VERSION "dbc-export 1 2026.26.6.5"

NS_ :

BS_:

BU_: ADSP APB APP APS APSB BB BMS CC CMP CMPD CP DAS DI DIF DIR DPB EPAS3P EPAS3S EPASTP EPASTS EPBL EPBR ESP EVSE FC GTW HCML HCMR HVP IBST ICR IDB LS OCS1P PARK PCS PCS2 PM PMF PMR PNCD PTC RADC RCM RCM2 RCM3 RCU SCCM SCM SCS SDCR TAS TCU TCU2 TPMS TRCM UI UIS UMC USM V2G VC VCBATT VCBATT0 VCBATT1 VCBATT2 VCCC VCFRONT VCFRONT1 VCFRONT2 VCLEFT VCRIGHT VCSEAT2L VCSEAT2R VCSEC VEH

BO_ 738 VCLEFT_seatStatus2: 8 VCLEFT
 SG_ VCLEFT_seatStatus2Index M : 0|4@1+ (1,0) [0|15] "" Vector__XXX
 SG_ VCLEFT_frontSeatHeatCurrent m0 : 4|12@1+ (0.01,0) [0|40.95] "A" Vector__XXX
 SG_ VCLEFT_frontSeatHeatDuty m0 : 16|8@1+ (1,0) [0|255] "%" Vector__XXX
 SG_ VCLEFT_frontSeatHeatTmp m0 : 24|12@1- (0.05,0) [-40|80] "degC" Vector__XXX
 SG_ VCLEFT_frontSeatHeatTmpTarget m0 : 36|8@1- (0.5,0) [0|60] "degC" Vector__XXX
 SG_ VCLEFT_frontSeatHeatInhibited m0 : 44|1@1+ (1,0) [0|1] "" Vector__XXX
 SG_ VCLEFT_frontSeatHeatPowered m0 : 45|1@1+ (1,0) [0|1] "" Vector__XXX
 SG_ VCLEFT_2RowSeatFoldLeftSwitch m0 : 46|2@1+ (1,0) [0|3] "" Vector__XXX
 SG_ VCLEFT_2RowSeatUnfoldLeftSwitch m0 : 48|2@1+ (1,0) [0|3] "" Vector__XXX
 SG_ VCLEFT_2RowSeatFoldRightSwitch m0 : 50|2@1+ (1,0) [0|3] "" Vector__XXX
 SG_ VCLEFT_2RowSeatUnfoldRightSwitch m0 : 52|2@1+ (1,0) [0|3] "" Vector__XXX
 SG_ VCLEFT_3RowSeatFoldLeftSwitch m0 : 54|2@1+ (1,0) [0|3] "" Vector__XXX
 SG_ VCLEFT_3RowSeatUnfoldLeftSwitch m0 : 56|2@1+ (1,0) [0|3] "" Vector__XXX
 SG_ VCLEFT_3RowSeatFoldRightSwitch m0 : 58|2@1+ (1,0) [0|3] "" Vector__XXX
 SG_ VCLEFT_3RowSeatUnfoldRightSwitch m0 : 60|2@1+ (1,0) [0|3] "" Vector__XXX
 SG_ VC_AH_1RowLeftSeatHeatVentHealth m0 : 62|2@1+ (1,0) [0|3] "" Vector__XXX
 SG_ VCLEFT_2RowSeatReclineState m11 : 4|4@1+ (1,0) [0|15] "" Vector__XXX
 SG_ VCLEFT_2RowSeatReclineDuty m11 : 8|8@1- (1,0) [-100|100] "%" Vector__XXX
 SG_ VCLEFT_2RowSeatReclineCurrent m11 : 16|12@1- (0.05,0) [-100|100] "A" Vector__XXX
 SG_ VCLEFT_2RowSeatReclineCalibrated m11 : 28|1@1+ (1,0) [0|1] "" Vector__XXX
 SG_ VCLEFT_2RowSeatReclinePositionRa m11 : 29|12@1- (1,0) [-2048|2047] "" Vector__XXX
 SG_ VCLEFT_2RowSeatReclineAngle m11 : 41|12@1- (0.1,0) [-204.8|204.7] "deg" Vector__XXX
 SG_ VCLEFT_2RowSeatReclineAbsPosSwit m11 : 53|2@1+ (1,0) [0|3] "" Vector__XXX
 SG_ VCLEFT_2RowSeatReclinePositionSt m12 : 4|3@1+ (1,0) [0|7] "" Vector__XXX
 SG_ VCLEFT_2RowSeatReclineAdjustment m12 : 7|1@1+ (1,0) [0|1] "" Vector__XXX
 SG_ VCLEFT_2RowSeatReclineFoldAllowe m12 : 8|1@1+ (1,0) [0|1] "" Vector__XXX
 SG_ VCLEFT_2RowSeatReclineUnfoldAllo m12 : 9|1@1+ (1,0) [0|1] "" Vector__XXX
 SG_ VCLEFT_2RowSeatReclineNextToggle m12 : 10|2@1+ (1,0) [0|3] "" Vector__XXX
 SG_ VCLEFT_2RowSeatReclineChoreoBloc m12 : 12|1@1+ (1,0) [0|1] "" Vector__XXX
 SG_ VCLEFT_2RowSeat1RClashAvoidanceB m12 : 13|3@1+ (1,0) [0|7] "" Vector__XXX
 SG_ VCLEFT_2RowSeat1RClashAvoidanceS m12 : 16|2@1+ (1,0) [0|3] "" Vector__XXX
 SG_ VCLEFT_2RowSeatReclineAbsPo_0001 m12 : 18|12@1- (0.1,0) [-204.8|204.7] "deg" Vector__XXX
 SG_ VC_AH_2RowLeftSeatMovementHealth m12 : 61|3@1+ (1,0) [0|7] "" Vector__XXX
 SG_ VCLEFT_3RowSeatReclineState m14 : 4|4@1+ (1,0) [0|15] "" Vector__XXX
 SG_ VCLEFT_3RowSeatReclineDuty m14 : 8|8@1- (1,0) [-100|100] "%" Vector__XXX
 SG_ VCLEFT_3RowSeatReclineCurrent m14 : 16|12@1- (0.05,0) [-100|100] "A" Vector__XXX
 SG_ VCLEFT_3RowSeatReclineCalibrated m14 : 28|1@1+ (1,0) [0|1] "" Vector__XXX
 SG_ VCLEFT_3RowSeatReclinePositionRa m14 : 29|12@1- (1,0) [-2048|2047] "" Vector__XXX
 SG_ VCLEFT_3RowSeatReclineAngle m14 : 41|12@1- (0.1,0) [-204.8|204.7] "deg" Vector__XXX
 SG_ VCLEFT_3RowSeatReclineNextToggle m14 : 53|2@1+ (1,0) [0|3] "" Vector__XXX
 SG_ VCLEFT_3RRightCushionHeatCurrent m15 : 4|12@1+ (0.01,0) [0|40.95] "A" Vector__XXX
 SG_ VCLEFT_3RRightCushionHeatDuty m15 : 16|8@1- (1,0) [-100|100] "%" Vector__XXX
 SG_ VCLEFT_3RRightCushionHeatTmp m15 : 24|12@1- (0.05,0) [-40|80] "degC" Vector__XXX
 SG_ VCLEFT_3RRightCushionHeatTmpTarg m15 : 36|8@1- (0.5,0) [0|60] "degC" Vector__XXX
 SG_ VCLEFT_3RRightCushionHeatInhibit m15 : 44|1@1+ (1,0) [0|1] "" Vector__XXX
 SG_ VCLEFT_3RowSeatReclinePositionSt m15 : 46|3@1+ (1,0) [0|7] "" Vector__XXX
 SG_ VCLEFT_3RowSeatReclineAdjustment m15 : 49|1@1+ (1,0) [0|1] "" Vector__XXX
 SG_ VCLEFT_3RowSeatReclineFoldAllowe m15 : 50|1@1+ (1,0) [0|1] "" Vector__XXX
 SG_ VCLEFT_3RowSeatReclineUnfoldAllo m15 : 51|1@1+ (1,0) [0|1] "" Vector__XXX
 SG_ VCLEFT_3RowSeatReclineChoreoBloc m15 : 52|1@1+ (1,0) [0|1] "" Vector__XXX
 SG_ VCLEFT_3RowSeatReclineAbsPosSwit m15 : 53|2@1+ (1,0) [0|3] "" Vector__XXX

BO_ 930 VCLEFT_status: 8 VCLEFT
 SG_ VCLEFT_statusIndex M : 0|2@1+ (1,0) [0|3] "" Vector__XXX
 SG_ VCLEFT_securityControllerEnable m0 : 5|1@1+ (1,0) [0|1] "" Vector__XXX
 SG_ VCLEFT_securityControllerVoltage m0 : 6|5@1+ (0.625,0) [0|19.375] "V" Vector__XXX
 SG_ VCLEFT_consoleDoorAssist m0 : 11|1@1+ (1,0) [0|1] "" Vector__XXX
 SG_ VCLEFT_OTAState m0 : 12|1@1+ (1,0) [0|1] "" Vector__XXX
 SG_ VCLEFT_5AVoltage m0 : 13|10@1+ (0.005443676,0) [0|5.568880548] "V" Vector__XXX
 SG_ VCLEFT_vbatProt m0 : 23|12@1+ (0.005443676,0) [0|22.29185322] "V" Vector__XXX
 SG_ VCLEFT_footwellLightCurrent m0 : 35|12@1- (0.1,0) [-204.8|204.7] "mA" Vector__XXX
 SG_ VCLEFT_swcInputVoltage m0 : 47|8@1+ (0.1,0) [0|25.4] "V" Vector__XXX
 SG_ VCLEFT_swcPCBATemperature m0 : 55|8@1- (1,68) [-59|195] "degC" Vector__XXX
 SG_ VCLEFT_obdEthernetActive m0 : 63|1@1+ (1,0) [0|1] "" Vector__XXX
 SG_ VCLEFT_rationalityAggregateCurre m1 : 12|8@1+ (0.5,0) [0|127.5] "A" Vector__XXX
 SG_ VCLEFT_LVBatteryTypeDBG m1 : 20|3@1+ (1,0) [0|7] "" Vector__XXX
 SG_ VCLEFT_DIeFuseFault m1 : 24|1@1+ (1,0) [0|1] "" Vector__XXX
 SG_ VCLEFT_eFuseMgmtVoltageMonitor m1 : 25|7@1+ (0.125,0) [0|15.875] "V" Vector__XXX
 SG_ VCLEFT_trailerAuxCurrent m1 : 32|12@1+ (0.025,0) [0|102.35] "A" Vector__XXX
 SG_ VCLEFT_swcHeatTmp m1 : 44|10@1+ (0.1,-35) [-35|65] "degC" Vector__XXX
 SG_ VCLEFT_swcHeatStatus m1 : 54|3@1+ (1,0) [0|7] "" Vector__XXX
 SG_ VCLEFT_swcHeatInhibited m1 : 57|1@1+ (1,0) [0|1] "" Vector__XXX
 SG_ VCLEFT_obdDeviceDetected m1 : 58|1@1+ (1,0) [0|1] "" Vector__XXX
 SG_ VCLEFT_pcbaTemperature m2 : 4|11@1+ (0.125,-40) [-40|150] "degC" Vector__XXX
 SG_ VCLEFT_swcHeatPwr m2 : 15|9@1+ (0.5,0) [0|254] "W" Vector__XXX
 SG_ VCLEFT_swcHeatDutyCycle m2 : 24|7@1+ (1,0) [0|100] "%" Vector__XXX
 SG_ VCLEFT_DIeFuseCurrent m2 : 31|6@1+ (0.1,0) [0|6.3] "A" Vector__XXX
 SG_ VCLEFT_SWCpresent m2 : 37|1@1+ (1,0) [0|1] "" Vector__XXX
 SG_ VCLEFT_trailerBrakeControllerCur m2 : 38|8@1+ (0.1,0) [0|25.5] "A" Vector__XXX
 SG_ VCLEFT_autonomyBehaviorStatus m2 : 46|2@1+ (1,0) [0|3] "" Vector__XXX
 SG_ VCLEFT_thirdRowLeftMapLightStatu m2 : 48|2@1+ (1,0) [0|3] "" Vector__XXX
 SG_ VCLEFT_thirdRowRightMapLightStat m2 : 50|2@1+ (1,0) [0|3] "" Vector__XXX

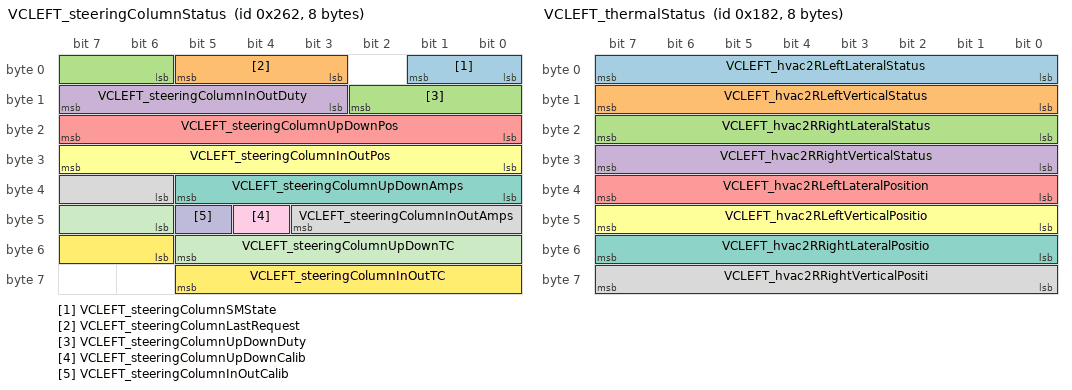
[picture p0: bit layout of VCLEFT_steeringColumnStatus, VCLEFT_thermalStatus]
BO_ 610 VCLEFT_steeringColumnStatus: 8 VCLEFT
 SG_ VCLEFT_steeringColumnSMState : 0|2@1+ (1,0) [0|3] "" Vector__XXX
 SG_ VCLEFT_steeringColumnLastRequest : 3|3@1+ (1,0) [0|7] "" Vector__XXX
 SG_ VCLEFT_steeringColumnUpDownDuty : 6|5@1- (7,0) [-100|100] "%" Vector__XXX
 SG_ VCLEFT_steeringColumnInOutDuty : 11|5@1- (7,0) [-100|100] "%" Vector__XXX
 SG_ VCLEFT_steeringColumnUpDownPos : 16|8@1- (1,103) [-25|230] "mm" Vector__XXX
 SG_ VCLEFT_steeringColumnInOutPos : 24|8@1- (1,103) [-25|230] "mm" Vector__XXX
 SG_ VCLEFT_steeringColumnUpDownAmps : 32|6@1- (0.63,0) [-20|19.53] "A" Vector__XXX
 SG_ VCLEFT_steeringColumnInOutAmps : 38|6@1- (0.63,0) [-20|19.53] "A" Vector__XXX
 SG_ VCLEFT_steeringColumnUpDownCalib : 44|1@1+ (1,0) [0|1] "" Vector__XXX
 SG_ VCLEFT_steeringColumnInOutCalib : 45|1@1+ (1,0) [0|1] "" Vector__XXX
 SG_ VCLEFT_steeringColumnUpDownTC : 46|8@1+ (0.5,-10) [-10|117.5] "s" Vector__XXX
 SG_ VCLEFT_steeringColumnInOutTC : 54|8@1+ (0.5,-10) [-10|117.5] "s" Vector__XXX

BO_ 962 VCLEFT_switchStatus: 8 VCLEFT
 SG_ VCLEFT_switchStatusIndex M : 0|1@1+ (1,0) [0|1] "" Vector__XXX
 SG_ VCLEFT_hornSwitchPressed m0 : 2|1@1+ (1,0) [0|1] "" Vector__XXX
 SG_ VCLEFT_hazardButtonPressed m0 : 3|1@1+ (1,0) [0|1] "" Vector__XXX
 SG_ VCLEFT_brakeSwitchPressed m0 : 4|1@1+ (1,0) [0|1] "" Vector__XXX
 SG_ VCLEFT_rightMirrorTilt m0 : 5|3@1+ (1,0) [0|7] "" Vector__XXX
 SG_ VCLEFT_frontSeatTrackBack m0 : 8|2@1+ (1,0) [0|3] "" Vector__XXX
 SG_ VCLEFT_frontSeatTrackForward m0 : 10|2@1+ (1,0) [0|3] "" Vector__XXX
 SG_ VCLEFT_frontSeatTiltDown m0 : 12|2@1+ (1,0) [0|3] "" Vector__XXX
 SG_ VCLEFT_frontSeatTiltUp m0 : 14|2@1+ (1,0) [0|3] "" Vector__XXX
 SG_ VCLEFT_frontSeatLiftDown m0 : 16|2@1+ (1,0) [0|3] "" Vector__XXX
 SG_ VCLEFT_frontSeatLiftUp m0 : 18|2@1+ (1,0) [0|3] "" Vector__XXX
 SG_ VCLEFT_frontSeatBackrestBack m0 : 20|2@1+ (1,0) [0|3] "" Vector__XXX
 SG_ VCLEFT_frontSeatBackrestForward m0 : 22|2@1+ (1,0) [0|3] "" Vector__XXX
 SG_ VCLEFT_frontSeatLumbarDown m0 : 24|2@1+ (1,0) [0|3] "" Vector__XXX
 SG_ VCLEFT_frontSeatLumbarUp m0 : 26|2@1+ (1,0) [0|3] "" Vector__XXX
 SG_ VCLEFT_frontSeatLumbarIn m0 : 28|2@1+ (1,0) [0|3] "" Vector__XXX
 SG_ VCLEFT_frontSeatLumbarOut m0 : 30|2@1+ (1,0) [0|3] "" Vector__XXX
 SG_ VCLEFT_btnWindowSwPackUpLF m0 : 32|1@1+ (1,0) [0|1] "" Vector__XXX
 SG_ VCLEFT_btnWindowSwPackAutoUpLF m0 : 33|1@1+ (1,0) [0|1] "" Vector__XXX
 SG_ VCLEFT_btnWindowSwPackDownLF m0 : 34|1@1+ (1,0) [0|1] "" Vector__XXX
 SG_ VCLEFT_btnWindowSwPackAutoDownLF m0 : 35|1@1+ (1,0) [0|1] "" Vector__XXX
 SG_ VCLEFT_btnWindowSwPackUpLR m0 : 36|1@1+ (1,0) [0|1] "" Vector__XXX
 SG_ VCLEFT_btnWindowSwPackAutoUpLR m0 : 37|1@1+ (1,0) [0|1] "" Vector__XXX
 SG_ VCLEFT_btnWindowSwPackDownLR m0 : 38|1@1+ (1,0) [0|1] "" Vector__XXX
 SG_ VCLEFT_btnWindowSwPackAutoDownLR m0 : 39|1@1+ (1,0) [0|1] "" Vector__XXX
 SG_ VCLEFT_btnWindowSwPackUpRF m0 : 40|1@1+ (1,0) [0|1] "" Vector__XXX
 SG_ VCLEFT_btnWindowSwPackAutoUpRF m0 : 41|1@1+ (1,0) [0|1] "" Vector__XXX
 SG_ VCLEFT_btnWindowSwPackDownRF m0 : 42|1@1+ (1,0) [0|1] "" Vector__XXX
 SG_ VCLEFT_btnWindowSwPackAutoDownRF m0 : 43|1@1+ (1,0) [0|1] "" Vector__XXX
 SG_ VCLEFT_btnWindowSwPackUpRR m0 : 44|1@1+ (1,0) [0|1] "" Vector__XXX
 SG_ VCLEFT_btnWindowSwPackAutoUpRR m0 : 45|1@1+ (1,0) [0|1] "" Vector__XXX
 SG_ VCLEFT_btnWindowSwPackDownRR m0 : 46|1@1+ (1,0) [0|1] "" Vector__XXX
 SG_ VCLEFT_btnWindowSwPackAutoDownRR m0 : 47|1@1+ (1,0) [0|1] "" Vector__XXX
 SG_ VCLEFT_frontBuckleSwitch m0 : 48|2@1+ (1,0) [0|3] "" Vector__XXX
 SG_ VCLEFT_frontOccupancySwitch m0 : 50|2@1+ (1,0) [0|3] "" Vector__XXX
 SG_ VCLEFT_rearLeftBuckleSwitch m0 : 52|2@1+ (1,0) [0|3] "" Vector__XXX
 SG_ VCLEFT_rearCenterOccupancySwitch m0 : 54|2@1+ (1,0) [0|3] "" Vector__XXX
 SG_ VCLEFT_rearLeftOccupancySwitch m0 : 56|2@1+ (1,0) [0|3] "" Vector__XXX
 SG_ VCLEFT_rearRightOccupancySwitch m0 : 58|2@1+ (1,0) [0|3] "" Vector__XXX
 SG_ VCLEFT_brakePressed m0 : 60|1@1+ (1,0) [0|1] "" Vector__XXX
 SG_ VCLEFT_rearHVACButtonPressed m0 : 61|1@1+ (1,0) [0|1] "" Vector__XXX
 SG_ VCLEFT_rearCenterBuckleSwitch m0 : 62|2@1+ (1,0) [0|3] "" Vector__XXX
 SG_ VCLEFT_isAlcoholInterlockSet m1 : 2|1@1+ (1,0) [0|1] "" Vector__XXX
 SG_ VCLEFT_swcLeftTiltRight m1 : 3|2@1+ (1,0) [0|3] "" Vector__XXX
 SG_ VCLEFT_swcLeftPressed m1 : 5|2@1+ (1,0) [0|3] "" Vector__XXX
 SG_ VCLEFT_swcRightTiltLeft m1 : 8|2@1+ (1,0) [0|3] "" Vector__XXX
 SG_ VCLEFT_swcRightTiltRight m1 : 10|2@1+ (1,0) [0|3] "" Vector__XXX
 SG_ VCLEFT_swcRightPressed m1 : 12|2@1+ (1,0) [0|3] "" Vector__XXX
 SG_ VCLEFT_swcLeftTiltLeft m1 : 14|2@1+ (1,0) [0|3] "" Vector__XXX
 SG_ VCLEFT_swcLeftScrollTicks m1 : 16|6@1- (1,0) [-32|31] "" Vector__XXX
 SG_ VCLEFT_swcWiperButtonState m1 : 22|2@1+ (1,0) [0|3] "" Vector__XXX
 SG_ VCLEFT_swcRightScrollTicks m1 : 24|6@1- (1,0) [-32|31] "" Vector__XXX
 SG_ VCLEFT_swcTurnSignalLeftButtonSt m1 : 30|2@1+ (1,0) [0|3] "" Vector__XXX
 SG_ VCLEFT_btnWindowUpLR m1 : 32|1@1+ (1,0) [0|1] "" Vector__XXX
 SG_ VCLEFT_btnWindowAutoUpLR m1 : 33|1@1+ (1,0) [0|1] "" Vector__XXX
 SG_ VCLEFT_btnWindowDownLR m1 : 34|1@1+ (1,0) [0|1] "" Vector__XXX
 SG_ VCLEFT_btnWindowAutoDownLR m1 : 35|1@1+ (1,0) [0|1] "" Vector__XXX
 SG_ VCLEFT_2RowSeatReclineSwitch m1 : 36|1@1+ (1,0) [0|1] "" Vector__XXX
 SG_ VCLEFT_2RowSeatCenterSwitch m1 : 37|1@1+ (1,0) [0|1] "" Vector__XXX
 SG_ VCLEFT_2RowSeatLeftFoldFlatSwitc m1 : 38|1@1+ (1,0) [0|1] "" Vector__XXX
 SG_ VCLEFT_2RowSeatRightFoldFlatSwit m1 : 39|1@1+ (1,0) [0|1] "" Vector__XXX
 SG_ VCLEFT_2RowSeatBothFoldFlatSwitc m1 : 40|1@1+ (1,0) [0|1] "" Vector__XXX
 SG_ VCLEFT_swcLeftDoublePress m1 : 41|1@1+ (1,0) [0|1] "" Vector__XXX
 SG_ VCLEFT_swcRightDoublePress m1 : 42|1@1+ (1,0) [0|1] "" Vector__XXX
 SG_ VCLEFT_2RowSeatBackrestFoldSwitc m1 : 43|1@1+ (1,0) [0|1] "" Vector__XXX
 SG_ VCLEFT_swcTurnSignalRightButtonS m1 : 44|2@1+ (1,0) [0|3] "" Vector__XXX
 SG_ VCLEFT_swcHighBeamButtonState m1 : 46|2@1+ (1,0) [0|3] "" Vector__XXX
 SG_ VCLEFT_swcVoiceControlPress m1 : 48|2@1+ (1,0) [0|3] "" Vector__XXX
 SG_ VCLEFT_swcCameraButtonState m1 : 50|2@1+ (1,0) [0|3] "" Vector__XXX
 SG_ VCLEFT_swcRightPressedQF m1 : 52|1@1+ (1,0) [0|1] "" Vector__XXX
 SG_ VCLEFT_2RowSeatReclineSwitchpack m1 : 53|3@1+ (1,0) [0|7] "" Vector__XXX
 SG_ VCLEFT_3RowLeftBuckleSwitch m1 : 56|2@1+ (1,0) [0|3] "" Vector__XXX
 SG_ VCLEFT_frontSeatThighSupportExte m1 : 58|2@1+ (1,0) [0|3] "" Vector__XXX
 SG_ VCLEFT_frontSeatThighSupportRetr m1 : 60|2@1+ (1,0) [0|3] "" Vector__XXX
 SG_ VCLEFT_frontSeatResistiveOccupan m1 : 62|2@1+ (1,0) [0|3] "" Vector__XXX

BO_ 656 VCLEFT_thermalLogging10Hz: 8 VCLEFT
 SG_ VCLEFT_thermalLogging10HzIndex M : 0|3@1+ (1,0) [0|7] "" Vector__XXX
 SG_ VCLEFT_hvac2RLeftLateralVoltage m2 : 8|8@1+ (0.02,0) [0|5] "V" Vector__XXX
 SG_ VCLEFT_hvac2RLeftVerticalVoltage m2 : 16|8@1+ (0.02,0) [0|5] "V" Vector__XXX
 SG_ VCLEFT_hvac2RRightLateralVoltage m2 : 24|8@1+ (0.02,0) [0|5] "V" Vector__XXX
 SG_ VCLEFT_hvac2RRightVerticalVoltag m2 : 32|8@1+ (0.02,0) [0|5] "V" Vector__XXX
 SG_ VCLEFT_hvac2RLeftLateralCalibrat m2 : 40|1@1+ (1,0) [0|1] "" Vector__XXX
 SG_ VCLEFT_hvac2RLeftVerticalCalibra m2 : 41|1@1+ (1,0) [0|1] "" Vector__XXX
 SG_ VCLEFT_hvac2RRightLateralCalibra m2 : 42|1@1+ (1,0) [0|1] "" Vector__XXX
 SG_ VCLEFT_hvac2RRightVerticalCalibr m2 : 43|1@1+ (1,0) [0|1] "" Vector__XXX
 SG_ VCLEFT_hvac2RLeftLateralState m2 : 44|4@1+ (1,0) [0|15] "" Vector__XXX
 SG_ VCLEFT_hvac2RLeftVerticalState m2 : 48|4@1+ (1,0) [0|15] "" Vector__XXX
 SG_ VCLEFT_hvac2RRightLateralState m2 : 52|4@1+ (1,0) [0|15] "" Vector__XXX
 SG_ VCLEFT_hvac2RRightVerticalState m2 : 56|4@1+ (1,0) [0|15] "" Vector__XXX
 SG_ VCLEFT_hvacBlowerWindmillElecRpm m3 : 3|14@1+ (1,0) [0|16383] "RPM" Vector__XXX
 SG_ VCLEFT_hvac2RRightVerticalVeloci m3 : 17|8@1- (1,0) [-100|100] "deg/s" Vector__XXX
 SG_ VCLEFT_hvacBlowerWindmillBemf m3 : 25|14@1+ (4,0) [0|65532] "mV" Vector__XXX
 SG_ VCLEFT_hvac2RLeftVerticalVelocit m3 : 39|8@1- (1,0) [-100|100] "deg/s" Vector__XXX
 SG_ VCLEFT_hvac2RLeftLateralVelocity m3 : 47|8@1- (1,0) [-100|100] "deg/s" Vector__XXX
 SG_ VCLEFT_vcusbLinSchedule m3 : 55|2@1+ (1,0) [0|3] "" Vector__XXX
 SG_ VCLEFT_hvacBlowerArbState m3 : 57|3@1+ (1,0) [0|7] "" Vector__XXX
 SG_ VCLEFT_hvacBlowerArbResult m3 : 60|2@1+ (1,0) [0|3] "" Vector__XXX
 SG_ VCLEFT_hvac2RLeftLateralDuty m4 : 3|8@1- (1,0) [-100|100] "%" Vector__XXX
 SG_ VCLEFT_hvac2RLeftVerticalDuty m4 : 11|8@1- (1,0) [-100|100] "%" Vector__XXX
 SG_ VCLEFT_hvac2RRightLateralDuty m4 : 19|8@1- (1,0) [-100|100] "%" Vector__XXX
 SG_ VCLEFT_hvac2RRightVerticalDuty m4 : 27|8@1- (1,0) [-100|100] "%" Vector__XXX
 SG_ VCLEFT_hvacBlowerWindmilling m4 : 35|1@1+ (1,0) [0|1] "" Vector__XXX
 SG_ VCLEFT_hvac2RRightLateralVelocit m4 : 36|8@1- (1,0) [-100|100] "deg/s" Vector__XXX
 SG_ VCLEFT_hvacBlower1msOverrunFrequ m4 : 44|10@1+ (1,0) [0|1023] "" Vector__XXX
 SG_ VCLEFT_hvacBlower10msOverrunFreq m4 : 54|7@1+ (1,0) [0|127] "" Vector__XXX

BO_ 657 VCLEFT_thermalLogging1Hz: 8 VCLEFT
 SG_ VCLEFT_thermalLogging1HzIndex M : 0|4@1+ (1,0) [0|15] "" Vector__XXX
 SG_ VCLEFT_hvac2RLeftLateralZeroStop m0 : 8|8@1+ (0.02,0) [0|5] "V" Vector__XXX
 SG_ VCLEFT_hvac2RLeftVerticalZeroSto m0 : 16|8@1+ (0.02,0) [0|5] "V" Vector__XXX
 SG_ VCLEFT_hvac2RRightLateralZeroSto m0 : 24|8@1+ (0.02,0) [0|5] "V" Vector__XXX
 SG_ VCLEFT_hvac2RRightVerticalZeroSt m0 : 32|8@1+ (0.02,0) [0|5] "V" Vector__XXX
 SG_ VCLEFT_hvac2RLeftLateralEndStopV m1 : 8|8@1+ (0.02,0) [0|5] "V" Vector__XXX
 SG_ VCLEFT_hvac2RLeftVerticalEndStop m1 : 16|8@1+ (0.02,0) [0|5] "V" Vector__XXX
 SG_ VCLEFT_hvac2RRightLateralEndStop m1 : 24|8@1+ (0.02,0) [0|5] "V" Vector__XXX
 SG_ VCLEFT_hvac2RRightVerticalEndSto m1 : 32|8@1+ (0.02,0) [0|5] "V" Vector__XXX
 SG_ VCLEFT_hvacBlowerArbCurrent m1 : 40|8@1+ (0.1,0) [0|25.5] "A" Vector__XXX
 SG_ VCLEFT_hvacBlowerTorqueIndexFilt m1 : 48|7@1+ (1,0) [0|127] "%" Vector__XXX

BO_ 386 VCLEFT_thermalStatus: 8 VCLEFT
 SG_ VCLEFT_hvac2RLeftLateralStatus : 0|8@1+ (1,0) [0|255] "" Vector__XXX
 SG_ VCLEFT_hvac2RLeftVerticalStatus : 8|8@1+ (1,0) [0|255] "" Vector__XXX
 SG_ VCLEFT_hvac2RRightLateralStatus : 16|8@1+ (1,0) [0|255] "" Vector__XXX
 SG_ VCLEFT_hvac2RRightVerticalStatus : 24|8@1+ (1,0) [0|255] "" Vector__XXX
 SG_ VCLEFT_hvac2RLeftLateralPosition : 32|8@1+ (0.4,0) [0|100] "%" Vector__XXX
 SG_ VCLEFT_hvac2RLeftVerticalPositio : 40|8@1+ (0.4,0) [0|100] "%" Vector__XXX
 SG_ VCLEFT_hvac2RRightLateralPositio : 48|8@1+ (0.4,0) [0|100] "%" Vector__XXX
 SG_ VCLEFT_hvac2RRightVerticalPositi : 56|8@1+ (0.4,0) [0|100] "%" Vector__XXX

BO_ 706 VCLEFT_windowStatus: 8 VCLEFT
 SG_ VCLEFT_windowStatusIndex M : 0|1@1+ (1,0) [0|1] "" Vector__XXX
 SG_ VCLEFT_windowStateLF m0 : 1|4@1+ (1,0) [0|15] "" Vector__XXX
 SG_ VCLEFT_windowTrimClearMoveReques m0 : 5|2@1+ (1,0) [0|3] "" Vector__XXX
 SG_ VCLEFT_windowDutyLF m0 : 8|6@1- (5,0) [-100|100] "%" Vector__XXX
 SG_ VCLEFT_windowTrimClearActiveRequ m0 : 14|2@1+ (1,0) [0|3] "" Vector__XXX
 SG_ VCLEFT_windowCurrentLF m0 : 16|6@1- (0.5,0) [-15|15] "A" Vector__XXX
 SG_ VCLEFT_windowPositionLF m0 : 22|9@1- (1.25,265) [-50|580] "mm" Vector__XXX
 SG_ VCLEFT_windowCalibratedLF m0 : 32|1@1+ (1,0) [0|1] "" Vector__XXX
 SG_ VCLEFT_windowStateLR m0 : 33|4@1+ (1,0) [0|15] "" Vector__XXX
 SG_ VCLEFT_windowDutyLR m0 : 40|6@1- (5,0) [-100|100] "%" Vector__XXX
 SG_ VCLEFT_windowCurrentLR m0 : 48|6@1- (0.5,0) [-15|15] "A" Vector__XXX
 SG_ VCLEFT_windowPositionLR m0 : 54|9@1- (1.25,265) [-50|580] "mm" Vector__XXX
 SG_ VCLEFT_windowCalibratedLR m0 : 63|1@1+ (1,0) [0|1] "" Vector__XXX
 SG_ VCLEFT_windowThermalTCLF m1 : 1|8@1+ (1,0) [0|255] "s" Vector__XXX
 SG_ VCLEFT_windowThermalModeLF m1 : 9|2@1+ (1,0) [0|3] "" Vector__XXX
 SG_ VCLEFT_windowStopReasonLF m1 : 11|3@1+ (1,0) [0|7] "" Vector__XXX
 SG_ VCLEFT_windowStopReqReasonLF m1 : 14|4@1+ (1,0) [0|15] "" Vector__XXX
 SG_ VCLEFT_windowThermalTCLR m1 : 18|8@1+ (1,0) [0|255] "s" Vector__XXX
 SG_ VCLEFT_windowThermalModeLR m1 : 26|2@1+ (1,0) [0|3] "" Vector__XXX
 SG_ VCLEFT_windowStopReasonLR m1 : 28|3@1+ (1,0) [0|7] "" Vector__XXX
 SG_ VCLEFT_windowStopReqReasonLR m1 : 31|4@1+ (1,0) [0|15] "" Vector__XXX
 SG_ VCLEFT_windowControlStateLF m1 : 35|2@1+ (1,0) [0|3] "" Vector__XXX
 SG_ VCLEFT_windowCtrlUnavailableLF m1 : 38|3@1+ (1,0) [0|7] "" Vector__XXX
 SG_ VCLEFT_windowControlStateLR m1 : 42|2@1+ (1,0) [0|3] "" Vector__XXX
 SG_ VCLEFT_windowCtrlUnavailableLR m1 : 45|3@1+ (1,0) [0|7] "" Vector__XXX
 SG_ VCLEFT_windowPositionStateLF m1 : 49|3@1+ (1,0) [0|7] "" Vector__XXX
 SG_ VCLEFT_windowPositionStateLR m1 : 52|3@1+ (1,0) [0|7] "" Vector__XXX
 SG_ VCLEFT_windowVehGearStateLF m1 : 56|2@1+ (1,0) [0|3] "" Vector__XXX
 SG_ VCLEFT_windowVehGearStateLR m1 : 58|2@1+ (1,0) [0|3] "" Vector__XXX
 SG_ VCLEFT_windowSpeedTableStatusLF m1 : 60|2@1+ (1,0) [0|3] "" Vector__XXX
 SG_ VCLEFT_windowSpeedTableStatusLR m1 : 62|2@1+ (1,0) [0|3] "" Vector__XXX

BO_ 1114 VCRIGHT_AP_hvacState10Hz: 8 VCRIGHT
 SG_ VCRIGHT_AP_hvacState10HzIndex M : 0|2@1+ (1,0) [0|3] "" Vector__XXX
 SG_ VCRIGHT_AP_autoDefogAvailable m0 : 2|1@1+ (1,0) [0|1] "" Vector__XXX
 SG_ VCRIGHT_AP_hvacFlashFoggingDetec m0 : 3|1@1+ (1,0) [0|1] "" Vector__XXX
 SG_ VCRIGHT_AP_hvacModelInitStatus m0 : 4|3@1+ (1,0) [0|7] "" Vector__XXX
 SG_ VCRIGHT_AP_cabinTempWindshield m0 : 7|8@1+ (0.5,-40) [-40|80] "degC" Vector__XXX
 SG_ VCRIGHT_AP_cabinTempSideGlassRig m0 : 15|8@1+ (0.5,-40) [-40|80] "degC" Vector__XXX
 SG_ VCRIGHT_AP_cabinTempSideGlassLef m0 : 23|8@1+ (0.5,-40) [-40|80] "degC" Vector__XXX
 SG_ VCRIGHT_AP_hvacRecircDoorPercent m0 : 31|6@1+ (1.6,0) [0|100] "%" Vector__XXX
 SG_ VCRIGHT_AP_hvacAirDistributionMo m0 : 37|3@1+ (1,0) [0|7] "" Vector__XXX
 SG_ VCRIGHT_AP_hvacEstimateWindshiel m0 : 40|8@1+ (1,0) [0|150] "%" Vector__XXX
 SG_ VCRIGHT_AP_hvacMassflowTarget m0 : 48|8@1+ (1,0) [0|200] "g/s" Vector__XXX
 SG_ VCRIGHT_AP_tempDuctDefrost m0 : 56|8@1+ (0.5,-22) [-22|105] "degC" Vector__XXX
 SG_ VCRIGHT_AP_cameraTurnOnTime m1 : 2|9@1+ (5,0) [0|2540] "min" Vector__XXX
 SG_ VCRIGHT_AP_cameraDefogType m1 : 11|3@1+ (1,0) [0|7] "" Vector__XXX
 SG_ VCRIGHT_ah_hvacFaultSurvivabilit m1 : 14|5@1+ (10,0) [0|300] "sec" Vector__XXX
 SG_ VCRIGHT_ah_defoggingTimeNeeded m1 : 19|5@1+ (1,0) [0|31] "min" Vector__XXX
 SG_ VCRIGHT_AP_cameraFanDutyRequest m1 : 24|7@1+ (1,0) [0|100] "%" Vector__XXX
 SG_ VCRIGHT_ah_defogSystemState m1 : 31|3@1+ (1,0) [0|7] "" Vector__XXX
 SG_ VCRIGHT_AP_turnForwardCameraHeat m1 : 34|4@1+ (1,0) [0|15] "" Vector__XXX
 SG_ VCRIGHT_AP_turnCameraFanOffReaso m1 : 38|3@1+ (1,0) [0|7] "" Vector__XXX
 SG_ VCRIGHT_AP_forwardCameraIntegrat m1 : 41|1@1+ (1,0) [0|1] "" Vector__XXX
 SG_ VCRIGHT_AP_solarFluxOnRightWindo m1 : 48|8@1+ (5,0) [0|1150] "W/m2" Vector__XXX
 SG_ VCRIGHT_AP_solarFluxOnLeftWindow m1 : 56|8@1+ (5,0) [0|1150] "W/m2" Vector__XXX

BO_ 1124 VCRIGHT_AP_hvacState1Hz: 8 VCRIGHT
 SG_ VCRIGHT_AP_hvacState1HzIndex M : 0|1@1+ (1,0) [0|1] "" Vector__XXX
 SG_ VCRIGHT_AP_tempCameraModele_0001 m0 : 2|8@1+ (0.5,-40) [-40|85] "degC" Vector__XXX
 SG_ VCRIGHT_AP_tempCameraModeledWind m0 : 10|8@1+ (0.5,-40) [-40|85] "degC" Vector__XXX
 SG_ VCRIGHT_AP_cameraModeledWin_0001 m0 : 18|7@1+ (1,0) [0|100] "%" Vector__XXX
 SG_ VCRIGHT_AP_cameraModeledWindshie m0 : 25|7@1+ (1,0) [0|100] "%" Vector__XXX
 SG_ VCRIGHT_AP_maxAchievableASideTem m0 : 32|7@1+ (1,-20) [-20|70] "degC" Vector__XXX
 SG_ VCRIGHT_AP_cameraModeledPocketWa m0 : 42|10@1+ (0.04,0) [0|40] "g/kg" Vector__XXX
 SG_ VCRIGHT_AP_humidityModelInitStat m0 : 52|5@1+ (1,0) [0|31] "" Vector__XXX
 SG_ VCRIGHT_AP_humidityModelStatus m0 : 57|5@1+ (1,0) [0|31] "" Vector__XXX

BO_ 549 VCRIGHT_LVPowerState: 8 VCRIGHT
 SG_ VCRIGHT_ptcLVState : 0|2@1+ (1,0) [0|3] "" Vector__XXX
 SG_ VCRIGHT_ocsLVState : 2|2@1+ (1,0) [0|3] "" Vector__XXX
 SG_ VCRIGHT_premAudioLVState : 4|2@1+ (1,0) [0|3] "" Vector__XXX
 SG_ VCRIGHT_rearOilPumpLVState : 6|2@1+ (1,0) [0|3] "" Vector__XXX
 SG_ VCRIGHT_tunerLVState : 8|2@1+ (1,0) [0|3] "" Vector__XXX
 SG_ VCRIGHT_hvcLVState : 10|2@1+ (1,0) [0|3] "" Vector__XXX
 SG_ VCRIGHT_rcmLVState : 12|2@1+ (1,0) [0|3] "" Vector__XXX
 SG_ VCRIGHT_lumbarLVState : 14|2@1+ (1,0) [0|3] "" Vector__XXX
 SG_ VCRIGHT_3RUSBPowered : 16|1@1+ (1,0) [0|1] "" Vector__XXX
 SG_ VCRIGHT_cntctrPwrState : 17|1@1+ (1,0) [0|1] "" Vector__XXX
 SG_ VCRIGHT_eFuseLockoutStatus : 18|2@1+ (1,0) [0|3] "" Vector__XXX
 SG_ VCRIGHT_swEnStatus : 20|1@1+ (1,0) [0|1] "" Vector__XXX
 SG_ VCRIGHT_vehiclePowerStateDBG : 21|2@1+ (1,0) [0|3] "" Vector__XXX
 SG_ VCRIGHT_parkLVState : 23|2@1+ (1,0) [0|3] "" Vector__XXX
 SG_ VCRIGHT_icrLVState : 25|2@1+ (1,0) [0|3] "" Vector__XXX
 SG_ VCRIGHT_interiorCameraLedLVState : 27|2@1+ (1,0) [0|3] "" Vector__XXX
 SG_ VCRIGHT_diLVState : 29|2@1+ (1,0) [0|3] "" Vector__XXX
 SG_ VCRIGHT_accDevicesDetected : 31|1@1+ (1,0) [0|1] "" Vector__XXX

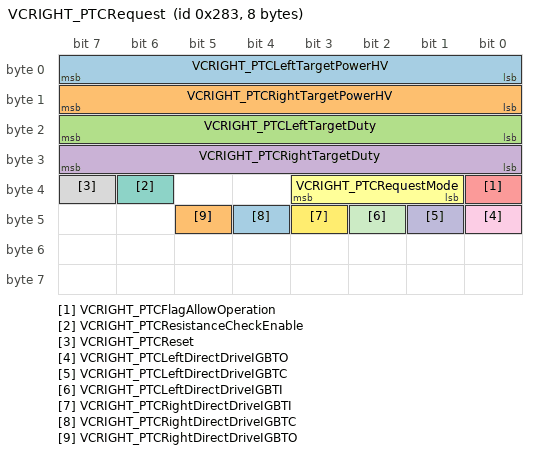
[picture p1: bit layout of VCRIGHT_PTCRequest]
BO_ 643 VCRIGHT_PTCRequest: 8 VCRIGHT
 SG_ VCRIGHT_PTCLeftTargetPowerHV : 0|8@1+ (30,0) [0|7650] "W" Vector__XXX
 SG_ VCRIGHT_PTCRightTargetPowerHV : 8|8@1+ (30,0) [0|7650] "W" Vector__XXX
 SG_ VCRIGHT_PTCLeftTargetDuty : 16|8@1+ (0.5,0) [0|100] "%" Vector__XXX
 SG_ VCRIGHT_PTCRightTargetDuty : 24|8@1+ (0.5,0) [0|100] "%" Vector__XXX
 SG_ VCRIGHT_PTCFlagAllowOperation : 32|1@1+ (1,0) [0|1] "" Vector__XXX
 SG_ VCRIGHT_PTCRequestMode : 33|3@1+ (1,0) [0|7] "" Vector__XXX
 SG_ VCRIGHT_PTCResistanceCheckEnable : 38|1@1+ (1,0) [0|1] "" Vector__XXX
 SG_ VCRIGHT_PTCReset : 39|1@1+ (1,0) [0|1] "" Vector__XXX
 SG_ VCRIGHT_PTCLeftDirectDriveIGBTO : 40|1@1+ (1,0) [0|1] "" Vector__XXX
 SG_ VCRIGHT_PTCLeftDirectDriveIGBTC : 41|1@1+ (1,0) [0|1] "" Vector__XXX
 SG_ VCRIGHT_PTCLeftDirectDriveIGBTI : 42|1@1+ (1,0) [0|1] "" Vector__XXX
 SG_ VCRIGHT_PTCRightDirectDriveIGBTI : 43|1@1+ (1,0) [0|1] "" Vector__XXX
 SG_ VCRIGHT_PTCRightDirectDriveIGBTC : 44|1@1+ (1,0) [0|1] "" Vector__XXX
 SG_ VCRIGHT_PTCRightDirectDriveIGBTO : 45|1@1+ (1,0) [0|1] "" Vector__XXX

BO_ 2011 VCRIGHT_alertLog: 8 VCRIGHT
 SG_ VCRIGHT_alertID M : 0|10@1+ (1,0) [0|1023] "" Vector__XXX
 SG_ VCRIGHT_alertState : 15|1@1+ (1,0) [0|1] "" Vector__XXX
 SG_ VCRIGHT_a001_InternalWatchdog m1 : 16|1@1+ (1,0) [0|1] "" Vector__XXX
 SG_ VCRIGHT_a010_UnderVoltageDetecte m10 : 16|1@1+ (1,0) [0|1] "" Vector__XXX
 SG_ VCRIGHT_a010_UnderVoltageTimeout m10 : 17|1@1+ (1,0) [0|1] "" Vector__XXX
 SG_ VCRIGHT_a015_NVMMMemOverflow m15 : 16|1@1+ (1,0) [0|1] "" Vector__XXX
 SG_ VCRIGHT_a015_NVMMFilesystemError m15 : 17|1@1+ (1,0) [0|1] "" Vector__XXX
 SG_ VCRIGHT_a015_NVMMRecordIDError m15 : 18|1@1+ (1,0) [0|1] "" Vector__XXX
 SG_ VCRIGHT_a057_VEH_cpControl m57 : 16|1@1+ (1,0) [0|1] "" Vector__XXX
 SG_ VCRIGHT_a059_voltageDrop m59 : 16|12@1+ (0.005443676,0) [0|22.29185322] "" Vector__XXX
 SG_ VCRIGHT_a059_resistanceEstimate m59 : 28|12@1+ (0.00244,0) [0|9.9918] "" Vector__XXX
 SG_ VCRIGHT_a059_current m59 : 40|12@1+ (0.05,0) [0|204.75] "" Vector__XXX
 SG_ VCRIGHT_a063_switchChannel m63 : 16|8@1+ (1,0) [0|255] "" Vector__XXX
 SG_ VCRIGHT_a063_switchType m63 : 24|8@1+ (1,0) [0|255] "" Vector__XXX
 SG_ VCRIGHT_a063_ADCVoltage m63 : 32|8@1+ (0.025,0) [0|6.375] "" Vector__XXX
 SG_ VCRIGHT_a063_disconnected m63 : 40|1@1+ (1,0) [0|1] "" Vector__XXX
 SG_ VCRIGHT_a063_indeterminate m63 : 41|1@1+ (1,0) [0|1] "" Vector__XXX
 SG_ VCRIGHT_a063_stuckActive m63 : 42|1@1+ (1,0) [0|1] "" Vector__XXX
 SG_ VCRIGHT_a063_faulted m63 : 43|1@1+ (1,0) [0|1] "" Vector__XXX
 SG_ VCRIGHT_a082_RIPC_epbPrivateStat m82 : 16|1@1+ (1,0) [0|1] "" Vector__XXX
 SG_ VCRIGHT_a082_RIPC_remoteHSD m82 : 17|1@1+ (1,0) [0|1] "" Vector__XXX
 SG_ VCRIGHT_a082_RIPC_railStatus m82 : 18|1@1+ (1,0) [0|1] "" Vector__XXX
 SG_ VCRIGHT_a082_RIPC_remoteMux m82 : 19|1@1+ (1,0) [0|1] "" Vector__XXX
 SG_ VCRIGHT_a083_LIPC_epbPrivateStat m83 : 16|1@1+ (1,0) [0|1] "" Vector__XXX
 SG_ VCRIGHT_a083_LIPC_remoteHSD m83 : 17|1@1+ (1,0) [0|1] "" Vector__XXX
 SG_ VCRIGHT_a083_LIPC_railStatus m83 : 18|1@1+ (1,0) [0|1] "" Vector__XXX
 SG_ VCRIGHT_a083_LIPC_HSDFaults m83 : 19|1@1+ (1,0) [0|1] "" Vector__XXX
 SG_ VCRIGHT_a084_CH_StatusC m84 : 16|1@1+ (1,0) [0|1] "" Vector__XXX
 SG_ VCRIGHT_a085_PARTY_buttonStatus m85 : 16|1@1+ (1,0) [0|1] "" Vector__XXX
 SG_ VCRIGHT_a086_VEH_LVBMS_statusHig m86 : 16|1@1+ (1,0) [0|1] "" Vector__XXX
 SG_ VCRIGHT_a086_VEH_LVBMS_statusLow m86 : 17|1@1+ (1,0) [0|1] "" Vector__XXX
 SG_ VCRIGHT_a086_VEH_status m86 : 18|1@1+ (1,0) [0|1] "" Vector__XXX
 SG_ VCRIGHT_a086_VEH_12VBatteryStatu m86 : 19|1@1+ (1,0) [0|1] "" Vector__XXX
 SG_ VCRIGHT_a086_VEH_LVPowerState m86 : 20|1@1+ (1,0) [0|1] "" Vector__XXX
 SG_ VCRIGHT_a086_VEH_lightStatus m86 : 21|1@1+ (1,0) [0|1] "" Vector__XXX
 SG_ VCRIGHT_a086_VEH_systemStatus m86 : 22|1@1+ (1,0) [0|1] "" Vector__XXX
 SG_ VCRIGHT_a086_VEH_thermalStatus m86 : 23|1@1+ (1,0) [0|1] "" Vector__XXX
 SG_ VCRIGHT_a086_VEH_vehNm m86 : 24|1@1+ (1,0) [0|1] "" Vector__XXX
 SG_ VCRIGHT_a086_BDY_LVSelfTests m86 : 60|1@1+ (1,0) [0|1] "" Vector__XXX
 SG_ VCRIGHT_a086_VEH_LVSelfTests m86 : 61|1@1+ (1,0) [0|1] "" Vector__XXX
 SG_ VCRIGHT_a086_VEH_LVHealth m86 : 62|1@1+ (1,0) [0|1] "" Vector__XXX
 SG_ VCRIGHT_a086_BDY_12VBatteryStatu m86 : 63|1@1+ (1,0) [0|1] "" Vector__XXX
 SG_ VCRIGHT_a087_VEH_temperature m87 : 16|1@1+ (1,0) [0|1] "" Vector__XXX
 SG_ VCRIGHT_a087_VEH_thermalControl m87 : 17|1@1+ (1,0) [0|1] "" Vector__XXX
 SG_ VCRIGHT_a087_VEH_torque m87 : 18|1@1+ (1,0) [0|1] "" Vector__XXX
 SG_ VCRIGHT_a087_VEH_status m87 : 19|1@1+ (1,0) [0|1] "" Vector__XXX
 SG_ VCRIGHT_a087_PARTY_torque m87 : 20|1@1+ (1,0) [0|1] "" Vector__XXX
 SG_ VCRIGHT_a087_PARTY_status m87 : 21|1@1+ (1,0) [0|1] "" Vector__XXX
 SG_ VCRIGHT_a087_PARTY_temperature m87 : 22|1@1+ (1,0) [0|1] "" Vector__XXX
 SG_ VCRIGHT_a087_PARTY_thermalContro m87 : 23|1@1+ (1,0) [0|1] "" Vector__XXX
 SG_ VCRIGHT_a087_VEH_motorStatus m87 : 24|1@1+ (1,0) [0|1] "" Vector__XXX
 SG_ VCRIGHT_a088_VEH_temperature m88 : 16|1@1+ (1,0) [0|1] "" Vector__XXX
 SG_ VCRIGHT_a088_VEH_thermalControl m88 : 17|1@1+ (1,0) [0|1] "" Vector__XXX
 SG_ VCRIGHT_a088_VEH_torque m88 : 18|1@1+ (1,0) [0|1] "" Vector__XXX
 SG_ VCRIGHT_a088_VEH_status m88 : 19|1@1+ (1,0) [0|1] "" Vector__XXX
 SG_ VCRIGHT_a088_PARTY_torque m88 : 20|1@1+ (1,0) [0|1] "" Vector__XXX
 SG_ VCRIGHT_a088_PARTY_status m88 : 21|1@1+ (1,0) [0|1] "" Vector__XXX
 SG_ VCRIGHT_a088_PARTY_temperature m88 : 22|1@1+ (1,0) [0|1] "" Vector__XXX
 SG_ VCRIGHT_a088_PARTY_thermalContro m88 : 23|1@1+ (1,0) [0|1] "" Vector__XXX
 SG_ VCRIGHT_a088_VEH_motorStatus m88 : 24|1@1+ (1,0) [0|1] "" Vector__XXX
 SG_ VCRIGHT_a089_PARTY_party1 m89 : 16|1@1+ (1,0) [0|1] "" Vector__XXX
 SG_ VCRIGHT_a089_PARTY_status m89 : 17|1@1+ (1,0) [0|1] "" Vector__XXX
 SG_ VCRIGHT_a089_VEH_status m89 : 18|1@1+ (1,0) [0|1] "" Vector__XXX
 SG_ VCRIGHT_a089_BDY_party1 m89 : 19|1@1+ (1,0) [0|1] "" Vector__XXX
 SG_ VCRIGHT_a089_BDY_status m89 : 20|1@1+ (1,0) [0|1] "" Vector__XXX
 SG_ VCRIGHT_a089_CH_status m89 : 21|1@1+ (1,0) [0|1] "" Vector__XXX
 SG_ VCRIGHT_a089_CH_party1 m89 : 22|1@1+ (1,0) [0|1] "" Vector__XXX
 SG_ VCRIGHT_a089_CH_party3 m89 : 23|1@1+ (1,0) [0|1] "" Vector__XXX
 SG_ VCRIGHT_a089_VEH_party1 m89 : 24|1@1+ (1,0) [0|1] "" Vector__XXX
 SG_ VCRIGHT_a089_VEH_party3 m89 : 25|1@1+ (1,0) [0|1] "" Vector__XXX
 SG_ VCRIGHT_a091_VEH_faultsAndExtras m91 : 16|1@1+ (1,0) [0|1] "" Vector__XXX
 SG_ VCRIGHT_a091_VEH_info m91 : 17|1@1+ (1,0) [0|1] "" Vector__XXX
 SG_ VCRIGHT_a091_VEH_state m91 : 18|1@1+ (1,0) [0|1] "" Vector__XXX
 SG_ VCRIGHT_a092_VEH_restraintStatus m92 : 16|1@1+ (1,0) [0|1] "" Vector__XXX
 SG_ VCRIGHT_a092_VEH_switchStatus m92 : 17|1@1+ (1,0) [0|1] "" Vector__XXX
 SG_ VCRIGHT_a092_VEH_seatStatus2 m92 : 18|1@1+ (1,0) [0|1] "" Vector__XXX
 SG_ VCRIGHT_a092_VEH_vehNm m92 : 19|1@1+ (1,0) [0|1] "" Vector__XXX
 SG_ VCRIGHT_a093_VEH_restraintStatus m93 : 16|1@1+ (1,0) [0|1] "" Vector__XXX
 SG_ VCRIGHT_a093_VEH_switchStatus m93 : 17|1@1+ (1,0) [0|1] "" Vector__XXX
 SG_ VCRIGHT_a093_VEH_seatStatus2 m93 : 18|1@1+ (1,0) [0|1] "" Vector__XXX
 SG_ VCRIGHT_a093_VEH_vehNm m93 : 19|1@1+ (1,0) [0|1] "" Vector__XXX
 SG_ VCRIGHT_a094_VEH_sysStatus m94 : 16|1@1+ (1,0) [0|1] "" Vector__XXX
 SG_ VCRIGHT_a094_PARTY_sysStatus m94 : 17|1@1+ (1,0) [0|1] "" Vector__XXX
 SG_ VCRIGHT_a094_CH_sysStatus m94 : 18|1@1+ (1,0) [0|1] "" Vector__XXX
 SG_ VCRIGHT_a095_PT_ptNm m95 : 16|1@1+ (1,0) [0|1] "" Vector__XXX
 SG_ VCRIGHT_a095_PT_status m95 : 17|1@1+ (1,0) [0|1] "" Vector__XXX
 SG_ VCRIGHT_a096_VEH_status m96 : 16|1@1+ (1,0) [0|1] "" Vector__XXX
 SG_ VCRIGHT_a096_CH_status m96 : 17|1@1+ (1,0) [0|1] "" Vector__XXX
 SG_ VCRIGHT_a097_VEH_HVStatus m97 : 16|1@1+ (1,0) [0|1] "" Vector__XXX
 SG_ VCRIGHT_a097_VEH_state m97 : 17|1@1+ (1,0) [0|1] "" Vector__XXX
 SG_ VCRIGHT_a098_CH_torque m98 : 16|1@1+ (1,0) [0|1] "" Vector__XXX
 SG_ VCRIGHT_a098_VEH_hvStatus m98 : 17|1@1+ (1,0) [0|1] "" Vector__XXX
 SG_ VCRIGHT_a098_VEH_status m98 : 18|1@1+ (1,0) [0|1] "" Vector__XXX
 SG_ VCRIGHT_a098_VEH_thermalControl m98 : 19|1@1+ (1,0) [0|1] "" Vector__XXX
 SG_ VCRIGHT_a098_VEH_temperature m98 : 20|1@1+ (1,0) [0|1] "" Vector__XXX
 SG_ VCRIGHT_a098_VEH_torque m98 : 21|1@1+ (1,0) [0|1] "" Vector__XXX
 SG_ VCRIGHT_a098_PARTY_status m98 : 22|1@1+ (1,0) [0|1] "" Vector__XXX
 SG_ VCRIGHT_a098_PARTY_temperature m98 : 23|1@1+ (1,0) [0|1] "" Vector__XXX
 SG_ VCRIGHT_a098_PARTY_thermalContro m98 : 24|1@1+ (1,0) [0|1] "" Vector__XXX
 SG_ VCRIGHT_a098_PARTY_torque m98 : 25|1@1+ (1,0) [0|1] "" Vector__XXX
 SG_ VCRIGHT_a098_PT_thermalControl m98 : 26|1@1+ (1,0) [0|1] "" Vector__XXX
 SG_ VCRIGHT_a098_PT_temperature m98 : 27|1@1+ (1,0) [0|1] "" Vector__XXX
 SG_ VCRIGHT_a098_PARTY_motorStatus m98 : 28|1@1+ (1,0) [0|1] "" Vector__XXX
 SG_ VCRIGHT_a098_VEH_motorStatus m98 : 29|1@1+ (1,0) [0|1] "" Vector__XXX
 SG_ VCRIGHT_a099_VEH_oocStatus m99 : 16|1@1+ (1,0) [0|1] "" Vector__XXX
 SG_ VCRIGHT_a100_VEH m100 : 16|1@1+ (1,0) [0|1] "" Vector__XXX
 SG_ VCRIGHT_a100_PARTY m100 : 17|1@1+ (1,0) [0|1] "" Vector__XXX
 SG_ VCRIGHT_a100_PT m100 : 18|1@1+ (1,0) [0|1] "" Vector__XXX
 SG_ VCRIGHT_a100_CH m100 : 19|1@1+ (1,0) [0|1] "" Vector__XXX
 SG_ VCRIGHT_a100_OBD m100 : 20|1@1+ (1,0) [0|1] "" Vector__XXX
 SG_ VCRIGHT_a101_VEH_state m101 : 16|1@1+ (1,0) [0|1] "" Vector__XXX
 SG_ VCRIGHT_a101_PARTY_locState m101 : 17|1@1+ (1,0) [0|1] "" Vector__XXX
 SG_ VCRIGHT_a101_LIPC_externalWatchd m101 : 18|1@1+ (1,0) [0|1] "" Vector__XXX
 SG_ VCRIGHT_a101_VEH_locState m101 : 19|1@1+ (1,0) [0|1] "" Vector__XXX
 SG_ VCRIGHT_a101_BDY_locState m101 : 20|1@1+ (1,0) [0|1] "" Vector__XXX
 SG_ VCRIGHT_a102_VEH_faultsAndExtras m102 : 16|1@1+ (1,0) [0|1] "" Vector__XXX
 SG_ VCRIGHT_a102_VEH_feedbackStatus m102 : 17|1@1+ (1,0) [0|1] "" Vector__XXX
 SG_ VCRIGHT_a102_VEH_sensorStatus m102 : 18|1@1+ (1,0) [0|1] "" Vector__XXX
 SG_ VCRIGHT_a102_VEH_rods m102 : 19|1@1+ (1,0) [0|1] "" Vector__XXX
 SG_ VCRIGHT_a103_VEH_hvsNm m103 : 16|1@1+ (1,0) [0|1] "" Vector__XXX
 SG_ VCRIGHT_a103_VEH_vehNm m103 : 17|1@1+ (1,0) [0|1] "" Vector__XXX
 SG_ VCRIGHT_a103_VEH_status m103 : 18|1@1+ (1,0) [0|1] "" Vector__XXX
 SG_ VCRIGHT_a103_PT_ptNm m103 : 19|1@1+ (1,0) [0|1] "" Vector__XXX
 SG_ VCRIGHT_a103_PT_status m103 : 20|1@1+ (1,0) [0|1] "" Vector__XXX
 SG_ VCRIGHT_a103_VEH_evseStatus m103 : 21|1@1+ (1,0) [0|1] "" Vector__XXX
 SG_ VCRIGHT_a105_VEH_states m105 : 16|1@1+ (1,0) [0|1] "" Vector__XXX
 SG_ VCRIGHT_a105_VEH_chNm m105 : 17|1@1+ (1,0) [0|1] "" Vector__XXX
 SG_ VCRIGHT_a105_VEH_dampingStates m105 : 18|1@1+ (1,0) [0|1] "" Vector__XXX
 SG_ VCRIGHT_a106_VEH_dcdcStatus m106 : 16|1@1+ (1,0) [0|1] "" Vector__XXX
 SG_ VCRIGHT_a106_VEH_thermalControl m106 : 17|1@1+ (1,0) [0|1] "" Vector__XXX
 SG_ VCRIGHT_a106_VEH_dcdcRailStatus m106 : 18|1@1+ (1,0) [0|1] "" Vector__XXX
 SG_ VCRIGHT_a106_CH_dcdcRailStatus m106 : 19|1@1+ (1,0) [0|1] "" Vector__XXX
 SG_ VCRIGHT_a106_CH_alertMatrix m106 : 20|1@1+ (1,0) [0|1] "" Vector__XXX
 SG_ VCRIGHT_a107_VEH_hvsNm m107 : 16|1@1+ (1,0) [0|1] "" Vector__XXX
 SG_ VCRIGHT_a107_VEH_vehNm m107 : 17|1@1+ (1,0) [0|1] "" Vector__XXX
 SG_ VCRIGHT_a107_VEH_status m107 : 18|1@1+ (1,0) [0|1] "" Vector__XXX
 SG_ VCRIGHT_a107_VEH_thermalStatus m107 : 19|1@1+ (1,0) [0|1] "" Vector__XXX
 SG_ VCRIGHT_a107_VEH_bmbMinMax m107 : 20|1@1+ (1,0) [0|1] "" Vector__XXX
 SG_ VCRIGHT_a107_VEH_powerAvailable m107 : 21|1@1+ (1,0) [0|1] "" Vector__XXX
 SG_ VCRIGHT_a107_PT_ptNm m107 : 22|1@1+ (1,0) [0|1] "" Vector__XXX
 SG_ VCRIGHT_a107_PT_status m107 : 23|1@1+ (1,0) [0|1] "" Vector__XXX
 SG_ VCRIGHT_a107_PT_thermalStatus m107 : 24|1@1+ (1,0) [0|1] "" Vector__XXX
 SG_ VCRIGHT_a107_PT_socStatus m107 : 25|1@1+ (1,0) [0|1] "" Vector__XXX
 SG_ VCRIGHT_a107_VEH_socStatus m107 : 26|1@1+ (1,0) [0|1] "" Vector__XXX
 SG_ VCRIGHT_a107_VEH_packConfig m107 : 27|1@1+ (1,0) [0|1] "" Vector__XXX
 SG_ VCRIGHT_a107_VEH_energyStatus m107 : 28|1@1+ (1,0) [0|1] "" Vector__XXX
 SG_ VCRIGHT_a107_VEH_chargeInfo m107 : 29|1@1+ (1,0) [0|1] "" Vector__XXX
 SG_ VCRIGHT_a108_VEH_hvStatus m108 : 16|1@1+ (1,0) [0|1] "" Vector__XXX
 SG_ VCRIGHT_a108_VEH_temperature m108 : 17|1@1+ (1,0) [0|1] "" Vector__XXX
 SG_ VCRIGHT_a108_VEH_thermalControl m108 : 18|1@1+ (1,0) [0|1] "" Vector__XXX
 SG_ VCRIGHT_a108_VEH_torque m108 : 19|1@1+ (1,0) [0|1] "" Vector__XXX
 SG_ VCRIGHT_a108_VEH_status m108 : 20|1@1+ (1,0) [0|1] "" Vector__XXX
 SG_ VCRIGHT_a108_PARTY_torque m108 : 21|1@1+ (1,0) [0|1] "" Vector__XXX
 SG_ VCRIGHT_a108_PARTY_status m108 : 22|1@1+ (1,0) [0|1] "" Vector__XXX
 SG_ VCRIGHT_a108_PARTY_temperature m108 : 23|1@1+ (1,0) [0|1] "" Vector__XXX
 SG_ VCRIGHT_a108_PARTY_thermalContro m108 : 24|1@1+ (1,0) [0|1] "" Vector__XXX
 SG_ VCRIGHT_a108_PT_temperature m108 : 25|1@1+ (1,0) [0|1] "" Vector__XXX
 SG_ VCRIGHT_a108_PT_thermalControl m108 : 26|1@1+ (1,0) [0|1] "" Vector__XXX
 SG_ VCRIGHT_a108_PARTY_motorStatus m108 : 27|1@1+ (1,0) [0|1] "" Vector__XXX
 SG_ VCRIGHT_a108_VEH_motorStatus m108 : 28|1@1+ (1,0) [0|1] "" Vector__XXX
 SG_ VCRIGHT_a108_CH_torque m108 : 29|1@1+ (1,0) [0|1] "" Vector__XXX
 SG_ VCRIGHT_a110_VEH_carState m110 : 16|1@1+ (1,0) [0|1] "" Vector__XXX
 SG_ VCRIGHT_a110_VEH_carConfig m110 : 17|1@1+ (1,0) [0|1] "" Vector__XXX
 SG_ VCRIGHT_a110_VEH_time m110 : 18|1@1+ (1,0) [0|1] "" Vector__XXX
 SG_ VCRIGHT_a110_VEH_updateStatus m110 : 19|1@1+ (1,0) [0|1] "" Vector__XXX
 SG_ VCRIGHT_a110_VEH_vehNm m110 : 20|1@1+ (1,0) [0|1] "" Vector__XXX
 SG_ VCRIGHT_a110_VEH_mismatchFault m110 : 21|1@1+ (1,0) [0|1] "" Vector__XXX
 SG_ VCRIGHT_a110_VEH_vin m110 : 22|1@1+ (1,0) [0|1] "" Vector__XXX
 SG_ VCRIGHT_a110_VEH_bmpDebug m110 : 23|1@1+ (1,0) [0|1] "" Vector__XXX
 SG_ VCRIGHT_a110_VEH_gearControl m110 : 24|1@1+ (1,0) [0|1] "" Vector__XXX
 SG_ VCRIGHT_a110_VEH_canLogAvailabil m110 : 25|1@1+ (1,0) [0|1] "" Vector__XXX
 SG_ VCRIGHT_a110_CH_airbagCutoffStat m110 : 26|1@1+ (1,0) [0|1] "" Vector__XXX
 SG_ VCRIGHT_a110_CH_carConfig m110 : 27|1@1+ (1,0) [0|1] "" Vector__XXX
 SG_ VCRIGHT_a110_CH_carState m110 : 28|1@1+ (1,0) [0|1] "" Vector__XXX
 SG_ VCRIGHT_a110_CH_vin m110 : 29|1@1+ (1,0) [0|1] "" Vector__XXX
 SG_ VCRIGHT_a110_CH_chNm m110 : 30|1@1+ (1,0) [0|1] "" Vector__XXX
 SG_ VCRIGHT_a110_CH_epochTimeGtw m110 : 31|1@1+ (1,0) [0|1] "" Vector__XXX
 SG_ VCRIGHT_a110_PARTY_carConfig m110 : 32|1@1+ (1,0) [0|1] "" Vector__XXX
 SG_ VCRIGHT_a111_VEH_internalStatus m111 : 16|1@1+ (1,0) [0|1] "" Vector__XXX
 SG_ VCRIGHT_a111_VEH_status m111 : 17|1@1+ (1,0) [0|1] "" Vector__XXX
 SG_ VCRIGHT_a111_VEH_vehNm m111 : 18|1@1+ (1,0) [0|1] "" Vector__XXX
 SG_ VCRIGHT_a111_RIPC_LVPowerState m111 : 19|1@1+ (1,0) [0|1] "" Vector__XXX
 SG_ VCRIGHT_a111_RIPC_epbPrivateStat m111 : 20|1@1+ (1,0) [0|1] "" Vector__XXX
 SG_ VCRIGHT_a111_RIPC_railStatus m111 : 21|1@1+ (1,0) [0|1] "" Vector__XXX
 SG_ VCRIGHT_a111_RIPC_remoteADC m111 : 22|1@1+ (1,0) [0|1] "" Vector__XXX
 SG_ VCRIGHT_a111_RIPC_switchStatus m111 : 23|1@1+ (1,0) [0|1] "" Vector__XXX
 SG_ VCRIGHT_a111_VEH_LVPowerState m111 : 24|1@1+ (1,0) [0|1] "" Vector__XXX
 SG_ VCRIGHT_a111_VEH_seatStatus m111 : 25|1@1+ (1,0) [0|1] "" Vector__XXX
 SG_ VCRIGHT_a111_PARTY_status m111 : 26|1@1+ (1,0) [0|1] "" Vector__XXX
 SG_ VCRIGHT_a111_CH_status m111 : 27|1@1+ (1,0) [0|1] "" Vector__XXX
 SG_ VCRIGHT_a112_VEH_internalStatus m112 : 16|1@1+ (1,0) [0|1] "" Vector__XXX
 SG_ VCRIGHT_a112_VEH_status m112 : 17|1@1+ (1,0) [0|1] "" Vector__XXX
 SG_ VCRIGHT_a112_VEH_vehNm m112 : 18|1@1+ (1,0) [0|1] "" Vector__XXX
 SG_ VCRIGHT_a112_LIPC_LVPowerState m112 : 19|1@1+ (1,0) [0|1] "" Vector__XXX
 SG_ VCRIGHT_a112_LIPC_epbPrivateStat m112 : 20|1@1+ (1,0) [0|1] "" Vector__XXX
 SG_ VCRIGHT_a112_LIPC_railStatus m112 : 21|1@1+ (1,0) [0|1] "" Vector__XXX
 SG_ VCRIGHT_a112_LIPC_remoteADC m112 : 22|1@1+ (1,0) [0|1] "" Vector__XXX
 SG_ VCRIGHT_a112_LIPC_switchStatus m112 : 23|1@1+ (1,0) [0|1] "" Vector__XXX
 SG_ VCRIGHT_a112_VEH_LVPowerState m112 : 24|1@1+ (1,0) [0|1] "" Vector__XXX
 SG_ VCRIGHT_a112_PARTY_status m112 : 25|1@1+ (1,0) [0|1] "" Vector__XXX
 SG_ VCRIGHT_a112_CH_status m112 : 26|1@1+ (1,0) [0|1] "" Vector__XXX
 SG_ VCRIGHT_a114_PARTY_status m114 : 16|1@1+ (1,0) [0|1] "" Vector__XXX
 SG_ VCRIGHT_a114_PARTY_wheelSpeeds m114 : 17|1@1+ (1,0) [0|1] "" Vector__XXX
 SG_ VCRIGHT_a114_VEH_wheelSpeeds m114 : 18|1@1+ (1,0) [0|1] "" Vector__XXX
 SG_ VCRIGHT_a114_CH_wheelSpeeds m114 : 19|1@1+ (1,0) [0|1] "" Vector__XXX
 SG_ VCRIGHT_a114_PARTY_party3 m114 : 20|1@1+ (1,0) [0|1] "" Vector__XXX
 SG_ VCRIGHT_a114_VEH_party3 m114 : 21|1@1+ (1,0) [0|1] "" Vector__XXX
 SG_ VCRIGHT_a114_VEH_status m114 : 22|1@1+ (1,0) [0|1] "" Vector__XXX
 SG_ VCRIGHT_a114_PARTY_wheelRotation m114 : 23|1@1+ (1,0) [0|1] "" Vector__XXX
 SG_ VCRIGHT_a114_CH_wheelRotation m114 : 24|1@1+ (1,0) [0|1] "" Vector__XXX
 SG_ VCRIGHT_a114_VEH_wheelRotation m114 : 25|1@1+ (1,0) [0|1] "" Vector__XXX
 SG_ VCRIGHT_a114_PARTY_brakeTorque m114 : 26|1@1+ (1,0) [0|1] "" Vector__XXX
 SG_ VCRIGHT_a114_PARTY_offsets m114 : 27|1@1+ (1,0) [0|1] "" Vector__XXX
 SG_ VCRIGHT_a114_BDY_offsets m114 : 28|1@1+ (1,0) [0|1] "" Vector__XXX
 SG_ VCRIGHT_a114_BDY_party3 m114 : 29|1@1+ (1,0) [0|1] "" Vector__XXX
 SG_ VCRIGHT_a114_BDY_status m114 : 30|1@1+ (1,0) [0|1] "" Vector__XXX
 SG_ VCRIGHT_a114_BDY_wheelRotation m114 : 31|1@1+ (1,0) [0|1] "" Vector__XXX
 SG_ VCRIGHT_a114_BDY_wheelSpeeds m114 : 32|1@1+ (1,0) [0|1] "" Vector__XXX
 SG_ VCRIGHT_a114_CH_party1 m114 : 33|1@1+ (1,0) [0|1] "" Vector__XXX
 SG_ VCRIGHT_a114_CH_party3 m114 : 34|1@1+ (1,0) [0|1] "" Vector__XXX
 SG_ VCRIGHT_a114_CH_status m114 : 35|1@1+ (1,0) [0|1] "" Vector__XXX
 SG_ VCRIGHT_a115_VEH_vehNm m115 : 16|1@1+ (1,0) [0|1] "" Vector__XXX
 SG_ VCRIGHT_a115_VEH_authentication m115 : 17|1@1+ (1,0) [0|1] "" Vector__XXX
 SG_ VCRIGHT_a115_VEH_BLEResetRequest m115 : 18|1@1+ (1,0) [0|1] "" Vector__XXX
 SG_ VCRIGHT_a115_VEH_requests m115 : 19|1@1+ (1,0) [0|1] "" Vector__XXX
 SG_ VCRIGHT_a115_VEH_requests2 m115 : 20|1@1+ (1,0) [0|1] "" Vector__XXX
 SG_ VCRIGHT_a115_REM_authentication m115 : 21|1@1+ (1,0) [0|1] "" Vector__XXX
 SG_ VCRIGHT_a115_UI_corianderVehicle m115 : 22|1@1+ (1,0) [0|1] "" Vector__XXX
 SG_ VCRIGHT_a115_CH_TPMSDisplay m115 : 23|1@1+ (1,0) [0|1] "" Vector__XXX
 SG_ VCRIGHT_a115_VEH_RSSI m115 : 24|1@1+ (1,0) [0|1] "" Vector__XXX
 SG_ VCRIGHT_a115_VEH_authenticationW m115 : 25|1@1+ (1,0) [0|1] "" Vector__XXX
 SG_ VCRIGHT_a115_VEH_endpointTemp m115 : 26|1@1+ (1,0) [0|1] "" Vector__XXX
 SG_ VCRIGHT_a115_VEH_ChildSeatStatus m115 : 27|1@1+ (1,0) [0|1] "" Vector__XXX
 SG_ VCRIGHT_a115_BDY_ChildSeatStatus m115 : 28|1@1+ (1,0) [0|1] "" Vector__XXX
 SG_ VCRIGHT_a115_BDY_endpointTemp m115 : 42|1@1+ (1,0) [0|1] "" Vector__XXX
 SG_ VCRIGHT_a115_BDY_BLEResetRequest m115 : 48|1@1+ (1,0) [0|1] "" Vector__XXX
 SG_ VCRIGHT_a115_BDY_RSSI m115 : 49|1@1+ (1,0) [0|1] "" Vector__XXX
 SG_ VCRIGHT_a115_BDY_authentication m115 : 50|1@1+ (1,0) [0|1] "" Vector__XXX
 SG_ VCRIGHT_a115_BDY_requests m115 : 51|1@1+ (1,0) [0|1] "" Vector__XXX
 SG_ VCRIGHT_a115_BDY_requests2 m115 : 52|1@1+ (1,0) [0|1] "" Vector__XXX
 SG_ VCRIGHT_a115_BDY_vehNm m115 : 53|1@1+ (1,0) [0|1] "" Vector__XXX
 SG_ VCRIGHT_a115_BDY_authenticationW m115 : 54|1@1+ (1,0) [0|1] "" Vector__XXX
 SG_ VCRIGHT_a116_PARTY_epbmStatus m116 : 16|1@1+ (1,0) [0|1] "" Vector__XXX
 SG_ VCRIGHT_a116_VEH_vehNm m116 : 17|1@1+ (1,0) [0|1] "" Vector__XXX
 SG_ VCRIGHT_a116_VEH_hvacRequest m116 : 18|1@1+ (1,0) [0|1] "" Vector__XXX
 SG_ VCRIGHT_a116_VEH_hvacStatus m116 : 19|1@1+ (1,0) [0|1] "" Vector__XXX
 SG_ VCRIGHT_a116_VEH_LVPowerState m116 : 20|1@1+ (1,0) [0|1] "" Vector__XXX
 SG_ VCRIGHT_a116_VEH_lightStatus m116 : 21|1@1+ (1,0) [0|1] "" Vector__XXX
 SG_ VCRIGHT_a116_VEH_seatStatus m116 : 22|1@1+ (1,0) [0|1] "" Vector__XXX
 SG_ VCRIGHT_a116_VEH_thsStatus m116 : 23|1@1+ (1,0) [0|1] "" Vector__XXX
 SG_ VCRIGHT_a116_VEH_doorStatus m116 : 24|1@1+ (1,0) [0|1] "" Vector__XXX
 SG_ VCRIGHT_a116_VEH_seatHeatStatus m116 : 25|1@1+ (1,0) [0|1] "" Vector__XXX
 SG_ VCRIGHT_a116_VEH_restraintStatus m116 : 26|1@1+ (1,0) [0|1] "" Vector__XXX
 SG_ VCRIGHT_a116_VEH_switchStatus m116 : 27|1@1+ (1,0) [0|1] "" Vector__XXX
 SG_ VCRIGHT_a116_VEH_logging1Hz m116 : 28|1@1+ (1,0) [0|1] "" Vector__XXX
 SG_ VCRIGHT_a116_VEH_seatStatus2 m116 : 29|1@1+ (1,0) [0|1] "" Vector__XXX
 SG_ VCRIGHT_a116_VEH_status m116 : 30|1@1+ (1,0) [0|1] "" Vector__XXX
 SG_ VCRIGHT_a116_VEH_thermalCommand m116 : 31|1@1+ (1,0) [0|1] "" Vector__XXX
 SG_ VCRIGHT_a116_VEH_windowStatus m116 : 32|1@1+ (1,0) [0|1] "" Vector__XXX
 SG_ VCRIGHT_a116_PARTY_restraintStat m116 : 33|1@1+ (1,0) [0|1] "" Vector__XXX
 SG_ VCRIGHT_a116_PARTY_doorStatus m116 : 34|1@1+ (1,0) [0|1] "" Vector__XXX
 SG_ VCRIGHT_a116_BDY_epbmStatus m116 : 35|1@1+ (1,0) [0|1] "" Vector__XXX
 SG_ VCRIGHT_a116_BDY_restraintStatus m116 : 36|1@1+ (1,0) [0|1] "" Vector__XXX
 SG_ VCRIGHT_a116_BDY_switchStatus m116 : 37|1@1+ (1,0) [0|1] "" Vector__XXX
 SG_ VCRIGHT_a117_BDY_epbmStatus m117 : 16|1@1+ (1,0) [0|1] "" Vector__XXX
 SG_ VCRIGHT_a117_BDY_restraintStatus m117 : 17|1@1+ (1,0) [0|1] "" Vector__XXX
 SG_ VCRIGHT_a117_VEH_prndStatus m117 : 18|1@1+ (1,0) [0|1] "" Vector__XXX
 SG_ VCRIGHT_a117_PARTY_epbmStatus m117 : 19|1@1+ (1,0) [0|1] "" Vector__XXX
 SG_ VCRIGHT_a117_VEH_vehNm m117 : 20|1@1+ (1,0) [0|1] "" Vector__XXX
 SG_ VCRIGHT_a117_VEH_hvacBlowerFdb m117 : 21|1@1+ (1,0) [0|1] "" Vector__XXX
 SG_ VCRIGHT_a117_VEH_LVPowerState m117 : 22|1@1+ (1,0) [0|1] "" Vector__XXX
 SG_ VCRIGHT_a117_VEH_restraintStatus m117 : 23|1@1+ (1,0) [0|1] "" Vector__XXX
 SG_ VCRIGHT_a117_VEH_lightStatus m117 : 24|1@1+ (1,0) [0|1] "" Vector__XXX
 SG_ VCRIGHT_a117_VEH_seatStatus m117 : 25|1@1+ (1,0) [0|1] "" Vector__XXX
 SG_ VCRIGHT_a117_BDY_falconSwitchSta m117 : 26|1@1+ (1,0) [0|1] "" Vector__XXX
 SG_ VCRIGHT_a117_VEH_doorStatus m117 : 27|1@1+ (1,0) [0|1] "" Vector__XXX
 SG_ VCRIGHT_a117_VEH_doorStatus2 m117 : 28|1@1+ (1,0) [0|1] "" Vector__XXX
 SG_ VCRIGHT_a117_VEH_windowStatus m117 : 29|1@1+ (1,0) [0|1] "" Vector__XXX
 SG_ VCRIGHT_a117_VEH_switchStatus m117 : 30|1@1+ (1,0) [0|1] "" Vector__XXX
 SG_ VCRIGHT_a117_VEH_intrusionSensor m117 : 31|1@1+ (1,0) [0|1] "" Vector__XXX
 SG_ VCRIGHT_a117_VEH_liftgateStatus m117 : 32|1@1+ (1,0) [0|1] "" Vector__XXX
 SG_ VCRIGHT_a117_VEH_seatStatus2 m117 : 33|1@1+ (1,0) [0|1] "" Vector__XXX
 SG_ VCRIGHT_a117_PARTY_restraintStat m117 : 34|1@1+ (1,0) [0|1] "" Vector__XXX
 SG_ VCRIGHT_a117_VEH_thermalStatus m117 : 35|1@1+ (1,0) [0|1] "" Vector__XXX
 SG_ VCRIGHT_a117_PARTY_doorStatus m117 : 36|1@1+ (1,0) [0|1] "" Vector__XXX
 SG_ VCRIGHT_a117_VEH_status m117 : 37|1@1+ (1,0) [0|1] "" Vector__XXX
 SG_ VCRIGHT_a117_PARTY_prndStatus m117 : 38|1@1+ (1,0) [0|1] "" Vector__XXX
 SG_ VCRIGHT_a117_PARTY_lightingSecon m117 : 39|1@1+ (1,0) [0|1] "" Vector__XXX
 SG_ VCRIGHT_a117_BDY_lightingSeconda m117 : 59|1@1+ (1,0) [0|1] "" Vector__XXX
 SG_ VCRIGHT_a117_BDY_hvacBlowerFdb m117 : 60|1@1+ (1,0) [0|1] "" Vector__XXX
 SG_ VCRIGHT_a117_BDY_thermalStatus m117 : 61|1@1+ (1,0) [0|1] "" Vector__XXX
 SG_ VCRIGHT_a117_BDY_status m117 : 62|1@1+ (1,0) [0|1] "" Vector__XXX
 SG_ VCRIGHT_a117_VEH_liftgateLeaderR m117 : 63|1@1+ (1,0) [0|1] "" Vector__XXX
 SG_ VCRIGHT_a118_VEH_vehNm m118 : 16|1@1+ (1,0) [0|1] "" Vector__XXX
 SG_ VCRIGHT_a118_VEH_lighting m118 : 17|1@1+ (1,0) [0|1] "" Vector__XXX
 SG_ VCRIGHT_a118_VEH_sensors m118 : 18|1@1+ (1,0) [0|1] "" Vector__XXX
 SG_ VCRIGHT_a118_VEH_status m118 : 19|1@1+ (1,0) [0|1] "" Vector__XXX
 SG_ VCRIGHT_a118_VEH_okToUseHighPwr m118 : 20|1@1+ (1,0) [0|1] "" Vector__XXX
 SG_ VCRIGHT_a118_VEH_LVPowerState m118 : 21|1@1+ (1,0) [0|1] "" Vector__XXX
 SG_ VCRIGHT_a118_VEH_coolant m118 : 22|1@1+ (1,0) [0|1] "" Vector__XXX
 SG_ VCRIGHT_a118_VEH_vehicleStatus m118 : 23|1@1+ (1,0) [0|1] "" Vector__XXX
 SG_ VCRIGHT_a118_VEH_12VBatteryStatu m118 : 24|1@1+ (1,0) [0|1] "" Vector__XXX
 SG_ VCRIGHT_a118_VEH_systemStatus m118 : 25|1@1+ (1,0) [0|1] "" Vector__XXX
 SG_ VCRIGHT_a118_PARTY_LVPowerState m118 : 26|1@1+ (1,0) [0|1] "" Vector__XXX
 SG_ VCRIGHT_a118_PARTY_outputPowerSt m118 : 27|1@1+ (1,0) [0|1] "" Vector__XXX
 SG_ VCRIGHT_a118_PARTY_vehicleTime m118 : 28|1@1+ (1,0) [0|1] "" Vector__XXX
 SG_ VCRIGHT_a118_VEH_thermalCommand m118 : 29|1@1+ (1,0) [0|1] "" Vector__XXX
 SG_ VCRIGHT_a118_CH_LVPowerState m118 : 30|1@1+ (1,0) [0|1] "" Vector__XXX
 SG_ VCRIGHT_a118_PARTY_sensors m118 : 31|1@1+ (1,0) [0|1] "" Vector__XXX
 SG_ VCRIGHT_a118_CH_sensors m118 : 32|1@1+ (1,0) [0|1] "" Vector__XXX
 SG_ VCRIGHT_a118_VEH_interNodeResist m118 : 33|1@1+ (1,0) [0|1] "" Vector__XXX
 SG_ VCRIGHT_a118_CH_lighting m118 : 34|1@1+ (1,0) [0|1] "" Vector__XXX
 SG_ VCRIGHT_a118_VEH_lightStatus m118 : 35|1@1+ (1,0) [0|1] "" Vector__XXX
 SG_ VCRIGHT_a118_PARTY_vehNm m118 : 36|1@1+ (1,0) [0|1] "" Vector__XXX
 SG_ VCRIGHT_a118_CH_12VBatteryStatus m118 : 37|1@1+ (1,0) [0|1] "" Vector__XXX
 SG_ VCRIGHT_a118_CH_LVBMS_statusHigh m118 : 38|1@1+ (1,0) [0|1] "" Vector__XXX
 SG_ VCRIGHT_a118_CH_alertMatrix m118 : 39|1@1+ (1,0) [0|1] "" Vector__XXX
 SG_ VCRIGHT_a118_BDY_outputPowerStat m118 : 40|1@1+ (1,0) [0|1] "" Vector__XXX
 SG_ VCRIGHT_a118_BDY_vehicleTime m118 : 41|1@1+ (1,0) [0|1] "" Vector__XXX
 SG_ VCRIGHT_a118_PARTY_AP_vehicleSta m118 : 42|1@1+ (1,0) [0|1] "" Vector__XXX
 SG_ VCRIGHT_a118_BDY_AP_vehicleState m118 : 43|1@1+ (1,0) [0|1] "" Vector__XXX
 SG_ VCRIGHT_a118_PARTY_VCFRONT_camer m118 : 44|1@1+ (1,0) [0|1] "" Vector__XXX
 SG_ VCRIGHT_a118_VEH_LVHealth m118 : 62|1@1+ (1,0) [0|1] "" Vector__XXX
 SG_ VCRIGHT_a118_BDY_LVHealth m118 : 63|1@1+ (1,0) [0|1] "" Vector__XXX
 SG_ VCRIGHT_a119_VEH_steerAngle m119 : 16|1@1+ (1,0) [0|1] "" Vector__XXX
 SG_ VCRIGHT_a119_VEH_leftStalk m119 : 17|1@1+ (1,0) [0|1] "" Vector__XXX
 SG_ VCRIGHT_a119_VEH_rightStalk m119 : 18|1@1+ (1,0) [0|1] "" Vector__XXX
 SG_ VCRIGHT_a119_PARTY_rightStalk m119 : 19|1@1+ (1,0) [0|1] "" Vector__XXX
 SG_ VCRIGHT_a119_CH_steerAngle m119 : 20|1@1+ (1,0) [0|1] "" Vector__XXX
 SG_ VCRIGHT_a119_PARTY_steerAngle m119 : 21|1@1+ (1,0) [0|1] "" Vector__XXX
 SG_ VCRIGHT_a120_PARTY_chassisCntl m120 : 16|1@1+ (1,0) [0|1] "" Vector__XXX
 SG_ VCRIGHT_a120_VEH_systemStatus m120 : 17|1@1+ (1,0) [0|1] "" Vector__XXX
 SG_ VCRIGHT_a120_CH_chassisCntl m120 : 18|1@1+ (1,0) [0|1] "" Vector__XXX
 SG_ VCRIGHT_a120_PARTY_systemStatus m120 : 19|1@1+ (1,0) [0|1] "" Vector__XXX
 SG_ VCRIGHT_a120_PARTY_torque m120 : 20|1@1+ (1,0) [0|1] "" Vector__XXX
 SG_ VCRIGHT_a120_VEH_torque m120 : 21|1@1+ (1,0) [0|1] "" Vector__XXX
 SG_ VCRIGHT_a120_PARTY_locStatus m120 : 22|1@1+ (1,0) [0|1] "" Vector__XXX
 SG_ VCRIGHT_a120_PARTY_speed m120 : 23|1@1+ (1,0) [0|1] "" Vector__XXX
 SG_ VCRIGHT_a120_VEH_speed m120 : 24|1@1+ (1,0) [0|1] "" Vector__XXX
 SG_ VCRIGHT_a120_PARTY_status m120 : 25|1@1+ (1,0) [0|1] "" Vector__XXX
 SG_ VCRIGHT_a120_PT_speed m120 : 26|1@1+ (1,0) [0|1] "" Vector__XXX
 SG_ VCRIGHT_a120_PT_systemStatus m120 : 27|1@1+ (1,0) [0|1] "" Vector__XXX
 SG_ VCRIGHT_a120_PARTY_vehicleEstima m120 : 28|1@1+ (1,0) [0|1] "" Vector__XXX
 SG_ VCRIGHT_a120_VEH_aggregatedAxleS m120 : 29|1@1+ (1,0) [0|1] "" Vector__XXX
 SG_ VCRIGHT_a120_PARTY_aggregatedAxl m120 : 30|1@1+ (1,0) [0|1] "" Vector__XXX
 SG_ VCRIGHT_a120_VEH_systemPower m120 : 31|1@1+ (1,0) [0|1] "" Vector__XXX
 SG_ VCRIGHT_a120_PARTY_autonomyHealt m120 : 32|1@1+ (1,0) [0|1] "" Vector__XXX
 SG_ VCRIGHT_a120_VEH_autonomyHealth m120 : 33|1@1+ (1,0) [0|1] "" Vector__XXX
 SG_ VCRIGHT_a120_PT_systemPower m120 : 34|1@1+ (1,0) [0|1] "" Vector__XXX
 SG_ VCRIGHT_a120_PARTY_stalklessInte m120 : 35|1@1+ (1,0) [0|1] "" Vector__XXX
 SG_ VCRIGHT_a120_CH_speed m120 : 36|1@1+ (1,0) [0|1] "" Vector__XXX
 SG_ VCRIGHT_a120_VEH_estimatedBrakeT m120 : 37|1@1+ (1,0) [0|1] "" Vector__XXX
 SG_ VCRIGHT_a120_PARTY_prndControl m120 : 38|1@1+ (1,0) [0|1] "" Vector__XXX
 SG_ VCRIGHT_a120_PARTY_locStatus2 m120 : 39|1@1+ (1,0) [0|1] "" Vector__XXX
 SG_ VCRIGHT_a120_VEH_chassisCntl m120 : 40|1@1+ (1,0) [0|1] "" Vector__XXX
 SG_ VCRIGHT_a120_CH_locStatus2 m120 : 41|1@1+ (1,0) [0|1] "" Vector__XXX
 SG_ VCRIGHT_a120_VEH_locStatus m120 : 42|1@1+ (1,0) [0|1] "" Vector__XXX
 SG_ VCRIGHT_a120_VEH_locStatus2 m120 : 43|1@1+ (1,0) [0|1] "" Vector__XXX
 SG_ VCRIGHT_a120_VEH_prndControl m120 : 44|1@1+ (1,0) [0|1] "" Vector__XXX
 SG_ VCRIGHT_a120_VEH_vehicleEstimate m120 : 45|1@1+ (1,0) [0|1] "" Vector__XXX
 SG_ VCRIGHT_a120_PARTY_motorStatus m120 : 46|1@1+ (1,0) [0|1] "" Vector__XXX
 SG_ VCRIGHT_a120_VEH_motorStatus m120 : 47|1@1+ (1,0) [0|1] "" Vector__XXX
 SG_ VCRIGHT_a120_BDY_speed m120 : 48|1@1+ (1,0) [0|1] "" Vector__XXX
 SG_ VCRIGHT_a121_OBD_status m121 : 16|1@1+ (1,0) [0|1] "" Vector__XXX
 SG_ VCRIGHT_a124_PARTY_status m124 : 16|1@1+ (1,0) [0|1] "" Vector__XXX
 SG_ VCRIGHT_a124_BDY_status m124 : 17|1@1+ (1,0) [0|1] "" Vector__XXX
 SG_ VCRIGHT_a124_VEH_status m124 : 18|1@1+ (1,0) [0|1] "" Vector__XXX
 SG_ VCRIGHT_a125_PARTY_actuation m125 : 16|1@1+ (1,0) [0|1] "" Vector__XXX
 SG_ VCRIGHT_a125_BDY_actuation m125 : 17|1@1+ (1,0) [0|1] "" Vector__XXX
 SG_ VCRIGHT_a125_PARTY_status m125 : 18|1@1+ (1,0) [0|1] "" Vector__XXX
 SG_ VCRIGHT_a125_BDY_status m125 : 19|1@1+ (1,0) [0|1] "" Vector__XXX
 SG_ VCRIGHT_a136_hvacIntakeStall m136 : 16|1@1+ (1,0) [0|1] "" Vector__XXX
 SG_ VCRIGHT_a137_hvacLHBleedStall m137 : 16|1@1+ (1,0) [0|1] "" Vector__XXX
 SG_ VCRIGHT_a138_hvacRHBleedStall m138 : 16|1@1+ (1,0) [0|1] "" Vector__XXX
 SG_ VCRIGHT_a139_hvacLHVaneStall m139 : 16|1@1+ (1,0) [0|1] "" Vector__XXX
 SG_ VCRIGHT_a140_hvacRHVaneStall m140 : 16|1@1+ (1,0) [0|1] "" Vector__XXX
 SG_ VCRIGHT_a141_hvacUpperModeStall m141 : 16|1@1+ (1,0) [0|1] "" Vector__XXX
 SG_ VCRIGHT_a142_hvacLowerModeStall m142 : 16|1@1+ (1,0) [0|1] "" Vector__XXX
 SG_ VCRIGHT_a144_snsShortCircuit m144 : 16|1@1+ (1,0) [0|1] "" Vector__XXX
 SG_ VCRIGHT_a144_snsDisconnect m144 : 17|1@1+ (1,0) [0|1] "" Vector__XXX
 SG_ VCRIGHT_a144_snsRateChangeUp m144 : 18|1@1+ (1,0) [0|1] "" Vector__XXX
 SG_ VCRIGHT_a144_snsRateChangeDown m144 : 19|1@1+ (1,0) [0|1] "" Vector__XXX
 SG_ VCRIGHT_a145_snsShortCircuit m145 : 16|1@1+ (1,0) [0|1] "" Vector__XXX
 SG_ VCRIGHT_a145_snsDisconnect m145 : 17|1@1+ (1,0) [0|1] "" Vector__XXX
 SG_ VCRIGHT_a145_snsRateChangeUp m145 : 18|1@1+ (1,0) [0|1] "" Vector__XXX
 SG_ VCRIGHT_a145_snsRateChangeDown m145 : 19|1@1+ (1,0) [0|1] "" Vector__XXX
 SG_ VCRIGHT_a146_snsShortCircuit m146 : 16|1@1+ (1,0) [0|1] "" Vector__XXX
 SG_ VCRIGHT_a146_snsDisconnect m146 : 17|1@1+ (1,0) [0|1] "" Vector__XXX
 SG_ VCRIGHT_a146_snsRateChangeUp m146 : 18|1@1+ (1,0) [0|1] "" Vector__XXX
 SG_ VCRIGHT_a146_snsRateChangeDown m146 : 19|1@1+ (1,0) [0|1] "" Vector__XXX
 SG_ VCRIGHT_a147_snsShortCircuit m147 : 16|1@1+ (1,0) [0|1] "" Vector__XXX
 SG_ VCRIGHT_a147_snsDisconnect m147 : 17|1@1+ (1,0) [0|1] "" Vector__XXX
 SG_ VCRIGHT_a147_snsRateChangeUp m147 : 18|1@1+ (1,0) [0|1] "" Vector__XXX
 SG_ VCRIGHT_a147_snsRateChangeDown m147 : 19|1@1+ (1,0) [0|1] "" Vector__XXX
 SG_ VCRIGHT_a148_snsShortCircuit m148 : 16|1@1+ (1,0) [0|1] "" Vector__XXX
 SG_ VCRIGHT_a148_snsDisconnect m148 : 17|1@1+ (1,0) [0|1] "" Vector__XXX
 SG_ VCRIGHT_a148_snsRateChangeUp m148 : 18|1@1+ (1,0) [0|1] "" Vector__XXX
 SG_ VCRIGHT_a148_snsRateChangeDown m148 : 19|1@1+ (1,0) [0|1] "" Vector__XXX
 SG_ VCRIGHT_a149_snsShortCircuit m149 : 16|1@1+ (1,0) [0|1] "" Vector__XXX
 SG_ VCRIGHT_a149_snsDisconnect m149 : 17|1@1+ (1,0) [0|1] "" Vector__XXX
 SG_ VCRIGHT_a149_snsRateChangeUp m149 : 18|1@1+ (1,0) [0|1] "" Vector__XXX
 SG_ VCRIGHT_a149_snsRateChangeDown m149 : 19|1@1+ (1,0) [0|1] "" Vector__XXX
 SG_ VCRIGHT_a150_windowPosition m150 : 16|9@1- (1.43137252331,197.529418945) [-168.901947022|562.529412389] "" Vector__XXX
 SG_ VCRIGHT_a150_movementTimeMs m150 : 25|7@1+ (50,0) [0|6350] "" Vector__XXX
 SG_ VCRIGHT_a150_windowPinchReason m150 : 32|3@1+ (1,0) [0|7] "" Vector__XXX
 SG_ VCRIGHT_a150_lookbackIndex m150 : 35|6@1+ (1,0) [0|63] "" Vector__XXX
 SG_ VCRIGHT_a150_absAccelExceedance m150 : 41|8@1+ (0.09803922,0) [0|25.0000011] "" Vector__XXX
 SG_ VCRIGHT_a150_relAccelExceedance m150 : 49|8@1+ (0.09803922,0) [0|25.0000011] "" Vector__XXX
 SG_ VCRIGHT_a150_speedExpScore m150 : 57|6@1- (0.0006451613,-0.009677419) [-0.0303225806|0.0103225813] "" Vector__XXX
 SG_ VCRIGHT_a150_treatedInGear m150 : 63|1@1+ (1,0) [0|1] "" Vector__XXX
 SG_ VCRIGHT_a151_windowPosition m151 : 16|9@1- (1.43137252331,197.529418945) [-168.901947022|562.529412389] "" Vector__XXX
 SG_ VCRIGHT_a151_movementTimeMs m151 : 25|7@1+ (50,0) [0|6350] "" Vector__XXX
 SG_ VCRIGHT_a151_windowPinchReason m151 : 32|3@1+ (1,0) [0|7] "" Vector__XXX
 SG_ VCRIGHT_a151_lookbackIndex m151 : 35|6@1+ (1,0) [0|63] "" Vector__XXX
 SG_ VCRIGHT_a151_absAccelExceedance m151 : 41|8@1+ (0.09803922,0) [0|25.0000011] "" Vector__XXX
 SG_ VCRIGHT_a151_relAccelExceedance m151 : 49|8@1+ (0.09803922,0) [0|25.0000011] "" Vector__XXX
 SG_ VCRIGHT_a151_speedExpScore m151 : 57|6@1- (0.0006451613,-0.009677419) [-0.0303225806|0.0103225813] "" Vector__XXX
 SG_ VCRIGHT_a151_treatedInGear m151 : 63|1@1+ (1,0) [0|1] "" Vector__XXX
 SG_ VCRIGHT_a152_zeroed m152 : 16|1@1+ (1,0) [0|1] "" Vector__XXX
 SG_ VCRIGHT_a152_endStopTrusted m152 : 17|1@1+ (1,0) [0|1] "" Vector__XXX
 SG_ VCRIGHT_a152_speedTableStatus m152 : 18|2@1+ (1,0) [0|3] "" Vector__XXX
 SG_ VCRIGHT_a152_causedByBackoffs m152 : 20|1@1+ (1,0) [0|1] "" Vector__XXX
 SG_ VCRIGHT_a153_zeroed m153 : 16|1@1+ (1,0) [0|1] "" Vector__XXX
 SG_ VCRIGHT_a153_endStopTrusted m153 : 17|1@1+ (1,0) [0|1] "" Vector__XXX
 SG_ VCRIGHT_a153_speedTableStatus m153 : 18|2@1+ (1,0) [0|3] "" Vector__XXX
 SG_ VCRIGHT_a153_causedByBackoffs m153 : 20|1@1+ (1,0) [0|1] "" Vector__XXX
 SG_ VCRIGHT_a154_windowThermalMode m154 : 16|2@1+ (1,0) [0|3] "" Vector__XXX
 SG_ VCRIGHT_a154_lightShowActive m154 : 18|1@1+ (1,0) [0|1] "" Vector__XXX
 SG_ VCRIGHT_a155_windowThermalMode m155 : 16|2@1+ (1,0) [0|3] "" Vector__XXX
 SG_ VCRIGHT_a155_lightShowActive m155 : 18|1@1+ (1,0) [0|1] "" Vector__XXX
 SG_ VCRIGHT_a177_hvacRearStall m177 : 16|1@1+ (1,0) [0|1] "" Vector__XXX
 SG_ VCRIGHT_a180_intButtonPressed m180 : 16|1@1+ (1,0) [0|1] "" Vector__XXX
 SG_ VCRIGHT_a180_extHandlePWM m180 : 24|8@1+ (1,0) [0|255] "" Vector__XXX
 SG_ VCRIGHT_a180_extHandlePulled m180 : 32|1@1+ (1,0) [0|1] "" Vector__XXX
 SG_ VCRIGHT_a180_releasePWM m180 : 40|8@1+ (1,0) [0|255] "" Vector__XXX
 SG_ VCRIGHT_a180_latchStatus m180 : 48|4@1+ (1,0) [0|15] "" Vector__XXX
 SG_ VCRIGHT_a180_latchClawStatus m180 : 52|1@1+ (1,0) [0|1] "" Vector__XXX
 SG_ VCRIGHT_a181_intButtonPressed m181 : 16|1@1+ (1,0) [0|1] "" Vector__XXX
 SG_ VCRIGHT_a181_extHandlePWM m181 : 24|8@1+ (1,0) [0|255] "" Vector__XXX
 SG_ VCRIGHT_a181_extHandlePulled m181 : 32|1@1+ (1,0) [0|1] "" Vector__XXX
 SG_ VCRIGHT_a181_releasePWM m181 : 40|8@1+ (1,0) [0|255] "" Vector__XXX
 SG_ VCRIGHT_a181_latchStatus m181 : 48|4@1+ (1,0) [0|15] "" Vector__XXX
 SG_ VCRIGHT_a181_latchClawStatus m181 : 52|1@1+ (1,0) [0|1] "" Vector__XXX
 SG_ VCRIGHT_a184_voltage m184 : 16|7@1+ (0.15,0) [0|19.05] "" Vector__XXX
 SG_ VCRIGHT_a184_temperature m184 : 24|8@1+ (0.5,-40) [-40|87.5] "" Vector__XXX
 SG_ VCRIGHT_a184_trunkCurrent m184 : 32|8@1+ (0.05,0) [0|12.75] "" Vector__XXX
 SG_ VCRIGHT_a186_voltage m186 : 16|7@1+ (0.15,0) [0|19.05] "" Vector__XXX
 SG_ VCRIGHT_a186_temperature m186 : 24|8@1+ (0.5,-40) [-40|87.5] "" Vector__XXX
 SG_ VCRIGHT_a187_voltage m187 : 16|7@1+ (0.15,0) [0|19.05] "" Vector__XXX
 SG_ VCRIGHT_a187_temperature m187 : 24|8@1+ (0.5,-40) [-40|87.5] "" Vector__XXX
 SG_ VCRIGHT_a188_voltage m188 : 16|7@1+ (0.15,0) [0|19.05] "" Vector__XXX
 SG_ VCRIGHT_a188_temperature m188 : 24|8@1+ (0.5,-40) [-40|87.5] "" Vector__XXX
 SG_ VCRIGHT_a189_voltage m189 : 16|7@1+ (0.15,0) [0|19.05] "" Vector__XXX
 SG_ VCRIGHT_a189_temperature m189 : 24|8@1+ (0.5,-40) [-40|87.5] "" Vector__XXX
 SG_ VCRIGHT_a190_eFuseTripCount m190 : 16|8@1+ (1,0) [0|255] "" Vector__XXX
 SG_ VCRIGHT_a193_amplifierCurrent m193 : 16|10@1+ (0.1,0) [0|102.3] "" Vector__XXX
 SG_ VCRIGHT_a194_cntctrPwrCurrent m194 : 16|10@1+ (0.1,0) [0|102.3] "" Vector__XXX
 SG_ VCRIGHT_a195_hvcCurrent m195 : 16|10@1+ (0.1,0) [0|102.3] "" Vector__XXX
 SG_ VCRIGHT_a196_outputState m196 : 16|1@1+ (1,0) [0|1] "" Vector__XXX
 SG_ VCRIGHT_a196_NVRAMState m196 : 17|1@1+ (1,0) [0|1] "" Vector__XXX
 SG_ VCRIGHT_a196_lockoutState m196 : 18|1@1+ (1,0) [0|1] "" Vector__XXX
 SG_ VCRIGHT_a197_outputState m197 : 16|1@1+ (1,0) [0|1] "" Vector__XXX
 SG_ VCRIGHT_a197_NVRAMState m197 : 17|1@1+ (1,0) [0|1] "" Vector__XXX
 SG_ VCRIGHT_a197_lockoutState m197 : 18|1@1+ (1,0) [0|1] "" Vector__XXX
 SG_ VCRIGHT_a198_outputState m198 : 16|1@1+ (1,0) [0|1] "" Vector__XXX
 SG_ VCRIGHT_a198_NVRAMState m198 : 17|1@1+ (1,0) [0|1] "" Vector__XXX
 SG_ VCRIGHT_a198_lockoutState m198 : 18|1@1+ (1,0) [0|1] "" Vector__XXX
 SG_ VCRIGHT_a199_outputState m199 : 16|1@1+ (1,0) [0|1] "" Vector__XXX
 SG_ VCRIGHT_a199_NVRAMState m199 : 17|1@1+ (1,0) [0|1] "" Vector__XXX
 SG_ VCRIGHT_a199_lockoutState m199 : 18|1@1+ (1,0) [0|1] "" Vector__XXX
 SG_ VCRIGHT_a202_unknownAllowed m202 : 16|1@1+ (1,0) [0|1] "" Vector__XXX
 SG_ VCRIGHT_a202_openAllowed m202 : 17|1@1+ (1,0) [0|1] "" Vector__XXX
 SG_ VCRIGHT_a202_dynamicAllowed m202 : 18|1@1+ (1,0) [0|1] "" Vector__XXX
 SG_ VCRIGHT_a202_parkAllowed m202 : 19|1@1+ (1,0) [0|1] "" Vector__XXX
 SG_ VCRIGHT_a202_startAllowed m202 : 20|1@1+ (1,0) [0|1] "" Vector__XXX
 SG_ VCRIGHT_a202_serviceAllowed m202 : 21|1@1+ (1,0) [0|1] "" Vector__XXX
 SG_ VCRIGHT_a202_winchAllowed m202 : 22|1@1+ (1,0) [0|1] "" Vector__XXX
 SG_ VCRIGHT_a202_winchReleaseAllowed m202 : 23|1@1+ (1,0) [0|1] "" Vector__XXX
 SG_ VCRIGHT_a202_parkingAllowed m202 : 24|1@1+ (1,0) [0|1] "" Vector__XXX
 SG_ VCRIGHT_a202_dynApplyAllowed m202 : 25|1@1+ (1,0) [0|1] "" Vector__XXX
 SG_ VCRIGHT_a202_releaseAllowed m202 : 26|1@1+ (1,0) [0|1] "" Vector__XXX
 SG_ VCRIGHT_a202_parkPendingAllowed m202 : 27|1@1+ (1,0) [0|1] "" Vector__XXX
 SG_ VCRIGHT_a202_wenchPendingAllowed m202 : 28|1@1+ (1,0) [0|1] "" Vector__XXX
 SG_ VCRIGHT_a202_desyncCount m202 : 32|6@1+ (1,0) [0|63] "" Vector__XXX
 SG_ VCRIGHT_a202_current m202 : 38|10@1+ (0.05,0) [0|51.15] "" Vector__XXX
 SG_ VCRIGHT_a202_epbConfig m202 : 48|4@1+ (1,0) [0|15] "" Vector__XXX
 SG_ VCRIGHT_a203_unknownAllowed m203 : 16|1@1+ (1,0) [0|1] "" Vector__XXX
 SG_ VCRIGHT_a203_openAllowed m203 : 17|1@1+ (1,0) [0|1] "" Vector__XXX
 SG_ VCRIGHT_a203_dynamicAllowed m203 : 18|1@1+ (1,0) [0|1] "" Vector__XXX
 SG_ VCRIGHT_a203_parkAllowed m203 : 19|1@1+ (1,0) [0|1] "" Vector__XXX
 SG_ VCRIGHT_a203_startAllowed m203 : 20|1@1+ (1,0) [0|1] "" Vector__XXX
 SG_ VCRIGHT_a203_serviceAllowed m203 : 21|1@1+ (1,0) [0|1] "" Vector__XXX
 SG_ VCRIGHT_a203_winchAllowed m203 : 22|1@1+ (1,0) [0|1] "" Vector__XXX
 SG_ VCRIGHT_a203_winchReleaseAllowed m203 : 23|1@1+ (1,0) [0|1] "" Vector__XXX
 SG_ VCRIGHT_a203_parkingAllowed m203 : 24|1@1+ (1,0) [0|1] "" Vector__XXX
 SG_ VCRIGHT_a203_dynApplyAllowed m203 : 25|1@1+ (1,0) [0|1] "" Vector__XXX
 SG_ VCRIGHT_a203_releaseAllowed m203 : 26|1@1+ (1,0) [0|1] "" Vector__XXX
 SG_ VCRIGHT_a203_parkPendingAllowed m203 : 27|1@1+ (1,0) [0|1] "" Vector__XXX
 SG_ VCRIGHT_a203_wenchPendingAllowed m203 : 28|1@1+ (1,0) [0|1] "" Vector__XXX
 SG_ VCRIGHT_a203_desyncCount m203 : 32|6@1+ (1,0) [0|63] "" Vector__XXX
 SG_ VCRIGHT_a203_current m203 : 38|10@1+ (0.05,0) [0|51.15] "" Vector__XXX
 SG_ VCRIGHT_a203_epbConfig m203 : 48|4@1+ (1,0) [0|15] "" Vector__XXX
 SG_ VCRIGHT_a204_unknownAllowed m204 : 16|1@1+ (1,0) [0|1] "" Vector__XXX
 SG_ VCRIGHT_a204_openAllowed m204 : 17|1@1+ (1,0) [0|1] "" Vector__XXX
 SG_ VCRIGHT_a204_dynamicAllowed m204 : 18|1@1+ (1,0) [0|1] "" Vector__XXX
 SG_ VCRIGHT_a204_parkAllowed m204 : 19|1@1+ (1,0) [0|1] "" Vector__XXX
 SG_ VCRIGHT_a204_startAllowed m204 : 20|1@1+ (1,0) [0|1] "" Vector__XXX
 SG_ VCRIGHT_a204_serviceAllowed m204 : 21|1@1+ (1,0) [0|1] "" Vector__XXX
 SG_ VCRIGHT_a204_winchAllowed m204 : 22|1@1+ (1,0) [0|1] "" Vector__XXX
 SG_ VCRIGHT_a204_winchReleaseAllowed m204 : 23|1@1+ (1,0) [0|1] "" Vector__XXX
 SG_ VCRIGHT_a204_parkingAllowed m204 : 24|1@1+ (1,0) [0|1] "" Vector__XXX
 SG_ VCRIGHT_a204_dynApplyAllowed m204 : 25|1@1+ (1,0) [0|1] "" Vector__XXX
 SG_ VCRIGHT_a204_releaseAllowed m204 : 26|1@1+ (1,0) [0|1] "" Vector__XXX
 SG_ VCRIGHT_a204_parkPendingAllowed m204 : 27|1@1+ (1,0) [0|1] "" Vector__XXX
 SG_ VCRIGHT_a204_wenchPendingAllowed m204 : 28|1@1+ (1,0) [0|1] "" Vector__XXX
 SG_ VCRIGHT_a204_desyncCount m204 : 32|6@1+ (1,0) [0|63] "" Vector__XXX
 SG_ VCRIGHT_a204_current m204 : 38|10@1+ (0.05,0) [0|51.15] "" Vector__XXX
 SG_ VCRIGHT_a204_epbConfig m204 : 48|4@1+ (1,0) [0|15] "" Vector__XXX
 SG_ VCRIGHT_a205_unknownAllowed m205 : 16|1@1+ (1,0) [0|1] "" Vector__XXX
 SG_ VCRIGHT_a205_openAllowed m205 : 17|1@1+ (1,0) [0|1] "" Vector__XXX
 SG_ VCRIGHT_a205_dynamicAllowed m205 : 18|1@1+ (1,0) [0|1] "" Vector__XXX
 SG_ VCRIGHT_a205_parkAllowed m205 : 19|1@1+ (1,0) [0|1] "" Vector__XXX
 SG_ VCRIGHT_a205_startAllowed m205 : 20|1@1+ (1,0) [0|1] "" Vector__XXX
 SG_ VCRIGHT_a205_serviceAllowed m205 : 21|1@1+ (1,0) [0|1] "" Vector__XXX
 SG_ VCRIGHT_a205_winchAllowed m205 : 22|1@1+ (1,0) [0|1] "" Vector__XXX
 SG_ VCRIGHT_a205_winchReleaseAllowed m205 : 23|1@1+ (1,0) [0|1] "" Vector__XXX
 SG_ VCRIGHT_a205_parkingAllowed m205 : 24|1@1+ (1,0) [0|1] "" Vector__XXX
 SG_ VCRIGHT_a205_dynApplyAllowed m205 : 25|1@1+ (1,0) [0|1] "" Vector__XXX
 SG_ VCRIGHT_a205_releaseAllowed m205 : 26|1@1+ (1,0) [0|1] "" Vector__XXX
 SG_ VCRIGHT_a205_parkPendingAllowed m205 : 27|1@1+ (1,0) [0|1] "" Vector__XXX
 SG_ VCRIGHT_a205_wenchPendingAllowed m205 : 28|1@1+ (1,0) [0|1] "" Vector__XXX
 SG_ VCRIGHT_a205_desyncCount m205 : 32|6@1+ (1,0) [0|63] "" Vector__XXX
 SG_ VCRIGHT_a205_current m205 : 38|10@1+ (0.05,0) [0|51.15] "" Vector__XXX
 SG_ VCRIGHT_a205_epbConfig m205 : 48|4@1+ (1,0) [0|15] "" Vector__XXX
 SG_ VCRIGHT_a206_unknownAllowed m206 : 16|1@1+ (1,0) [0|1] "" Vector__XXX
 SG_ VCRIGHT_a206_openAllowed m206 : 17|1@1+ (1,0) [0|1] "" Vector__XXX
 SG_ VCRIGHT_a206_dynamicAllowed m206 : 18|1@1+ (1,0) [0|1] "" Vector__XXX
 SG_ VCRIGHT_a206_parkAllowed m206 : 19|1@1+ (1,0) [0|1] "" Vector__XXX
 SG_ VCRIGHT_a206_startAllowed m206 : 20|1@1+ (1,0) [0|1] "" Vector__XXX
 SG_ VCRIGHT_a206_serviceAllowed m206 : 21|1@1+ (1,0) [0|1] "" Vector__XXX
 SG_ VCRIGHT_a206_winchAllowed m206 : 22|1@1+ (1,0) [0|1] "" Vector__XXX
 SG_ VCRIGHT_a206_winchReleaseAllowed m206 : 23|1@1+ (1,0) [0|1] "" Vector__XXX
 SG_ VCRIGHT_a206_parkingAllowed m206 : 24|1@1+ (1,0) [0|1] "" Vector__XXX
 SG_ VCRIGHT_a206_dynApplyAllowed m206 : 25|1@1+ (1,0) [0|1] "" Vector__XXX
 SG_ VCRIGHT_a206_releaseAllowed m206 : 26|1@1+ (1,0) [0|1] "" Vector__XXX
 SG_ VCRIGHT_a206_parkPendingAllowed m206 : 27|1@1+ (1,0) [0|1] "" Vector__XXX
 SG_ VCRIGHT_a206_wenchPendingAllowed m206 : 28|1@1+ (1,0) [0|1] "" Vector__XXX
 SG_ VCRIGHT_a206_unitStatusEPB m206 : 32|5@1+ (1,0) [0|31] "" Vector__XXX
 SG_ VCRIGHT_a206_unitStatusEPBM m206 : 40|5@1+ (1,0) [0|31] "" Vector__XXX
 SG_ VCRIGHT_a207_unknownAllowed m207 : 16|1@1+ (1,0) [0|1] "" Vector__XXX
 SG_ VCRIGHT_a207_openAllowed m207 : 17|1@1+ (1,0) [0|1] "" Vector__XXX
 SG_ VCRIGHT_a207_dynamicAllowed m207 : 18|1@1+ (1,0) [0|1] "" Vector__XXX
 SG_ VCRIGHT_a207_parkAllowed m207 : 19|1@1+ (1,0) [0|1] "" Vector__XXX
 SG_ VCRIGHT_a207_startAllowed m207 : 20|1@1+ (1,0) [0|1] "" Vector__XXX
 SG_ VCRIGHT_a207_serviceAllowed m207 : 21|1@1+ (1,0) [0|1] "" Vector__XXX
 SG_ VCRIGHT_a207_winchAllowed m207 : 22|1@1+ (1,0) [0|1] "" Vector__XXX
 SG_ VCRIGHT_a207_winchReleaseAllowed m207 : 23|1@1+ (1,0) [0|1] "" Vector__XXX
 SG_ VCRIGHT_a207_parkingAllowed m207 : 24|1@1+ (1,0) [0|1] "" Vector__XXX
 SG_ VCRIGHT_a207_dynApplyAllowed m207 : 25|1@1+ (1,0) [0|1] "" Vector__XXX
 SG_ VCRIGHT_a207_releaseAllowed m207 : 26|1@1+ (1,0) [0|1] "" Vector__XXX

CM_ BO_ 738 "Left body controller message: seat status2";
CM_ SG_ 738 VCLEFT_seatStatus2Index "Left body controller: seat status2 index";
CM_ SG_ 738 VCLEFT_frontSeatHeatCurrent "Left body controller: front seat heat current";
CM_ SG_ 738 VCLEFT_frontSeatHeatDuty "Left body controller: front seat heat duty";
CM_ SG_ 738 VCLEFT_frontSeatHeatTmp "Left body controller: front seat heat tmp";
CM_ SG_ 738 VCLEFT_frontSeatHeatTmpTarget "Left body controller: front seat heat tmp target";
CM_ SG_ 738 VCLEFT_frontSeatHeatInhibited "Left body controller: front seat heat inhibited";
CM_ SG_ 738 VCLEFT_frontSeatHeatPowered "Left body controller: front seat heat powered";
CM_ SG_ 738 VCLEFT_2RowSeatFoldLeftSwitch "Reports status of the left seat fold switch in the second row";
CM_ SG_ 738 VCLEFT_2RowSeatUnfoldLeftSwitch "Reports status of the left seat unfold switch in the second row";
CM_ SG_ 738 VCLEFT_2RowSeatFoldRightSwitch "Reports status of the right seat fold switch in the second row";
CM_ SG_ 738 VCLEFT_2RowSeatUnfoldRightSwitch "Reports status of the right seat unfold switch in the second row";
CM_ SG_ 738 VCLEFT_3RowSeatFoldLeftSwitch "Reports status of the left seat fold switch in the third row";
CM_ SG_ 738 VCLEFT_3RowSeatUnfoldLeftSwitch "Reports status of the left seat unfold switch in the third row";
CM_ SG_ 738 VCLEFT_3RowSeatFoldRightSwitch "Reports status of the right seat fold switch in the third row";
CM_ SG_ 738 VCLEFT_3RowSeatUnfoldRightSwitch "Reports status of the right seat unfold switch in the third row";
CM_ SG_ 738 VC_AH_1RowLeftSeatHeatVentHealth "Left body controller: AH 1 row left seat heat vent health";
CM_ SG_ 738 VCLEFT_2RowSeatReclineState "Reports the active state of the 2nd row seat recliner";
CM_ SG_ 738 VCLEFT_2RowSeatReclineDuty "Reports the 2nd row seat recliner motor duty cycle";
CM_ SG_ 738 VCLEFT_2RowSeatReclineCurrent "Reports the 2nd row seat recliner motor current";
CM_ SG_ 738 VCLEFT_2RowSeatReclineCalibrated "Reports calibration status of the 2nd row seat recliner";
CM_ SG_ 738 VCLEFT_2RowSeatReclinePositionRa "Reports the 2nd row seat recliner raw encoder count";
CM_ SG_ 738 VCLEFT_2RowSeatReclineAngle "Reports the position of the 2nd row seat recliner in degrees";
CM_ SG_ 738 VCLEFT_2RowSeatReclineAbsPosSwit "Reports the status of 2nd row seat recline absolute position (comfort zone) switch";
CM_ SG_ 738 VCLEFT_2RowSeatReclinePositionSt "Reports the active position state of the 2nd row seat recliner";
CM_ SG_ 738 VCLEFT_2RowSeatReclineAdjustment "Indicates whether adjustment requests are currently permitted for the rear seat recliner";
CM_ SG_ 738 VCLEFT_2RowSeatReclineFoldAllowe "Indicates whether auto-fold requests are currently permitted for the rear seat recliner";
CM_ SG_ 738 VCLEFT_2RowSeatReclineUnfoldAllo "Indicates whether auto-unfold requests are currently permitted for the rear seat recliner";
CM_ SG_ 738 VCLEFT_2RowSeatReclineNextToggle "Left body controller: 2 row seat recline next toggle direction";
CM_ SG_ 738 VCLEFT_2RowSeatReclineChoreoBloc "Left body controller: 2 row seat recline choreo blocked by occupancy";
CM_ SG_ 738 VCLEFT_2RowSeat1RClashAvoidanceB "Left body controller: 2 row seat1 r clash avoidance blocked reason";
CM_ SG_ 738 VCLEFT_2RowSeat1RClashAvoidanceS "Left body controller: 2 row seat1 r clash avoidance state";
CM_ SG_ 738 VCLEFT_2RowSeatReclineAbsPo_0001 "Left body controller: 2 row seat recline abs pos switch trans point";
CM_ SG_ 738 VC_AH_2RowLeftSeatMovementHealth "Left body controller: AH 2 row left seat movement health";
CM_ SG_ 738 VCLEFT_3RowSeatReclineState "Reports active state of the rear seat recliner";
CM_ SG_ 738 VCLEFT_3RowSeatReclineDuty "Reports the third row seat recliner motor duty cycle";
CM_ SG_ 738 VCLEFT_3RowSeatReclineCurrent "Reports the third row seat recliner motor current";
CM_ SG_ 738 VCLEFT_3RowSeatReclineCalibrated "Reports calibration status of the third row seat recliner";
CM_ SG_ 738 VCLEFT_3RowSeatReclinePositionRa "Reports the third row seat recliner raw encoder count";
CM_ SG_ 738 VCLEFT_3RowSeatReclineAngle "Reports position of the 3rd row seat recliner in degrees";
CM_ SG_ 738 VCLEFT_3RowSeatReclineNextToggle "Left body controller: 3 row seat recline next toggle direction";
CM_ SG_ 738 VCLEFT_3RRightCushionHeatCurrent "Current drawn by 3rd row right seat heater";
CM_ SG_ 738 VCLEFT_3RRightCushionHeatDuty "3rd row right seat heater duty cycle";
CM_ SG_ 738 VCLEFT_3RRightCushionHeatTmp "Left body controller: 3 r right cushion heat tmp";
CM_ SG_ 738 VCLEFT_3RRightCushionHeatTmpTarg "Target temperature for 3rd row right seat heater";
CM_ SG_ 738 VCLEFT_3RRightCushionHeatInhibit "Status describing whether 3rd row right seat heat is inhibited";
CM_ SG_ 738 VCLEFT_3RowSeatReclinePositionSt "Reports active position state of the rear seat recliner";
CM_ SG_ 738 VCLEFT_3RowSeatReclineAdjustment "Indicates whether adjustment requests are currently permitted for the rear seat recliner";
CM_ SG_ 738 VCLEFT_3RowSeatReclineFoldAllowe "Indicates whether auto-fold requests are currently permitted for the rear seat recliner";
CM_ SG_ 738 VCLEFT_3RowSeatReclineUnfoldAllo "Indicates whether auto-unfold requests are currently permitted for the rear seat recliner";
CM_ SG_ 738 VCLEFT_3RowSeatReclineChoreoBloc "Left body controller: 3 row seat recline choreo blocked by occupancy";
CM_ SG_ 738 VCLEFT_3RowSeatReclineAbsPosSwit "Reports status of 2R seat recline absolute position (comfort zone) switch";
CM_ BO_ 930 "Left body controller message: status";
CM_ SG_ 930 VCLEFT_statusIndex "Left body controller: status index";
CM_ SG_ 930 VCLEFT_securityControllerEnable "Left body controller: security controller enable";
CM_ SG_ 930 VCLEFT_securityControllerVoltage "Voltage of the VCSEC power feed";
CM_ SG_ 930 VCLEFT_consoleDoorAssist "Left body controller: console door assist";
CM_ SG_ 930 VCLEFT_OTAState "Left body controller: OTA state";
CM_ SG_ 930 VCLEFT_5AVoltage "Left body controller: 5 a voltage";
CM_ SG_ 930 VCLEFT_vbatProt "Left body controller: vbat prot";
CM_ SG_ 930 VCLEFT_footwellLightCurrent "Left body controller: footwell light current";
CM_ SG_ 930 VCLEFT_swcInputVoltage "Input voltage reported by steering wheel controller module";
CM_ SG_ 930 VCLEFT_swcPCBATemperature "Left body controller: swc PCBA temperature";
CM_ SG_ 930 VCLEFT_obdEthernetActive "Left body controller: obd ethernet active";
CM_ SG_ 930 VCLEFT_rationalityAggregateCurre "Left body controller: rationality aggregate current";
CM_ SG_ 930 VCLEFT_LVBatteryTypeDBG "Left body controller: LV battery type DBG";
CM_ SG_ 930 VCLEFT_DIeFuseFault "Left body controller: d ie fuse fault";
CM_ SG_ 930 VCLEFT_eFuseMgmtVoltageMonitor "Left body controller: e fuse mgmt voltage monitor";
CM_ SG_ 930 VCLEFT_trailerAuxCurrent "Current Draw of the trailer aux output";
CM_ SG_ 930 VCLEFT_swcHeatTmp "Temperature of steering wheel heater as reported by NTC";
CM_ SG_ 930 VCLEFT_swcHeatStatus "Status of steering wheel heater";
CM_ SG_ 930 VCLEFT_swcHeatInhibited "Status describing whether steering wheel heat is inhibited";
CM_ SG_ 930 VCLEFT_obdDeviceDetected "Reports whether the Left Vehicle Controller (VCLEFT) detects that an external device is connected to the OBD port.";
CM_ SG_ 930 VCLEFT_pcbaTemperature "Left body controller: pcba temperature";
CM_ SG_ 930 VCLEFT_swcHeatPwr "Power of steering wheel heater";
CM_ SG_ 930 VCLEFT_swcHeatDutyCycle "Steering wheel heater duty cycle";
CM_ SG_ 930 VCLEFT_DIeFuseCurrent "Left body controller: d ie fuse current";
CM_ SG_ 930 VCLEFT_SWCpresent "Left body controller: SW cpresent";
CM_ SG_ 930 VCLEFT_trailerBrakeControllerCur "Value of the trailer brake controller HSD (high side driver) current sense.";
CM_ SG_ 930 VCLEFT_autonomyBehaviorStatus "Left body controller: autonomy behavior status";
CM_ SG_ 930 VCLEFT_thirdRowLeftMapLightStatu "Reports the status of the third row left overhead map light.";
CM_ SG_ 930 VCLEFT_thirdRowRightMapLightStat "Reports the status of the third row right overhead map light";
CM_ BO_ 610 "Left body controller message: steering column status";
CM_ SG_ 610 VCLEFT_steeringColumnSMState "Status of steering column state machine";
CM_ SG_ 610 VCLEFT_steeringColumnLastRequest "Left body controller: steering column last request";
CM_ SG_ 610 VCLEFT_steeringColumnUpDownDuty "Steering column tilt motor duty cycle";
CM_ SG_ 610 VCLEFT_steeringColumnInOutDuty "Steering column telescope motor duty cycle";
CM_ SG_ 610 VCLEFT_steeringColumnUpDownPos "Motor encoder value representing steering column tilt position";
CM_ SG_ 610 VCLEFT_steeringColumnInOutPos "Motor encoder value representing steering column telescope position";
CM_ SG_ 610 VCLEFT_steeringColumnUpDownAmps "Measures current used by the steering column tilt motor.";
CM_ SG_ 610 VCLEFT_steeringColumnInOutAmps "Measures current used by the steering column telescope motor.";
CM_ SG_ 610 VCLEFT_steeringColumnUpDownCalib "Left body controller: steering column up down calib";
CM_ SG_ 610 VCLEFT_steeringColumnInOutCalib "Left body controller: steering column in out calib";
CM_ SG_ 610 VCLEFT_steeringColumnUpDownTC "Left body controller: steering column up down TC";
CM_ SG_ 610 VCLEFT_steeringColumnInOutTC "Left body controller: steering column in out TC";
CM_ BO_ 962 "Left body controller message: switch status";
CM_ SG_ 962 VCLEFT_switchStatusIndex "Left body controller: switch status index";
CM_ SG_ 962 VCLEFT_hornSwitchPressed "Left body controller: horn switch pressed";
CM_ SG_ 962 VCLEFT_hazardButtonPressed "Left body controller: hazard button pressed";
CM_ SG_ 962 VCLEFT_brakeSwitchPressed "Status of the brake pedal switch";
CM_ SG_ 962 VCLEFT_rightMirrorTilt "Left body controller: right mirror tilt";
CM_ SG_ 962 VCLEFT_frontSeatTrackBack "Left body controller: front seat track back";
CM_ SG_ 962 VCLEFT_frontSeatTrackForward "Left body controller: front seat track forward";
CM_ SG_ 962 VCLEFT_frontSeatTiltDown "Left body controller: front seat tilt down";
CM_ SG_ 962 VCLEFT_frontSeatTiltUp "Left body controller: front seat tilt up";
CM_ SG_ 962 VCLEFT_frontSeatLiftDown "Left body controller: front seat lift down";
CM_ SG_ 962 VCLEFT_frontSeatLiftUp "Left body controller: front seat lift up";
CM_ SG_ 962 VCLEFT_frontSeatBackrestBack "Left body controller: front seat backrest back";
CM_ SG_ 962 VCLEFT_frontSeatBackrestForward "Left body controller: front seat backrest forward";
CM_ SG_ 962 VCLEFT_frontSeatLumbarDown "Left body controller: front seat lumbar down";
CM_ SG_ 962 VCLEFT_frontSeatLumbarUp "Left body controller: front seat lumbar up";
CM_ SG_ 962 VCLEFT_frontSeatLumbarIn "Left body controller: front seat lumbar in";
CM_ SG_ 962 VCLEFT_frontSeatLumbarOut "Left body controller: front seat lumbar out";
CM_ SG_ 962 VCLEFT_btnWindowSwPackUpLF "Left body controller: btn window sw pack up LF";
CM_ SG_ 962 VCLEFT_btnWindowSwPackAutoUpLF "Left body controller: btn window sw pack auto up LF";
CM_ SG_ 962 VCLEFT_btnWindowSwPackDownLF "Left body controller: btn window sw pack down LF";
CM_ SG_ 962 VCLEFT_btnWindowSwPackAutoDownLF "Left body controller: btn window sw pack auto down LF";
CM_ SG_ 962 VCLEFT_btnWindowSwPackUpLR "Left body controller: btn window sw pack up LR";
CM_ SG_ 962 VCLEFT_btnWindowSwPackAutoUpLR "Left body controller: btn window sw pack auto up LR";
CM_ SG_ 962 VCLEFT_btnWindowSwPackDownLR "Left body controller: btn window sw pack down LR";
CM_ SG_ 962 VCLEFT_btnWindowSwPackAutoDownLR "Left body controller: btn window sw pack auto down LR";
CM_ SG_ 962 VCLEFT_btnWindowSwPackUpRF "Left body controller: btn window sw pack up RF";
CM_ SG_ 962 VCLEFT_btnWindowSwPackAutoUpRF "Left body controller: btn window sw pack auto up RF";
CM_ SG_ 962 VCLEFT_btnWindowSwPackDownRF "Left body controller: btn window sw pack down RF";
CM_ SG_ 962 VCLEFT_btnWindowSwPackAutoDownRF "Left body controller: btn window sw pack auto down RF";
CM_ SG_ 962 VCLEFT_btnWindowSwPackUpRR "Left body controller: btn window sw pack up RR";
CM_ SG_ 962 VCLEFT_btnWindowSwPackAutoUpRR "Left body controller: btn window sw pack auto up RR";
CM_ SG_ 962 VCLEFT_btnWindowSwPackDownRR "Left body controller: btn window sw pack down RR";
CM_ SG_ 962 VCLEFT_btnWindowSwPackAutoDownRR "Left body controller: btn window sw pack auto down RR";
CM_ SG_ 962 VCLEFT_frontBuckleSwitch "Left body controller: front buckle switch";
CM_ SG_ 962 VCLEFT_frontOccupancySwitch "Front left seat occupancy status";
CM_ SG_ 962 VCLEFT_rearLeftBuckleSwitch "Left body controller: rear left buckle switch";
CM_ SG_ 962 VCLEFT_rearCenterOccupancySwitch "Left body controller: rear center occupancy switch";
CM_ SG_ 962 VCLEFT_rearLeftOccupancySwitch "Left body controller: rear left occupancy switch";
CM_ SG_ 962 VCLEFT_rearRightOccupancySwitch "Left body controller: rear right occupancy switch";
CM_ SG_ 962 VCLEFT_brakePressed "Status of the brake pedal";
CM_ SG_ 962 VCLEFT_rearHVACButtonPressed "Left body controller: rear HVAC button pressed";
CM_ SG_ 962 VCLEFT_rearCenterBuckleSwitch "Left body controller: rear center buckle switch";
CM_ SG_ 962 VCLEFT_isAlcoholInterlockSet "Reports if the alcohol interlock is set.";
CM_ SG_ 962 VCLEFT_swcLeftTiltRight "Left body controller: swc left tilt right";
CM_ SG_ 962 VCLEFT_swcLeftPressed "Left body controller: swc left pressed";
CM_ SG_ 962 VCLEFT_swcRightTiltLeft "Left body controller: swc right tilt left";
CM_ SG_ 962 VCLEFT_swcRightTiltRight "Left body controller: swc right tilt right";
CM_ SG_ 962 VCLEFT_swcRightPressed "Left body controller: swc right pressed";
CM_ SG_ 962 VCLEFT_swcLeftTiltLeft "Left body controller: swc left tilt left";
CM_ SG_ 962 VCLEFT_swcLeftScrollTicks "Left body controller: swc left scroll ticks";
CM_ SG_ 962 VCLEFT_swcWiperButtonState "Left body controller: swc wiper button state";
CM_ SG_ 962 VCLEFT_swcRightScrollTicks "Encoder value for right steering wheel switch scroll";
CM_ SG_ 962 VCLEFT_swcTurnSignalLeftButtonSt "Left body controller: swc turn signal left button state";
CM_ SG_ 962 VCLEFT_btnWindowUpLR "Left body controller: btn window up LR";
CM_ SG_ 962 VCLEFT_btnWindowAutoUpLR "Left body controller: btn window auto up LR";
CM_ SG_ 962 VCLEFT_btnWindowDownLR "Left body controller: btn window down LR";
CM_ SG_ 962 VCLEFT_btnWindowAutoDownLR "Left body controller: btn window auto down LR";
CM_ SG_ 962 VCLEFT_2RowSeatReclineSwitch "Second row seat recline switch";
CM_ SG_ 962 VCLEFT_2RowSeatCenterSwitch "Second row seat center switch";
CM_ SG_ 962 VCLEFT_2RowSeatLeftFoldFlatSwitc "Second row seat left fold flat switch";
CM_ SG_ 962 VCLEFT_2RowSeatRightFoldFlatSwit "Second row seat right fold flat switch";
CM_ SG_ 962 VCLEFT_2RowSeatBothFoldFlatSwitc "Second row seat both fold flat switch";
CM_ SG_ 962 VCLEFT_swcLeftDoublePress "Left body controller: swc left double press";
CM_ SG_ 962 VCLEFT_swcRightDoublePress "Left body controller: swc right double press";
CM_ SG_ 962 VCLEFT_2RowSeatBackrestFoldSwitc "Second row seat backrest fold switch";
CM_ SG_ 962 VCLEFT_swcTurnSignalRightButtonS "Left body controller: swc turn signal right button state";
CM_ SG_ 962 VCLEFT_swcHighBeamButtonState "Left body controller: swc high beam button state";
CM_ SG_ 962 VCLEFT_swcVoiceControlPress "Left body controller: swc voice control press";
CM_ SG_ 962 VCLEFT_swcCameraButtonState "Left body controller: swc camera button state";
CM_ SG_ 962 VCLEFT_swcRightPressedQF "Quality of steering wheel right scroll wheel button signal";
CM_ SG_ 962 VCLEFT_2RowSeatReclineSwitchpack "State of the left second row powered recline adjustment switchpack";
CM_ SG_ 962 VCLEFT_3RowLeftBuckleSwitch "Report status of 3rd row left seatbelt buckle";
CM_ SG_ 962 VCLEFT_frontSeatThighSupportExte "Status of the switch used to extend front seat thigh support.";
CM_ SG_ 962 VCLEFT_frontSeatThighSupportRetr "Status of the switch used to retract front seat thigh support.";
CM_ SG_ 962 VCLEFT_frontSeatResistiveOccupan "Front left seat occupancy status";
CM_ BO_ 656 "Left body controller message: thermal logging10 hz";
CM_ SG_ 656 VCLEFT_thermalLogging10HzIndex "Left body controller: thermal logging10 hz index";
CM_ SG_ 656 VCLEFT_hvac2RLeftLateralVoltage "Left body controller: hvac2 r left lateral voltage";
CM_ SG_ 656 VCLEFT_hvac2RLeftVerticalVoltage "Left body controller: hvac2 r left vertical voltage";
CM_ SG_ 656 VCLEFT_hvac2RRightLateralVoltage "Left body controller: hvac2 r right lateral voltage";
CM_ SG_ 656 VCLEFT_hvac2RRightVerticalVoltag "Left body controller: hvac2 r right vertical voltage";
CM_ SG_ 656 VCLEFT_hvac2RLeftLateralCalibrat "Left body controller: hvac2 r left lateral calibrated";
CM_ SG_ 656 VCLEFT_hvac2RLeftVerticalCalibra "Left body controller: hvac2 r left vertical calibrated";
CM_ SG_ 656 VCLEFT_hvac2RRightLateralCalibra "Left body controller: hvac2 r right lateral calibrated";
CM_ SG_ 656 VCLEFT_hvac2RRightVerticalCalibr "Left body controller: hvac2 r right vertical calibrated";
CM_ SG_ 656 VCLEFT_hvac2RLeftLateralState "Left body controller: hvac2 r left lateral state";
CM_ SG_ 656 VCLEFT_hvac2RLeftVerticalState "Left body controller: hvac2 r left vertical state";
CM_ SG_ 656 VCLEFT_hvac2RRightLateralState "Left body controller: hvac2 r right lateral state";
CM_ SG_ 656 VCLEFT_hvac2RRightVerticalState "Left body controller: hvac2 r right vertical state";
CM_ SG_ 656 VCLEFT_hvacBlowerWindmillElecRpm "Left body controller: hvac blower windmill elec rpm";
CM_ SG_ 656 VCLEFT_hvac2RRightVerticalVeloci "Left body controller: hvac2 r right vertical velocity";
CM_ SG_ 656 VCLEFT_hvacBlowerWindmillBemf "Left body controller: hvac blower windmill bemf";
CM_ SG_ 656 VCLEFT_hvac2RLeftVerticalVelocit "Left body controller: hvac2 r left vertical velocity";
CM_ SG_ 656 VCLEFT_hvac2RLeftLateralVelocity "Left body controller: hvac2 r left lateral velocity";
CM_ SG_ 656 VCLEFT_vcusbLinSchedule "Left body controller: vcusb lin schedule";
CM_ SG_ 656 VCLEFT_hvacBlowerArbState "Left body controller: hvac blower arb state";
CM_ SG_ 656 VCLEFT_hvacBlowerArbResult "Left body controller: hvac blower arb result";
CM_ SG_ 656 VCLEFT_hvac2RLeftLateralDuty "Left body controller: hvac2 r left lateral duty";
CM_ SG_ 656 VCLEFT_hvac2RLeftVerticalDuty "Left body controller: hvac2 r left vertical duty";
CM_ SG_ 656 VCLEFT_hvac2RRightLateralDuty "Left body controller: hvac2 r right lateral duty";
CM_ SG_ 656 VCLEFT_hvac2RRightVerticalDuty "Left body controller: hvac2 r right vertical duty";
CM_ SG_ 656 VCLEFT_hvacBlowerWindmilling "Left body controller: hvac blower windmilling";
CM_ SG_ 656 VCLEFT_hvac2RRightLateralVelocit "Left body controller: hvac2 r right lateral velocity";
CM_ SG_ 656 VCLEFT_hvacBlower1msOverrunFrequ "Left body controller: hvac blower1ms overrun frequency";
CM_ SG_ 656 VCLEFT_hvacBlower10msOverrunFreq "Left body controller: hvac blower10ms overrun frequency";
CM_ BO_ 657 "Left body controller message: thermal logging1 hz";
CM_ SG_ 657 VCLEFT_thermalLogging1HzIndex "Left body controller: thermal logging1 hz index";
CM_ SG_ 657 VCLEFT_hvac2RLeftLateralZeroStop "Left body controller: hvac2 r left lateral zero stop voltage";
CM_ SG_ 657 VCLEFT_hvac2RLeftVerticalZeroSto "Left body controller: hvac2 r left vertical zero stop voltage";
CM_ SG_ 657 VCLEFT_hvac2RRightLateralZeroSto "Left body controller: hvac2 r right lateral zero stop voltage";
CM_ SG_ 657 VCLEFT_hvac2RRightVerticalZeroSt "Left body controller: hvac2 r right vertical zero stop voltage";
CM_ SG_ 657 VCLEFT_hvac2RLeftLateralEndStopV "Left body controller: hvac2 r left lateral end stop voltage";
CM_ SG_ 657 VCLEFT_hvac2RLeftVerticalEndStop "Left body controller: hvac2 r left vertical end stop voltage";
CM_ SG_ 657 VCLEFT_hvac2RRightLateralEndStop "Left body controller: hvac2 r right lateral end stop voltage";
CM_ SG_ 657 VCLEFT_hvac2RRightVerticalEndSto "Left body controller: hvac2 r right vertical end stop voltage";
CM_ SG_ 657 VCLEFT_hvacBlowerArbCurrent "Left body controller: hvac blower arb current";
CM_ SG_ 657 VCLEFT_hvacBlowerTorqueIndexFilt "Left body controller: hvac blower torque index filtered";
CM_ BO_ 386 "Left body controller message: thermal status";
CM_ SG_ 386 VCLEFT_hvac2RLeftLateralStatus "Left body controller: hvac2 r left lateral status";
CM_ SG_ 386 VCLEFT_hvac2RLeftVerticalStatus "Left body controller: hvac2 r left vertical status";
CM_ SG_ 386 VCLEFT_hvac2RRightLateralStatus "Left body controller: hvac2 r right lateral status";
CM_ SG_ 386 VCLEFT_hvac2RRightVerticalStatus "Left body controller: hvac2 r right vertical status";
CM_ SG_ 386 VCLEFT_hvac2RLeftLateralPosition "Left body controller: hvac2 r left lateral position";
CM_ SG_ 386 VCLEFT_hvac2RLeftVerticalPositio "Left body controller: hvac2 r left vertical position";
CM_ SG_ 386 VCLEFT_hvac2RRightLateralPositio "Left body controller: hvac2 r right lateral position";
CM_ SG_ 386 VCLEFT_hvac2RRightVerticalPositi "Left body controller: hvac2 r right vertical position";
CM_ BO_ 706 "Left body controller message: window status";
CM_ SG_ 706 VCLEFT_windowStatusIndex "Left body controller: window status index";
CM_ SG_ 706 VCLEFT_windowStateLF "Status of left front window motor";
CM_ SG_ 706 VCLEFT_windowTrimClearMoveReques "Requests whether windows should enter or exit trim clear. Signal only valid if Vehicle Controller Left (VCLEFT) is on driver side.";
CM_ SG_ 706 VCLEFT_windowDutyLF "Left body controller: window duty LF";
CM_ SG_ 706 VCLEFT_windowTrimClearActiveRequ "Reports whether window trim clear is active. Signal is only valid if Vehicle Controller Left (VCLEFT) is on driver side.";
CM_ SG_ 706 VCLEFT_windowCurrentLF "Current drawn by left front window regulator";
CM_ SG_ 706 VCLEFT_windowPositionLF "Left body controller: window position LF";
CM_ SG_ 706 VCLEFT_windowCalibratedLF "Calibration status of left front window motor";
CM_ SG_ 706 VCLEFT_windowStateLR "Status of left rear window motor";
CM_ SG_ 706 VCLEFT_windowDutyLR "Left body controller: window duty LR";
CM_ SG_ 706 VCLEFT_windowCurrentLR "Current drawn by left rear window regulator";
CM_ SG_ 706 VCLEFT_windowPositionLR "Left body controller: window position LR";
CM_ SG_ 706 VCLEFT_windowCalibratedLR "Calibraiton status of left rear window motor";
CM_ SG_ 706 VCLEFT_windowThermalTCLF "Left body controller: window thermal TCLF";
CM_ SG_ 706 VCLEFT_windowThermalModeLF "Left body controller: window thermal mode LF";
CM_ SG_ 706 VCLEFT_windowStopReasonLF "Reason for left front window stopping motion";
CM_ SG_ 706 VCLEFT_windowStopReqReasonLF "Reason for left front window stopping motion";
CM_ SG_ 706 VCLEFT_windowThermalTCLR "Left body controller: window thermal TCLR";
CM_ SG_ 706 VCLEFT_windowThermalModeLR "Left body controller: window thermal mode LR";
CM_ SG_ 706 VCLEFT_windowStopReasonLR "Reason for left rear window stopping motion";
CM_ SG_ 706 VCLEFT_windowStopReqReasonLR "Reason for left rear window stopping motion";
CM_ SG_ 706 VCLEFT_windowControlStateLF "Window control state";
CM_ SG_ 706 VCLEFT_windowCtrlUnavailableLF "Window control unavailable reason";
CM_ SG_ 706 VCLEFT_windowControlStateLR "Window control state";
CM_ SG_ 706 VCLEFT_windowCtrlUnavailableLR "Window control unavailable reason";
CM_ SG_ 706 VCLEFT_windowPositionStateLF "Window position state";
CM_ SG_ 706 VCLEFT_windowPositionStateLR "Window position state";
CM_ SG_ 706 VCLEFT_windowVehGearStateLF "Window's interpretation of vehicle gear state";
CM_ SG_ 706 VCLEFT_windowVehGearStateLR "Window's interpretation of vehicle gear state";
CM_ SG_ 706 VCLEFT_windowSpeedTableStatusLF "Speed table build status of left front window";
CM_ SG_ 706 VCLEFT_windowSpeedTableStatusLR "Speed table build status of left rear window";
CM_ BO_ 1114 "Right body controller message: AP hvac state10 hz";
CM_ SG_ 1114 VCRIGHT_AP_hvacState10HzIndex "Right body controller: AP hvac state10 hz index";
CM_ SG_ 1114 VCRIGHT_AP_autoDefogAvailable "Right body controller: AP auto defog available";
CM_ SG_ 1114 VCRIGHT_AP_hvacFlashFoggingDetec "Right body controller: AP hvac flash fogging detected";
CM_ SG_ 1114 VCRIGHT_AP_hvacModelInitStatus "Right body controller: AP hvac model init status";
CM_ SG_ 1114 VCRIGHT_AP_cabinTempWindshield "Right body controller: AP cabin temp windshield";
CM_ SG_ 1114 VCRIGHT_AP_cabinTempSideGlassRig "Right body controller: AP cabin temp side glass right";
CM_ SG_ 1114 VCRIGHT_AP_cabinTempSideGlassLef "Right body controller: AP cabin temp side glass left";
CM_ SG_ 1114 VCRIGHT_AP_hvacRecircDoorPercent "Right body controller: AP hvac recirc door percent";
CM_ SG_ 1114 VCRIGHT_AP_hvacAirDistributionMo "Right body controller: AP hvac air distribution mode";
CM_ SG_ 1114 VCRIGHT_AP_hvacEstimateWindshiel "Right body controller: AP hvac estimate windshield RH";
CM_ SG_ 1114 VCRIGHT_AP_hvacMassflowTarget "Right body controller: AP hvac massflow target";
CM_ SG_ 1114 VCRIGHT_AP_tempDuctDefrost "Right body controller: AP temp duct defrost";
CM_ SG_ 1114 VCRIGHT_AP_cameraTurnOnTime "Reports the time duration requested to run the Autopilot (AP) cameras for defogging purposes.";
CM_ SG_ 1114 VCRIGHT_AP_cameraDefogType "Right body controller: AP camera defog type";
CM_ SG_ 1114 VCRIGHT_ah_hvacFaultSurvivabilit "Right body controller: ah hvac fault survivability time";
CM_ SG_ 1114 VCRIGHT_ah_defoggingTimeNeeded "Right body controller: ah defogging time needed";
CM_ SG_ 1114 VCRIGHT_AP_cameraFanDutyRequest "Right body controller: AP camera fan duty request";
CM_ SG_ 1114 VCRIGHT_ah_defogSystemState "Right body controller: ah defog system state";
CM_ SG_ 1114 VCRIGHT_AP_turnForwardCameraHeat "Right body controller: AP turn forward camera heater on reason";
CM_ SG_ 1114 VCRIGHT_AP_turnCameraFanOffReaso "Reports the reason for requesting the triple camera fan to turn off.";
CM_ SG_ 1114 VCRIGHT_AP_forwardCameraIntegrat "Request to run forward camera heating.";
CM_ SG_ 1114 VCRIGHT_AP_solarFluxOnRightWindo "Right body controller: AP solar flux on right window";
CM_ SG_ 1114 VCRIGHT_AP_solarFluxOnLeftWindow "Right body controller: AP solar flux on left window";
CM_ BO_ 1124 "Right body controller message: AP hvac state1 hz";
CM_ SG_ 1124 VCRIGHT_AP_hvacState1HzIndex "Right body controller: AP hvac state1 hz index";
CM_ SG_ 1124 VCRIGHT_AP_tempCameraModele_0001 "Right body controller: AP temp camera modeled windshield out";
CM_ SG_ 1124 VCRIGHT_AP_tempCameraModeledWind "Right body controller: AP temp camera modeled windshield in";
CM_ SG_ 1124 VCRIGHT_AP_cameraModeledWin_0001 "Right body controller: AP camera modeled windshield out rh";
CM_ SG_ 1124 VCRIGHT_AP_cameraModeledWindshie "Right body controller: AP camera modeled windshield in rh";
CM_ SG_ 1124 VCRIGHT_AP_maxAchievableASideTem "Right body controller: AP max achievable a side temp camera pocket";
CM_ SG_ 1124 VCRIGHT_AP_cameraModeledPocketWa "Right body controller: AP camera modeled pocket water mass";
CM_ SG_ 1124 VCRIGHT_AP_humidityModelInitStat "Right body controller: AP humidity model init status";
CM_ SG_ 1124 VCRIGHT_AP_humidityModelStatus "Right body controller: AP humidity model status";
CM_ BO_ 549 "Right body controller message: LV power state";
CM_ SG_ 549 VCRIGHT_ptcLVState "Right body controller: ptc LV state";
CM_ SG_ 549 VCRIGHT_ocsLVState "Right body controller: ocs LV state";
CM_ SG_ 549 VCRIGHT_premAudioLVState "Right body controller: prem audio LV state";
CM_ SG_ 549 VCRIGHT_rearOilPumpLVState "Right body controller: rear oil pump LV state";
CM_ SG_ 549 VCRIGHT_tunerLVState "Right body controller: tuner LV state";
CM_ SG_ 549 VCRIGHT_hvcLVState "Right body controller: hvc LV state";
CM_ SG_ 549 VCRIGHT_rcmLVState "Right body controller: rcm LV state";
CM_ SG_ 549 VCRIGHT_lumbarLVState "Right body controller: lumbar LV state";
CM_ SG_ 549 VCRIGHT_3RUSBPowered "State of power to the 3R USB Ports";
CM_ SG_ 549 VCRIGHT_cntctrPwrState "Right body controller: cntctr pwr state";
CM_ SG_ 549 VCRIGHT_eFuseLockoutStatus "Right body controller: e fuse lockout status";
CM_ SG_ 549 VCRIGHT_swEnStatus "Status of the internal switched power rail on the board";
CM_ SG_ 549 VCRIGHT_vehiclePowerStateDBG "Right body controller: vehicle power state DBG";
CM_ SG_ 549 VCRIGHT_parkLVState "Right body controller: park LV state";
CM_ SG_ 549 VCRIGHT_icrLVState "Right body controller: icr LV state";
CM_ SG_ 549 VCRIGHT_interiorCameraLedLVState "Right body controller: interior camera led LV state";
CM_ SG_ 549 VCRIGHT_diLVState "Right body controller: di LV state";
CM_ SG_ 549 VCRIGHT_accDevicesDetected "At least one accessory device detected on accessory ports";
CM_ BO_ 643 "Right body controller message: PTC request";
CM_ SG_ 643 VCRIGHT_PTCLeftTargetPowerHV "Right body controller: PTC left target power HV";
CM_ SG_ 643 VCRIGHT_PTCRightTargetPowerHV "Right body controller: PTC right target power HV";
CM_ SG_ 643 VCRIGHT_PTCLeftTargetDuty "Right body controller: PTC left target duty";
CM_ SG_ 643 VCRIGHT_PTCRightTargetDuty "Right body controller: PTC right target duty";
CM_ SG_ 643 VCRIGHT_PTCFlagAllowOperation "Right body controller: PTC flag allow operation";
CM_ SG_ 643 VCRIGHT_PTCRequestMode "Right body controller: PTC request mode";
CM_ SG_ 643 VCRIGHT_PTCResistanceCheckEnable "Right body controller: PTC resistance check enable";
CM_ SG_ 643 VCRIGHT_PTCReset "Right body controller: PTC reset";
CM_ SG_ 643 VCRIGHT_PTCLeftDirectDriveIGBTO "Right body controller: PTC left direct drive IGBTO";
CM_ SG_ 643 VCRIGHT_PTCLeftDirectDriveIGBTC "Right body controller: PTC left direct drive IGBTC";
CM_ SG_ 643 VCRIGHT_PTCLeftDirectDriveIGBTI "Right body controller: PTC left direct drive IGBTI";
CM_ SG_ 643 VCRIGHT_PTCRightDirectDriveIGBTI "Right body controller: PTC right direct drive IGBTI";
CM_ SG_ 643 VCRIGHT_PTCRightDirectDriveIGBTC "Right body controller: PTC right direct drive IGBTC";
CM_ SG_ 643 VCRIGHT_PTCRightDirectDriveIGBTO "Right body controller: PTC right direct drive IGBTO";
CM_ BO_ 2011 "Right body controller message: alert log";
CM_ SG_ 2011 VCRIGHT_alertID "Right body controller: alert ID";
CM_ SG_ 2011 VCRIGHT_alertState "Right body controller: alert state";
CM_ SG_ 2011 VCRIGHT_a001_InternalWatchdog "Right body controller: a001 internal watchdog";
CM_ SG_ 2011 VCRIGHT_a010_UnderVoltageDetecte "Right body controller: a010 under voltage detected";
CM_ SG_ 2011 VCRIGHT_a010_UnderVoltageTimeout "Right body controller: a010 under voltage timeout";
CM_ SG_ 2011 VCRIGHT_a015_NVMMMemOverflow "Right body controller: a015 NVMM mem overflow";
CM_ SG_ 2011 VCRIGHT_a015_NVMMFilesystemError "Right body controller: a015 NVMM filesystem error";
CM_ SG_ 2011 VCRIGHT_a015_NVMMRecordIDError "Right body controller: a015 NVMM record ID error";
CM_ SG_ 2011 VCRIGHT_a057_VEH_cpControl "Right body controller: a057 VEH cp control";
CM_ SG_ 2011 VCRIGHT_a059_voltageDrop "Right body controller: a059 voltage drop";
CM_ SG_ 2011 VCRIGHT_a059_resistanceEstimate "Right body controller: a059 resistance estimate";
CM_ SG_ 2011 VCRIGHT_a059_current "Right body controller: a059 current";
CM_ SG_ 2011 VCRIGHT_a063_switchChannel "Right body controller: a063 switch channel";
CM_ SG_ 2011 VCRIGHT_a063_switchType "Right body controller: a063 switch type";
CM_ SG_ 2011 VCRIGHT_a063_ADCVoltage "Right body controller: a063 ADC voltage";
CM_ SG_ 2011 VCRIGHT_a063_disconnected "Right body controller: a063 disconnected";
CM_ SG_ 2011 VCRIGHT_a063_indeterminate "Right body controller: a063 indeterminate";
CM_ SG_ 2011 VCRIGHT_a063_stuckActive "Right body controller: a063 stuck active";
CM_ SG_ 2011 VCRIGHT_a063_faulted "Right body controller: a063 faulted";
CM_ SG_ 2011 VCRIGHT_a082_RIPC_epbPrivateStat "Right body controller: a082 RIPC epb private state";
CM_ SG_ 2011 VCRIGHT_a082_RIPC_remoteHSD "Right body controller: a082 RIPC remote HSD";
CM_ SG_ 2011 VCRIGHT_a082_RIPC_railStatus "Right body controller: a082 RIPC rail status";
CM_ SG_ 2011 VCRIGHT_a082_RIPC_remoteMux "Right body controller: a082 RIPC remote mux";
CM_ SG_ 2011 VCRIGHT_a083_LIPC_epbPrivateStat "Right body controller: a083 LIPC epb private state";
CM_ SG_ 2011 VCRIGHT_a083_LIPC_remoteHSD "Right body controller: a083 LIPC remote HSD";
CM_ SG_ 2011 VCRIGHT_a083_LIPC_railStatus "Right body controller: a083 LIPC rail status";
CM_ SG_ 2011 VCRIGHT_a083_LIPC_HSDFaults "Right body controller: a083 LIPC HSD faults";
CM_ SG_ 2011 VCRIGHT_a084_CH_StatusC "Right body controller: a084 CH status c";
CM_ SG_ 2011 VCRIGHT_a085_PARTY_buttonStatus "Right body controller: a085 PARTY button status";
CM_ SG_ 2011 VCRIGHT_a086_VEH_LVBMS_statusHig "Right body controller: a086 VEH LVBMS status high";
CM_ SG_ 2011 VCRIGHT_a086_VEH_LVBMS_statusLow "Right body controller: a086 VEH LVBMS status low";
CM_ SG_ 2011 VCRIGHT_a086_VEH_status "Right body controller: a086 VEH status";
CM_ SG_ 2011 VCRIGHT_a086_VEH_12VBatteryStatu "Right body controller: a086 VEH 12 v battery status";
CM_ SG_ 2011 VCRIGHT_a086_VEH_LVPowerState "Right body controller: a086 VEH LV power state";
CM_ SG_ 2011 VCRIGHT_a086_VEH_lightStatus "Right body controller: a086 VEH light status";
CM_ SG_ 2011 VCRIGHT_a086_VEH_systemStatus "Right body controller: a086 VEH system status";
CM_ SG_ 2011 VCRIGHT_a086_VEH_thermalStatus "Right body controller: a086 VEH thermal status";
CM_ SG_ 2011 VCRIGHT_a086_VEH_vehNm "Right body controller: a086 VEH veh nm";
CM_ SG_ 2011 VCRIGHT_a086_BDY_LVSelfTests "Right body controller: a086 BDY LV self tests";
CM_ SG_ 2011 VCRIGHT_a086_VEH_LVSelfTests "Right body controller: a086 VEH LV self tests";
CM_ SG_ 2011 VCRIGHT_a086_VEH_LVHealth "Right body controller: a086 VEH LV health";
CM_ SG_ 2011 VCRIGHT_a086_BDY_12VBatteryStatu "Right body controller: a086 BDY 12 v battery status";
CM_ SG_ 2011 VCRIGHT_a087_VEH_temperature "Right body controller: a087 VEH temperature";
CM_ SG_ 2011 VCRIGHT_a087_VEH_thermalControl "Right body controller: a087 VEH thermal control";
CM_ SG_ 2011 VCRIGHT_a087_VEH_torque "Right body controller: a087 VEH torque";
CM_ SG_ 2011 VCRIGHT_a087_VEH_status "Right body controller: a087 VEH status";
CM_ SG_ 2011 VCRIGHT_a087_PARTY_torque "Right body controller: a087 PARTY torque";
CM_ SG_ 2011 VCRIGHT_a087_PARTY_status "Right body controller: a087 PARTY status";
CM_ SG_ 2011 VCRIGHT_a087_PARTY_temperature "Right body controller: a087 PARTY temperature";
CM_ SG_ 2011 VCRIGHT_a087_PARTY_thermalContro "Right body controller: a087 PARTY thermal control";
CM_ SG_ 2011 VCRIGHT_a087_VEH_motorStatus "Right body controller: a087 VEH motor status";
CM_ SG_ 2011 VCRIGHT_a088_VEH_temperature "Right body controller: a088 VEH temperature";
CM_ SG_ 2011 VCRIGHT_a088_VEH_thermalControl "Right body controller: a088 VEH thermal control";
CM_ SG_ 2011 VCRIGHT_a088_VEH_torque "Right body controller: a088 VEH torque";
CM_ SG_ 2011 VCRIGHT_a088_VEH_status "Right body controller: a088 VEH status";
CM_ SG_ 2011 VCRIGHT_a088_PARTY_torque "Right body controller: a088 PARTY torque";
CM_ SG_ 2011 VCRIGHT_a088_PARTY_status "Right body controller: a088 PARTY status";
CM_ SG_ 2011 VCRIGHT_a088_PARTY_temperature "Right body controller: a088 PARTY temperature";
CM_ SG_ 2011 VCRIGHT_a088_PARTY_thermalContro "Right body controller: a088 PARTY thermal control";
CM_ SG_ 2011 VCRIGHT_a088_VEH_motorStatus "Right body controller: a088 VEH motor status";
CM_ SG_ 2011 VCRIGHT_a089_PARTY_party1 "Right body controller: a089 PARTY party1";
CM_ SG_ 2011 VCRIGHT_a089_PARTY_status "Right body controller: a089 PARTY status";
CM_ SG_ 2011 VCRIGHT_a089_VEH_status "Right body controller: a089 VEH status";
CM_ SG_ 2011 VCRIGHT_a089_BDY_party1 "Right body controller: a089 BDY party1";
CM_ SG_ 2011 VCRIGHT_a089_BDY_status "Right body controller: a089 BDY status";
CM_ SG_ 2011 VCRIGHT_a089_CH_status "Right body controller: a089 CH status";
CM_ SG_ 2011 VCRIGHT_a089_CH_party1 "Right body controller: a089 CH party1";
CM_ SG_ 2011 VCRIGHT_a089_CH_party3 "Right body controller: a089 CH party3";
CM_ SG_ 2011 VCRIGHT_a089_VEH_party1 "Right body controller: a089 VEH party1";
CM_ SG_ 2011 VCRIGHT_a089_VEH_party3 "Right body controller: a089 VEH party3";
CM_ SG_ 2011 VCRIGHT_a091_VEH_faultsAndExtras "Right body controller: a091 VEH faults and extras";
CM_ SG_ 2011 VCRIGHT_a091_VEH_info "Right body controller: a091 VEH info";
CM_ SG_ 2011 VCRIGHT_a091_VEH_state "Right body controller: a091 VEH state";
CM_ SG_ 2011 VCRIGHT_a092_VEH_restraintStatus "Right body controller: a092 VEH restraint status";
CM_ SG_ 2011 VCRIGHT_a092_VEH_switchStatus "Right body controller: a092 VEH switch status";
CM_ SG_ 2011 VCRIGHT_a092_VEH_seatStatus2 "Right body controller: a092 VEH seat status2";
CM_ SG_ 2011 VCRIGHT_a092_VEH_vehNm "Right body controller: a092 VEH veh nm";
CM_ SG_ 2011 VCRIGHT_a093_VEH_restraintStatus "Right body controller: a093 VEH restraint status";
CM_ SG_ 2011 VCRIGHT_a093_VEH_switchStatus "Right body controller: a093 VEH switch status";
CM_ SG_ 2011 VCRIGHT_a093_VEH_seatStatus2 "Right body controller: a093 VEH seat status2";
CM_ SG_ 2011 VCRIGHT_a093_VEH_vehNm "Right body controller: a093 VEH veh nm";
CM_ SG_ 2011 VCRIGHT_a094_VEH_sysStatus "Right body controller: a094 VEH sys status";
CM_ SG_ 2011 VCRIGHT_a094_PARTY_sysStatus "Right body controller: a094 PARTY sys status";
CM_ SG_ 2011 VCRIGHT_a094_CH_sysStatus "Right body controller: a094 CH sys status";
CM_ SG_ 2011 VCRIGHT_a095_PT_ptNm "Right body controller: a095 PT pt nm";
CM_ SG_ 2011 VCRIGHT_a095_PT_status "Right body controller: a095 PT status";
CM_ SG_ 2011 VCRIGHT_a096_VEH_status "Right body controller: a096 VEH status";
CM_ SG_ 2011 VCRIGHT_a096_CH_status "Right body controller: a096 CH status";
CM_ SG_ 2011 VCRIGHT_a097_VEH_HVStatus "Right body controller: a097 VEH HV status";
CM_ SG_ 2011 VCRIGHT_a097_VEH_state "Right body controller: a097 VEH state";
CM_ SG_ 2011 VCRIGHT_a098_CH_torque "Right body controller: a098 CH torque";
CM_ SG_ 2011 VCRIGHT_a098_VEH_hvStatus "Right body controller: a098 VEH hv status";
CM_ SG_ 2011 VCRIGHT_a098_VEH_status "Right body controller: a098 VEH status";
CM_ SG_ 2011 VCRIGHT_a098_VEH_thermalControl "Right body controller: a098 VEH thermal control";
CM_ SG_ 2011 VCRIGHT_a098_VEH_temperature "Right body controller: a098 VEH temperature";
CM_ SG_ 2011 VCRIGHT_a098_VEH_torque "Right body controller: a098 VEH torque";
CM_ SG_ 2011 VCRIGHT_a098_PARTY_status "Right body controller: a098 PARTY status";
CM_ SG_ 2011 VCRIGHT_a098_PARTY_temperature "Right body controller: a098 PARTY temperature";
CM_ SG_ 2011 VCRIGHT_a098_PARTY_thermalContro "Right body controller: a098 PARTY thermal control";
CM_ SG_ 2011 VCRIGHT_a098_PARTY_torque "Right body controller: a098 PARTY torque";
CM_ SG_ 2011 VCRIGHT_a098_PT_thermalControl "Right body controller: a098 PT thermal control";
CM_ SG_ 2011 VCRIGHT_a098_PT_temperature "Right body controller: a098 PT temperature";
CM_ SG_ 2011 VCRIGHT_a098_PARTY_motorStatus "Right body controller: a098 PARTY motor status";
CM_ SG_ 2011 VCRIGHT_a098_VEH_motorStatus "Right body controller: a098 VEH motor status";
CM_ SG_ 2011 VCRIGHT_a099_VEH_oocStatus "Right body controller: a099 VEH ooc status";
CM_ SG_ 2011 VCRIGHT_a100_VEH "Right body controller: a100 VEH";
CM_ SG_ 2011 VCRIGHT_a100_PARTY "Right body controller: a100 PARTY";
CM_ SG_ 2011 VCRIGHT_a100_PT "Right body controller: a100 PT";
CM_ SG_ 2011 VCRIGHT_a100_CH "Right body controller: a100 CH";
CM_ SG_ 2011 VCRIGHT_a100_OBD "Right body controller: a100 OBD";
CM_ SG_ 2011 VCRIGHT_a101_VEH_state "Right body controller: a101 VEH state";
CM_ SG_ 2011 VCRIGHT_a101_PARTY_locState "Right body controller: a101 PARTY loc state";
CM_ SG_ 2011 VCRIGHT_a101_LIPC_externalWatchd "Right body controller: a101 LIPC external watchdog heart beat";
CM_ SG_ 2011 VCRIGHT_a101_VEH_locState "Right body controller: a101 VEH loc state";
CM_ SG_ 2011 VCRIGHT_a101_BDY_locState "Right body controller: a101 BDY loc state";
CM_ SG_ 2011 VCRIGHT_a102_VEH_faultsAndExtras "Right body controller: a102 VEH faults and extras";
CM_ SG_ 2011 VCRIGHT_a102_VEH_feedbackStatus "Right body controller: a102 VEH feedback status";
CM_ SG_ 2011 VCRIGHT_a102_VEH_sensorStatus "Right body controller: a102 VEH sensor status";
CM_ SG_ 2011 VCRIGHT_a102_VEH_rods "Right body controller: a102 VEH rods";
CM_ SG_ 2011 VCRIGHT_a103_VEH_hvsNm "Right body controller: a103 VEH hvs nm";
CM_ SG_ 2011 VCRIGHT_a103_VEH_vehNm "Right body controller: a103 VEH veh nm";
CM_ SG_ 2011 VCRIGHT_a103_VEH_status "Right body controller: a103 VEH status";
CM_ SG_ 2011 VCRIGHT_a103_PT_ptNm "Right body controller: a103 PT pt nm";
CM_ SG_ 2011 VCRIGHT_a103_PT_status "Right body controller: a103 PT status";
CM_ SG_ 2011 VCRIGHT_a103_VEH_evseStatus "Right body controller: a103 VEH evse status";
CM_ SG_ 2011 VCRIGHT_a105_VEH_states "Right body controller: a105 VEH states";
CM_ SG_ 2011 VCRIGHT_a105_VEH_chNm "Right body controller: a105 VEH ch nm";
CM_ SG_ 2011 VCRIGHT_a105_VEH_dampingStates "Right body controller: a105 VEH damping states";
CM_ SG_ 2011 VCRIGHT_a106_VEH_dcdcStatus "Right body controller: a106 VEH dcdc status";
CM_ SG_ 2011 VCRIGHT_a106_VEH_thermalControl "Right body controller: a106 VEH thermal control";
CM_ SG_ 2011 VCRIGHT_a106_VEH_dcdcRailStatus "Right body controller: a106 VEH dcdc rail status";
CM_ SG_ 2011 VCRIGHT_a106_CH_dcdcRailStatus "Right body controller: a106 CH dcdc rail status";
CM_ SG_ 2011 VCRIGHT_a106_CH_alertMatrix "Right body controller: a106 CH alert matrix";
CM_ SG_ 2011 VCRIGHT_a107_VEH_hvsNm "Right body controller: a107 VEH hvs nm";
CM_ SG_ 2011 VCRIGHT_a107_VEH_vehNm "Right body controller: a107 VEH veh nm";
CM_ SG_ 2011 VCRIGHT_a107_VEH_status "Right body controller: a107 VEH status";
CM_ SG_ 2011 VCRIGHT_a107_VEH_thermalStatus "Right body controller: a107 VEH thermal status";
CM_ SG_ 2011 VCRIGHT_a107_VEH_bmbMinMax "Right body controller: a107 VEH bmb min max";
CM_ SG_ 2011 VCRIGHT_a107_VEH_powerAvailable "Right body controller: a107 VEH power available";
CM_ SG_ 2011 VCRIGHT_a107_PT_ptNm "Right body controller: a107 PT pt nm";
CM_ SG_ 2011 VCRIGHT_a107_PT_status "Right body controller: a107 PT status";
CM_ SG_ 2011 VCRIGHT_a107_PT_thermalStatus "Right body controller: a107 PT thermal status";
CM_ SG_ 2011 VCRIGHT_a107_PT_socStatus "Right body controller: a107 PT soc status";
CM_ SG_ 2011 VCRIGHT_a107_VEH_socStatus "Right body controller: a107 VEH soc status";
CM_ SG_ 2011 VCRIGHT_a107_VEH_packConfig "Right body controller: a107 VEH pack config";
CM_ SG_ 2011 VCRIGHT_a107_VEH_energyStatus "Right body controller: a107 VEH energy status";
CM_ SG_ 2011 VCRIGHT_a107_VEH_chargeInfo "Right body controller: a107 VEH charge info";
CM_ SG_ 2011 VCRIGHT_a108_VEH_hvStatus "Right body controller: a108 VEH hv status";
CM_ SG_ 2011 VCRIGHT_a108_VEH_temperature "Right body controller: a108 VEH temperature";
CM_ SG_ 2011 VCRIGHT_a108_VEH_thermalControl "Right body controller: a108 VEH thermal control";
CM_ SG_ 2011 VCRIGHT_a108_VEH_torque "Right body controller: a108 VEH torque";
CM_ SG_ 2011 VCRIGHT_a108_VEH_status "Right body controller: a108 VEH status";
CM_ SG_ 2011 VCRIGHT_a108_PARTY_torque "Right body controller: a108 PARTY torque";
CM_ SG_ 2011 VCRIGHT_a108_PARTY_status "Right body controller: a108 PARTY status";
CM_ SG_ 2011 VCRIGHT_a108_PARTY_temperature "Right body controller: a108 PARTY temperature";
CM_ SG_ 2011 VCRIGHT_a108_PARTY_thermalContro "Right body controller: a108 PARTY thermal control";
CM_ SG_ 2011 VCRIGHT_a108_PT_temperature "Right body controller: a108 PT temperature";
CM_ SG_ 2011 VCRIGHT_a108_PT_thermalControl "Right body controller: a108 PT thermal control";
CM_ SG_ 2011 VCRIGHT_a108_PARTY_motorStatus "Right body controller: a108 PARTY motor status";
CM_ SG_ 2011 VCRIGHT_a108_VEH_motorStatus "Right body controller: a108 VEH motor status";
CM_ SG_ 2011 VCRIGHT_a108_CH_torque "Right body controller: a108 CH torque";
CM_ SG_ 2011 VCRIGHT_a110_VEH_carState "Right body controller: a110 VEH car state";
CM_ SG_ 2011 VCRIGHT_a110_VEH_carConfig "Right body controller: a110 VEH car config";
CM_ SG_ 2011 VCRIGHT_a110_VEH_time "Right body controller: a110 VEH time";
CM_ SG_ 2011 VCRIGHT_a110_VEH_updateStatus "Right body controller: a110 VEH update status";
CM_ SG_ 2011 VCRIGHT_a110_VEH_vehNm "Right body controller: a110 VEH veh nm";
CM_ SG_ 2011 VCRIGHT_a110_VEH_mismatchFault "Right body controller: a110 VEH mismatch fault";
CM_ SG_ 2011 VCRIGHT_a110_VEH_vin "Right body controller: a110 VEH vin";
CM_ SG_ 2011 VCRIGHT_a110_VEH_bmpDebug "Right body controller: a110 VEH bmp debug";
CM_ SG_ 2011 VCRIGHT_a110_VEH_gearControl "Right body controller: a110 VEH gear control";
CM_ SG_ 2011 VCRIGHT_a110_VEH_canLogAvailabil "Right body controller: a110 VEH can log availability";
CM_ SG_ 2011 VCRIGHT_a110_CH_airbagCutoffStat "Right body controller: a110 CH airbag cutoff status";
CM_ SG_ 2011 VCRIGHT_a110_CH_carConfig "Right body controller: a110 CH car config";
CM_ SG_ 2011 VCRIGHT_a110_CH_carState "Right body controller: a110 CH car state";
CM_ SG_ 2011 VCRIGHT_a110_CH_vin "Right body controller: a110 CH vin";
CM_ SG_ 2011 VCRIGHT_a110_CH_chNm "Right body controller: a110 CH ch nm";
CM_ SG_ 2011 VCRIGHT_a110_CH_epochTimeGtw "Right body controller: a110 CH epoch time gtw";
CM_ SG_ 2011 VCRIGHT_a110_PARTY_carConfig "Right body controller: a110 PARTY car config";
CM_ SG_ 2011 VCRIGHT_a111_VEH_internalStatus "Right body controller: a111 VEH internal status";
CM_ SG_ 2011 VCRIGHT_a111_VEH_status "Right body controller: a111 VEH status";
CM_ SG_ 2011 VCRIGHT_a111_VEH_vehNm "Right body controller: a111 VEH veh nm";
CM_ SG_ 2011 VCRIGHT_a111_RIPC_LVPowerState "Right body controller: a111 RIPC LV power state";
CM_ SG_ 2011 VCRIGHT_a111_RIPC_epbPrivateStat "Right body controller: a111 RIPC epb private state";
CM_ SG_ 2011 VCRIGHT_a111_RIPC_railStatus "Right body controller: a111 RIPC rail status";
CM_ SG_ 2011 VCRIGHT_a111_RIPC_remoteADC "Right body controller: a111 RIPC remote ADC";
CM_ SG_ 2011 VCRIGHT_a111_RIPC_switchStatus "Right body controller: a111 RIPC switch status";
CM_ SG_ 2011 VCRIGHT_a111_VEH_LVPowerState "Right body controller: a111 VEH LV power state";
CM_ SG_ 2011 VCRIGHT_a111_VEH_seatStatus "Right body controller: a111 VEH seat status";
CM_ SG_ 2011 VCRIGHT_a111_PARTY_status "Right body controller: a111 PARTY status";
CM_ SG_ 2011 VCRIGHT_a111_CH_status "Right body controller: a111 CH status";
CM_ SG_ 2011 VCRIGHT_a112_VEH_internalStatus "Right body controller: a112 VEH internal status";
CM_ SG_ 2011 VCRIGHT_a112_VEH_status "Right body controller: a112 VEH status";
CM_ SG_ 2011 VCRIGHT_a112_VEH_vehNm "Right body controller: a112 VEH veh nm";
CM_ SG_ 2011 VCRIGHT_a112_LIPC_LVPowerState "Right body controller: a112 LIPC LV power state";
CM_ SG_ 2011 VCRIGHT_a112_LIPC_epbPrivateStat "Right body controller: a112 LIPC epb private state";
CM_ SG_ 2011 VCRIGHT_a112_LIPC_railStatus "Right body controller: a112 LIPC rail status";
CM_ SG_ 2011 VCRIGHT_a112_LIPC_remoteADC "Right body controller: a112 LIPC remote ADC";
CM_ SG_ 2011 VCRIGHT_a112_LIPC_switchStatus "Right body controller: a112 LIPC switch status";
CM_ SG_ 2011 VCRIGHT_a112_VEH_LVPowerState "Right body controller: a112 VEH LV power state";
CM_ SG_ 2011 VCRIGHT_a112_PARTY_status "Right body controller: a112 PARTY status";
CM_ SG_ 2011 VCRIGHT_a112_CH_status "Right body controller: a112 CH status";
CM_ SG_ 2011 VCRIGHT_a114_PARTY_status "Right body controller: a114 PARTY status";
CM_ SG_ 2011 VCRIGHT_a114_PARTY_wheelSpeeds "Right body controller: a114 PARTY wheel speeds";
CM_ SG_ 2011 VCRIGHT_a114_VEH_wheelSpeeds "Right body controller: a114 VEH wheel speeds";
CM_ SG_ 2011 VCRIGHT_a114_CH_wheelSpeeds "Right body controller: a114 CH wheel speeds";
CM_ SG_ 2011 VCRIGHT_a114_PARTY_party3 "Right body controller: a114 PARTY party3";
CM_ SG_ 2011 VCRIGHT_a114_VEH_party3 "Right body controller: a114 VEH party3";
CM_ SG_ 2011 VCRIGHT_a114_VEH_status "Right body controller: a114 VEH status";
CM_ SG_ 2011 VCRIGHT_a114_PARTY_wheelRotation "Right body controller: a114 PARTY wheel rotation";
CM_ SG_ 2011 VCRIGHT_a114_CH_wheelRotation "Right body controller: a114 CH wheel rotation";
CM_ SG_ 2011 VCRIGHT_a114_VEH_wheelRotation "Right body controller: a114 VEH wheel rotation";
CM_ SG_ 2011 VCRIGHT_a114_PARTY_brakeTorque "Right body controller: a114 PARTY brake torque";
CM_ SG_ 2011 VCRIGHT_a114_PARTY_offsets "Right body controller: a114 PARTY offsets";
CM_ SG_ 2011 VCRIGHT_a114_BDY_offsets "Right body controller: a114 BDY offsets";
CM_ SG_ 2011 VCRIGHT_a114_BDY_party3 "Right body controller: a114 BDY party3";
CM_ SG_ 2011 VCRIGHT_a114_BDY_status "Right body controller: a114 BDY status";
CM_ SG_ 2011 VCRIGHT_a114_BDY_wheelRotation "Right body controller: a114 BDY wheel rotation";
CM_ SG_ 2011 VCRIGHT_a114_BDY_wheelSpeeds "Right body controller: a114 BDY wheel speeds";
CM_ SG_ 2011 VCRIGHT_a114_CH_party1 "Right body controller: a114 CH party1";
CM_ SG_ 2011 VCRIGHT_a114_CH_party3 "Right body controller: a114 CH party3";
CM_ SG_ 2011 VCRIGHT_a114_CH_status "Right body controller: a114 CH status";
CM_ SG_ 2011 VCRIGHT_a115_VEH_vehNm "Right body controller: a115 VEH veh nm";
CM_ SG_ 2011 VCRIGHT_a115_VEH_authentication "Right body controller: a115 VEH authentication";
CM_ SG_ 2011 VCRIGHT_a115_VEH_BLEResetRequest "Right body controller: a115 VEH BLE reset request";
CM_ SG_ 2011 VCRIGHT_a115_VEH_requests "Right body controller: a115 VEH requests";
CM_ SG_ 2011 VCRIGHT_a115_VEH_requests2 "Right body controller: a115 VEH requests2";
CM_ SG_ 2011 VCRIGHT_a115_REM_authentication "Right body controller: a115 REM authentication";
CM_ SG_ 2011 VCRIGHT_a115_UI_corianderVehicle "Right body controller: a115 UI coriander vehicle control";
CM_ SG_ 2011 VCRIGHT_a115_CH_TPMSDisplay "Right body controller: a115 CH TPMS display";
CM_ SG_ 2011 VCRIGHT_a115_VEH_RSSI "Right body controller: a115 VEH RSSI";
CM_ SG_ 2011 VCRIGHT_a115_VEH_authenticationW "Right body controller: a115 VEH authentication with mac";
CM_ SG_ 2011 VCRIGHT_a115_VEH_endpointTemp "Right body controller: a115 VEH endpoint temp";
CM_ SG_ 2011 VCRIGHT_a115_VEH_ChildSeatStatus "Right body controller: a115 VEH child seat status";
CM_ SG_ 2011 VCRIGHT_a115_BDY_ChildSeatStatus "Right body controller: a115 BDY child seat status";
CM_ SG_ 2011 VCRIGHT_a115_BDY_endpointTemp "Right body controller: a115 BDY endpoint temp";
CM_ SG_ 2011 VCRIGHT_a115_BDY_BLEResetRequest "Right body controller: a115 BDY BLE reset request";
CM_ SG_ 2011 VCRIGHT_a115_BDY_RSSI "Right body controller: a115 BDY RSSI";
CM_ SG_ 2011 VCRIGHT_a115_BDY_authentication "Right body controller: a115 BDY authentication";
CM_ SG_ 2011 VCRIGHT_a115_BDY_requests "Right body controller: a115 BDY requests";
CM_ SG_ 2011 VCRIGHT_a115_BDY_requests2 "Right body controller: a115 BDY requests2";
CM_ SG_ 2011 VCRIGHT_a115_BDY_vehNm "Right body controller: a115 BDY veh nm";
CM_ SG_ 2011 VCRIGHT_a115_BDY_authenticationW "Right body controller: a115 BDY authentication with mac";
CM_ SG_ 2011 VCRIGHT_a116_PARTY_epbmStatus "Right body controller: a116 PARTY epbm status";
CM_ SG_ 2011 VCRIGHT_a116_VEH_vehNm "Right body controller: a116 VEH veh nm";
CM_ SG_ 2011 VCRIGHT_a116_VEH_hvacRequest "Right body controller: a116 VEH hvac request";
CM_ SG_ 2011 VCRIGHT_a116_VEH_hvacStatus "Right body controller: a116 VEH hvac status";
CM_ SG_ 2011 VCRIGHT_a116_VEH_LVPowerState "Right body controller: a116 VEH LV power state";
CM_ SG_ 2011 VCRIGHT_a116_VEH_lightStatus "Right body controller: a116 VEH light status";
CM_ SG_ 2011 VCRIGHT_a116_VEH_seatStatus "Right body controller: a116 VEH seat status";
CM_ SG_ 2011 VCRIGHT_a116_VEH_thsStatus "Right body controller: a116 VEH ths status";
CM_ SG_ 2011 VCRIGHT_a116_VEH_doorStatus "Right body controller: a116 VEH door status";
CM_ SG_ 2011 VCRIGHT_a116_VEH_seatHeatStatus "Right body controller: a116 VEH seat heat status";
CM_ SG_ 2011 VCRIGHT_a116_VEH_restraintStatus "Right body controller: a116 VEH restraint status";
CM_ SG_ 2011 VCRIGHT_a116_VEH_switchStatus "Right body controller: a116 VEH switch status";
CM_ SG_ 2011 VCRIGHT_a116_VEH_logging1Hz "Right body controller: a116 VEH logging1 hz";
CM_ SG_ 2011 VCRIGHT_a116_VEH_seatStatus2 "Right body controller: a116 VEH seat status2";
CM_ SG_ 2011 VCRIGHT_a116_VEH_status "Right body controller: a116 VEH status";
CM_ SG_ 2011 VCRIGHT_a116_VEH_thermalCommand "Right body controller: a116 VEH thermal command";
CM_ SG_ 2011 VCRIGHT_a116_VEH_windowStatus "Right body controller: a116 VEH window status";
CM_ SG_ 2011 VCRIGHT_a116_PARTY_restraintStat "Right body controller: a116 PARTY restraint status";
CM_ SG_ 2011 VCRIGHT_a116_PARTY_doorStatus "Right body controller: a116 PARTY door status";
CM_ SG_ 2011 VCRIGHT_a116_BDY_epbmStatus "Right body controller: a116 BDY epbm status";
CM_ SG_ 2011 VCRIGHT_a116_BDY_restraintStatus "Right body controller: a116 BDY restraint status";
CM_ SG_ 2011 VCRIGHT_a116_BDY_switchStatus "Right body controller: a116 BDY switch status";
CM_ SG_ 2011 VCRIGHT_a117_BDY_epbmStatus "Right body controller: a117 BDY epbm status";
CM_ SG_ 2011 VCRIGHT_a117_BDY_restraintStatus "Right body controller: a117 BDY restraint status";
CM_ SG_ 2011 VCRIGHT_a117_VEH_prndStatus "Right body controller: a117 VEH prnd status";
CM_ SG_ 2011 VCRIGHT_a117_PARTY_epbmStatus "Right body controller: a117 PARTY epbm status";
CM_ SG_ 2011 VCRIGHT_a117_VEH_vehNm "Right body controller: a117 VEH veh nm";
CM_ SG_ 2011 VCRIGHT_a117_VEH_hvacBlowerFdb "Right body controller: a117 VEH hvac blower fdb";
CM_ SG_ 2011 VCRIGHT_a117_VEH_LVPowerState "Right body controller: a117 VEH LV power state";
CM_ SG_ 2011 VCRIGHT_a117_VEH_restraintStatus "Right body controller: a117 VEH restraint status";
CM_ SG_ 2011 VCRIGHT_a117_VEH_lightStatus "Right body controller: a117 VEH light status";
CM_ SG_ 2011 VCRIGHT_a117_VEH_seatStatus "Right body controller: a117 VEH seat status";
CM_ SG_ 2011 VCRIGHT_a117_BDY_falconSwitchSta "Right body controller: a117 BDY falcon switch status";
CM_ SG_ 2011 VCRIGHT_a117_VEH_doorStatus "Right body controller: a117 VEH door status";
CM_ SG_ 2011 VCRIGHT_a117_VEH_doorStatus2 "Right body controller: a117 VEH door status2";
CM_ SG_ 2011 VCRIGHT_a117_VEH_windowStatus "Right body controller: a117 VEH window status";
CM_ SG_ 2011 VCRIGHT_a117_VEH_switchStatus "Right body controller: a117 VEH switch status";
CM_ SG_ 2011 VCRIGHT_a117_VEH_intrusionSensor "Right body controller: a117 VEH intrusion sensor status";
CM_ SG_ 2011 VCRIGHT_a117_VEH_liftgateStatus "Right body controller: a117 VEH liftgate status";
CM_ SG_ 2011 VCRIGHT_a117_VEH_seatStatus2 "Right body controller: a117 VEH seat status2";
CM_ SG_ 2011 VCRIGHT_a117_PARTY_restraintStat "Right body controller: a117 PARTY restraint status";
CM_ SG_ 2011 VCRIGHT_a117_VEH_thermalStatus "Right body controller: a117 VEH thermal status";
CM_ SG_ 2011 VCRIGHT_a117_PARTY_doorStatus "Right body controller: a117 PARTY door status";
CM_ SG_ 2011 VCRIGHT_a117_VEH_status "Right body controller: a117 VEH status";
CM_ SG_ 2011 VCRIGHT_a117_PARTY_prndStatus "Right body controller: a117 PARTY prnd status";
CM_ SG_ 2011 VCRIGHT_a117_PARTY_lightingSecon "Right body controller: a117 PARTY lighting secondary";
CM_ SG_ 2011 VCRIGHT_a117_BDY_lightingSeconda "Right body controller: a117 BDY lighting secondary";
CM_ SG_ 2011 VCRIGHT_a117_BDY_hvacBlowerFdb "Right body controller: a117 BDY hvac blower fdb";
CM_ SG_ 2011 VCRIGHT_a117_BDY_thermalStatus "Right body controller: a117 BDY thermal status";
CM_ SG_ 2011 VCRIGHT_a117_BDY_status "Right body controller: a117 BDY status";
CM_ SG_ 2011 VCRIGHT_a117_VEH_liftgateLeaderR "Right body controller: a117 VEH liftgate leader request";
CM_ SG_ 2011 VCRIGHT_a118_VEH_vehNm "Right body controller: a118 VEH veh nm";
CM_ SG_ 2011 VCRIGHT_a118_VEH_lighting "Right body controller: a118 VEH lighting";
CM_ SG_ 2011 VCRIGHT_a118_VEH_sensors "Right body controller: a118 VEH sensors";
CM_ SG_ 2011 VCRIGHT_a118_VEH_status "Right body controller: a118 VEH status";
CM_ SG_ 2011 VCRIGHT_a118_VEH_okToUseHighPwr "Right body controller: a118 VEH ok to use high pwr";
CM_ SG_ 2011 VCRIGHT_a118_VEH_LVPowerState "Right body controller: a118 VEH LV power state";
CM_ SG_ 2011 VCRIGHT_a118_VEH_coolant "Right body controller: a118 VEH coolant";
CM_ SG_ 2011 VCRIGHT_a118_VEH_vehicleStatus "Right body controller: a118 VEH vehicle status";
CM_ SG_ 2011 VCRIGHT_a118_VEH_12VBatteryStatu "Right body controller: a118 VEH 12 v battery status";
CM_ SG_ 2011 VCRIGHT_a118_VEH_systemStatus "Right body controller: a118 VEH system status";
CM_ SG_ 2011 VCRIGHT_a118_PARTY_LVPowerState "Right body controller: a118 PARTY LV power state";
CM_ SG_ 2011 VCRIGHT_a118_PARTY_outputPowerSt "Right body controller: a118 PARTY output power status";
CM_ SG_ 2011 VCRIGHT_a118_PARTY_vehicleTime "Right body controller: a118 PARTY vehicle time";
CM_ SG_ 2011 VCRIGHT_a118_VEH_thermalCommand "Right body controller: a118 VEH thermal command";
CM_ SG_ 2011 VCRIGHT_a118_CH_LVPowerState "Right body controller: a118 CH LV power state";
CM_ SG_ 2011 VCRIGHT_a118_PARTY_sensors "Right body controller: a118 PARTY sensors";
CM_ SG_ 2011 VCRIGHT_a118_CH_sensors "Right body controller: a118 CH sensors";
CM_ SG_ 2011 VCRIGHT_a118_VEH_interNodeResist "Right body controller: a118 VEH inter node resistance";
CM_ SG_ 2011 VCRIGHT_a118_CH_lighting "Right body controller: a118 CH lighting";
CM_ SG_ 2011 VCRIGHT_a118_VEH_lightStatus "Right body controller: a118 VEH light status";
CM_ SG_ 2011 VCRIGHT_a118_PARTY_vehNm "Right body controller: a118 PARTY veh nm";
CM_ SG_ 2011 VCRIGHT_a118_CH_12VBatteryStatus "Right body controller: a118 CH 12 v battery status";
CM_ SG_ 2011 VCRIGHT_a118_CH_LVBMS_statusHigh "Right body controller: a118 CH LVBMS status high";
CM_ SG_ 2011 VCRIGHT_a118_CH_alertMatrix "Right body controller: a118 CH alert matrix";
CM_ SG_ 2011 VCRIGHT_a118_BDY_outputPowerStat "Right body controller: a118 BDY output power status";
CM_ SG_ 2011 VCRIGHT_a118_BDY_vehicleTime "Right body controller: a118 BDY vehicle time";
CM_ SG_ 2011 VCRIGHT_a118_PARTY_AP_vehicleSta "Right body controller: a118 PARTY AP vehicle state1 hz muxed";
CM_ SG_ 2011 VCRIGHT_a118_BDY_AP_vehicleState "Right body controller: a118 BDY AP vehicle state1 hz muxed";
CM_ SG_ 2011 VCRIGHT_a118_PARTY_VCFRONT_camer "Right body controller: a118 PARTY VCFRONT camera cleaning status";
CM_ SG_ 2011 VCRIGHT_a118_VEH_LVHealth "Right body controller: a118 VEH LV health";
CM_ SG_ 2011 VCRIGHT_a118_BDY_LVHealth "Right body controller: a118 BDY LV health";
CM_ SG_ 2011 VCRIGHT_a119_VEH_steerAngle "Right body controller: a119 VEH steer angle";
CM_ SG_ 2011 VCRIGHT_a119_VEH_leftStalk "Right body controller: a119 VEH left stalk";
CM_ SG_ 2011 VCRIGHT_a119_VEH_rightStalk "Right body controller: a119 VEH right stalk";
CM_ SG_ 2011 VCRIGHT_a119_PARTY_rightStalk "Right body controller: a119 PARTY right stalk";
CM_ SG_ 2011 VCRIGHT_a119_CH_steerAngle "Right body controller: a119 CH steer angle";
CM_ SG_ 2011 VCRIGHT_a119_PARTY_steerAngle "Right body controller: a119 PARTY steer angle";
CM_ SG_ 2011 VCRIGHT_a120_PARTY_chassisCntl "Right body controller: a120 PARTY chassis cntl";
CM_ SG_ 2011 VCRIGHT_a120_VEH_systemStatus "Right body controller: a120 VEH system status";
CM_ SG_ 2011 VCRIGHT_a120_CH_chassisCntl "Right body controller: a120 CH chassis cntl";
CM_ SG_ 2011 VCRIGHT_a120_PARTY_systemStatus "Right body controller: a120 PARTY system status";
CM_ SG_ 2011 VCRIGHT_a120_PARTY_torque "Right body controller: a120 PARTY torque";
CM_ SG_ 2011 VCRIGHT_a120_VEH_torque "Right body controller: a120 VEH torque";
CM_ SG_ 2011 VCRIGHT_a120_PARTY_locStatus "Right body controller: a120 PARTY loc status";
CM_ SG_ 2011 VCRIGHT_a120_PARTY_speed "Right body controller: a120 PARTY speed";
CM_ SG_ 2011 VCRIGHT_a120_VEH_speed "Right body controller: a120 VEH speed";
CM_ SG_ 2011 VCRIGHT_a120_PARTY_status "Right body controller: a120 PARTY status";
CM_ SG_ 2011 VCRIGHT_a120_PT_speed "Right body controller: a120 PT speed";
CM_ SG_ 2011 VCRIGHT_a120_PT_systemStatus "Right body controller: a120 PT system status";
CM_ SG_ 2011 VCRIGHT_a120_PARTY_vehicleEstima "Right body controller: a120 PARTY vehicle estimates";
CM_ SG_ 2011 VCRIGHT_a120_VEH_aggregatedAxleS "Right body controller: a120 VEH aggregated axle speed";
CM_ SG_ 2011 VCRIGHT_a120_PARTY_aggregatedAxl "Right body controller: a120 PARTY aggregated axle speed";
CM_ SG_ 2011 VCRIGHT_a120_VEH_systemPower "Right body controller: a120 VEH system power";
CM_ SG_ 2011 VCRIGHT_a120_PARTY_autonomyHealt "Right body controller: a120 PARTY autonomy health";
CM_ SG_ 2011 VCRIGHT_a120_VEH_autonomyHealth "Right body controller: a120 VEH autonomy health";
CM_ SG_ 2011 VCRIGHT_a120_PT_systemPower "Right body controller: a120 PT system power";
CM_ SG_ 2011 VCRIGHT_a120_PARTY_stalklessInte "Right body controller: a120 PARTY stalkless interfaces";
CM_ SG_ 2011 VCRIGHT_a120_CH_speed "Right body controller: a120 CH speed";
CM_ SG_ 2011 VCRIGHT_a120_VEH_estimatedBrakeT "Right body controller: a120 VEH estimated brake temp";
CM_ SG_ 2011 VCRIGHT_a120_PARTY_prndControl "Right body controller: a120 PARTY prnd control";
CM_ SG_ 2011 VCRIGHT_a120_PARTY_locStatus2 "Right body controller: a120 PARTY loc status2";
CM_ SG_ 2011 VCRIGHT_a120_VEH_chassisCntl "Right body controller: a120 VEH chassis cntl";
CM_ SG_ 2011 VCRIGHT_a120_CH_locStatus2 "Right body controller: a120 CH loc status2";
CM_ SG_ 2011 VCRIGHT_a120_VEH_locStatus "Right body controller: a120 VEH loc status";
CM_ SG_ 2011 VCRIGHT_a120_VEH_locStatus2 "Right body controller: a120 VEH loc status2";
CM_ SG_ 2011 VCRIGHT_a120_VEH_prndControl "Right body controller: a120 VEH prnd control";
CM_ SG_ 2011 VCRIGHT_a120_VEH_vehicleEstimate "Right body controller: a120 VEH vehicle estimates";
CM_ SG_ 2011 VCRIGHT_a120_PARTY_motorStatus "Right body controller: a120 PARTY motor status";
CM_ SG_ 2011 VCRIGHT_a120_VEH_motorStatus "Right body controller: a120 VEH motor status";
CM_ SG_ 2011 VCRIGHT_a120_BDY_speed "Right body controller: a120 BDY speed";
CM_ SG_ 2011 VCRIGHT_a121_OBD_status "Right body controller: a121 OBD status";
CM_ SG_ 2011 VCRIGHT_a124_PARTY_status "Right body controller: a124 PARTY status";
CM_ SG_ 2011 VCRIGHT_a124_BDY_status "Right body controller: a124 BDY status";
CM_ SG_ 2011 VCRIGHT_a124_VEH_status "Right body controller: a124 VEH status";
CM_ SG_ 2011 VCRIGHT_a125_PARTY_actuation "Right body controller: a125 PARTY actuation";
CM_ SG_ 2011 VCRIGHT_a125_BDY_actuation "Right body controller: a125 BDY actuation";
CM_ SG_ 2011 VCRIGHT_a125_PARTY_status "Right body controller: a125 PARTY status";
CM_ SG_ 2011 VCRIGHT_a125_BDY_status "Right body controller: a125 BDY status";
CM_ SG_ 2011 VCRIGHT_a136_hvacIntakeStall "Right body controller: a136 hvac intake stall";
CM_ SG_ 2011 VCRIGHT_a137_hvacLHBleedStall "Right body controller: a137 hvac LH bleed stall";
CM_ SG_ 2011 VCRIGHT_a138_hvacRHBleedStall "Right body controller: a138 hvac RH bleed stall";
CM_ SG_ 2011 VCRIGHT_a139_hvacLHVaneStall "Right body controller: a139 hvac LH vane stall";
CM_ SG_ 2011 VCRIGHT_a140_hvacRHVaneStall "Right body controller: a140 hvac RH vane stall";
CM_ SG_ 2011 VCRIGHT_a141_hvacUpperModeStall "Right body controller: a141 hvac upper mode stall";
CM_ SG_ 2011 VCRIGHT_a142_hvacLowerModeStall "Right body controller: a142 hvac lower mode stall";
CM_ SG_ 2011 VCRIGHT_a144_snsShortCircuit "Right body controller: a144 sns short circuit";
CM_ SG_ 2011 VCRIGHT_a144_snsDisconnect "Right body controller: a144 sns disconnect";
CM_ SG_ 2011 VCRIGHT_a144_snsRateChangeUp "Right body controller: a144 sns rate change up";
CM_ SG_ 2011 VCRIGHT_a144_snsRateChangeDown "Right body controller: a144 sns rate change down";
CM_ SG_ 2011 VCRIGHT_a145_snsShortCircuit "Right body controller: a145 sns short circuit";
CM_ SG_ 2011 VCRIGHT_a145_snsDisconnect "Right body controller: a145 sns disconnect";
CM_ SG_ 2011 VCRIGHT_a145_snsRateChangeUp "Right body controller: a145 sns rate change up";
CM_ SG_ 2011 VCRIGHT_a145_snsRateChangeDown "Right body controller: a145 sns rate change down";
CM_ SG_ 2011 VCRIGHT_a146_snsShortCircuit "Right body controller: a146 sns short circuit";
CM_ SG_ 2011 VCRIGHT_a146_snsDisconnect "Right body controller: a146 sns disconnect";
CM_ SG_ 2011 VCRIGHT_a146_snsRateChangeUp "Right body controller: a146 sns rate change up";
CM_ SG_ 2011 VCRIGHT_a146_snsRateChangeDown "Right body controller: a146 sns rate change down";
CM_ SG_ 2011 VCRIGHT_a147_snsShortCircuit "Right body controller: a147 sns short circuit";
CM_ SG_ 2011 VCRIGHT_a147_snsDisconnect "Right body controller: a147 sns disconnect";
CM_ SG_ 2011 VCRIGHT_a147_snsRateChangeUp "Right body controller: a147 sns rate change up";
CM_ SG_ 2011 VCRIGHT_a147_snsRateChangeDown "Right body controller: a147 sns rate change down";
CM_ SG_ 2011 VCRIGHT_a148_snsShortCircuit "Right body controller: a148 sns short circuit";
CM_ SG_ 2011 VCRIGHT_a148_snsDisconnect "Right body controller: a148 sns disconnect";
CM_ SG_ 2011 VCRIGHT_a148_snsRateChangeUp "Right body controller: a148 sns rate change up";
CM_ SG_ 2011 VCRIGHT_a148_snsRateChangeDown "Right body controller: a148 sns rate change down";
CM_ SG_ 2011 VCRIGHT_a149_snsShortCircuit "Right body controller: a149 sns short circuit";
CM_ SG_ 2011 VCRIGHT_a149_snsDisconnect "Right body controller: a149 sns disconnect";
CM_ SG_ 2011 VCRIGHT_a149_snsRateChangeUp "Right body controller: a149 sns rate change up";
CM_ SG_ 2011 VCRIGHT_a149_snsRateChangeDown "Right body controller: a149 sns rate change down";
CM_ SG_ 2011 VCRIGHT_a150_windowPosition "Right body controller: a150 window position";
CM_ SG_ 2011 VCRIGHT_a150_movementTimeMs "Right body controller: a150 movement time ms";
CM_ SG_ 2011 VCRIGHT_a150_windowPinchReason "Right body controller: a150 window pinch reason";
CM_ SG_ 2011 VCRIGHT_a150_lookbackIndex "Right body controller: a150 lookback index";
CM_ SG_ 2011 VCRIGHT_a150_absAccelExceedance "Right body controller: a150 abs accel exceedance";
CM_ SG_ 2011 VCRIGHT_a150_relAccelExceedance "Right body controller: a150 rel accel exceedance";
CM_ SG_ 2011 VCRIGHT_a150_speedExpScore "Right body controller: a150 speed exp score";
CM_ SG_ 2011 VCRIGHT_a150_treatedInGear "Right body controller: a150 treated in gear";
CM_ SG_ 2011 VCRIGHT_a151_windowPosition "Right body controller: a151 window position";
CM_ SG_ 2011 VCRIGHT_a151_movementTimeMs "Right body controller: a151 movement time ms";
CM_ SG_ 2011 VCRIGHT_a151_windowPinchReason "Right body controller: a151 window pinch reason";
CM_ SG_ 2011 VCRIGHT_a151_lookbackIndex "Right body controller: a151 lookback index";
CM_ SG_ 2011 VCRIGHT_a151_absAccelExceedance "Right body controller: a151 abs accel exceedance";
CM_ SG_ 2011 VCRIGHT_a151_relAccelExceedance "Right body controller: a151 rel accel exceedance";
CM_ SG_ 2011 VCRIGHT_a151_speedExpScore "Right body controller: a151 speed exp score";
CM_ SG_ 2011 VCRIGHT_a151_treatedInGear "Right body controller: a151 treated in gear";
CM_ SG_ 2011 VCRIGHT_a152_zeroed "Right body controller: a152 zeroed";
CM_ SG_ 2011 VCRIGHT_a152_endStopTrusted "Right body controller: a152 end stop trusted";
CM_ SG_ 2011 VCRIGHT_a152_speedTableStatus "Right body controller: a152 speed table status";
CM_ SG_ 2011 VCRIGHT_a152_causedByBackoffs "Right body controller: a152 caused by backoffs";
CM_ SG_ 2011 VCRIGHT_a153_zeroed "Right body controller: a153 zeroed";
CM_ SG_ 2011 VCRIGHT_a153_endStopTrusted "Right body controller: a153 end stop trusted";
CM_ SG_ 2011 VCRIGHT_a153_speedTableStatus "Right body controller: a153 speed table status";
CM_ SG_ 2011 VCRIGHT_a153_causedByBackoffs "Right body controller: a153 caused by backoffs";
CM_ SG_ 2011 VCRIGHT_a154_windowThermalMode "Right body controller: a154 window thermal mode";
CM_ SG_ 2011 VCRIGHT_a154_lightShowActive "Right body controller: a154 light show active";
CM_ SG_ 2011 VCRIGHT_a155_windowThermalMode "Right body controller: a155 window thermal mode";
CM_ SG_ 2011 VCRIGHT_a155_lightShowActive "Right body controller: a155 light show active";
CM_ SG_ 2011 VCRIGHT_a177_hvacRearStall "Right body controller: a177 hvac rear stall";
CM_ SG_ 2011 VCRIGHT_a180_intButtonPressed "Right body controller: a180 int button pressed";
CM_ SG_ 2011 VCRIGHT_a180_extHandlePWM "Right body controller: a180 ext handle PWM";
CM_ SG_ 2011 VCRIGHT_a180_extHandlePulled "Right body controller: a180 ext handle pulled";
CM_ SG_ 2011 VCRIGHT_a180_releasePWM "Right body controller: a180 release PWM";
CM_ SG_ 2011 VCRIGHT_a180_latchStatus "Right body controller: a180 latch status";
CM_ SG_ 2011 VCRIGHT_a180_latchClawStatus "Right body controller: a180 latch claw status";
CM_ SG_ 2011 VCRIGHT_a181_intButtonPressed "Right body controller: a181 int button pressed";
CM_ SG_ 2011 VCRIGHT_a181_extHandlePWM "Right body controller: a181 ext handle PWM";
CM_ SG_ 2011 VCRIGHT_a181_extHandlePulled "Right body controller: a181 ext handle pulled";
CM_ SG_ 2011 VCRIGHT_a181_releasePWM "Right body controller: a181 release PWM";
CM_ SG_ 2011 VCRIGHT_a181_latchStatus "Right body controller: a181 latch status";
CM_ SG_ 2011 VCRIGHT_a181_latchClawStatus "Right body controller: a181 latch claw status";
CM_ SG_ 2011 VCRIGHT_a184_voltage "Right body controller: a184 voltage";
CM_ SG_ 2011 VCRIGHT_a184_temperature "Right body controller: a184 temperature";
CM_ SG_ 2011 VCRIGHT_a184_trunkCurrent "Right body controller: a184 trunk current";
CM_ SG_ 2011 VCRIGHT_a186_voltage "Right body controller: a186 voltage";
CM_ SG_ 2011 VCRIGHT_a186_temperature "Right body controller: a186 temperature";
CM_ SG_ 2011 VCRIGHT_a187_voltage "Right body controller: a187 voltage";
CM_ SG_ 2011 VCRIGHT_a187_temperature "Right body controller: a187 temperature";
CM_ SG_ 2011 VCRIGHT_a188_voltage "Right body controller: a188 voltage";
CM_ SG_ 2011 VCRIGHT_a188_temperature "Right body controller: a188 temperature";
CM_ SG_ 2011 VCRIGHT_a189_voltage "Right body controller: a189 voltage";
CM_ SG_ 2011 VCRIGHT_a189_temperature "Right body controller: a189 temperature";
CM_ SG_ 2011 VCRIGHT_a190_eFuseTripCount "Right body controller: a190 e fuse trip count";
CM_ SG_ 2011 VCRIGHT_a193_amplifierCurrent "Right body controller: a193 amplifier current";
CM_ SG_ 2011 VCRIGHT_a194_cntctrPwrCurrent "Right body controller: a194 cntctr pwr current";
CM_ SG_ 2011 VCRIGHT_a195_hvcCurrent "Right body controller: a195 hvc current";
CM_ SG_ 2011 VCRIGHT_a196_outputState "Right body controller: a196 output state";
CM_ SG_ 2011 VCRIGHT_a196_NVRAMState "Right body controller: a196 NVRAM state";
CM_ SG_ 2011 VCRIGHT_a196_lockoutState "Right body controller: a196 lockout state";
CM_ SG_ 2011 VCRIGHT_a197_outputState "Right body controller: a197 output state";
CM_ SG_ 2011 VCRIGHT_a197_NVRAMState "Right body controller: a197 NVRAM state";
CM_ SG_ 2011 VCRIGHT_a197_lockoutState "Right body controller: a197 lockout state";
CM_ SG_ 2011 VCRIGHT_a198_outputState "Right body controller: a198 output state";
CM_ SG_ 2011 VCRIGHT_a198_NVRAMState "Right body controller: a198 NVRAM state";
CM_ SG_ 2011 VCRIGHT_a198_lockoutState "Right body controller: a198 lockout state";
CM_ SG_ 2011 VCRIGHT_a199_outputState "Right body controller: a199 output state";
CM_ SG_ 2011 VCRIGHT_a199_NVRAMState "Right body controller: a199 NVRAM state";
CM_ SG_ 2011 VCRIGHT_a199_lockoutState "Right body controller: a199 lockout state";
CM_ SG_ 2011 VCRIGHT_a202_unknownAllowed "Right body controller: a202 unknown allowed";
CM_ SG_ 2011 VCRIGHT_a202_openAllowed "Right body controller: a202 open allowed";
CM_ SG_ 2011 VCRIGHT_a202_dynamicAllowed "Right body controller: a202 dynamic allowed";
CM_ SG_ 2011 VCRIGHT_a202_parkAllowed "Right body controller: a202 park allowed";
CM_ SG_ 2011 VCRIGHT_a202_startAllowed "Right body controller: a202 start allowed";
CM_ SG_ 2011 VCRIGHT_a202_serviceAllowed "Right body controller: a202 service allowed";
CM_ SG_ 2011 VCRIGHT_a202_winchAllowed "Right body controller: a202 winch allowed";
CM_ SG_ 2011 VCRIGHT_a202_winchReleaseAllowed "Right body controller: a202 winch release allowed";
CM_ SG_ 2011 VCRIGHT_a202_parkingAllowed "Right body controller: a202 parking allowed";
CM_ SG_ 2011 VCRIGHT_a202_dynApplyAllowed "Right body controller: a202 dyn apply allowed";
CM_ SG_ 2011 VCRIGHT_a202_releaseAllowed "Right body controller: a202 release allowed";
CM_ SG_ 2011 VCRIGHT_a202_parkPendingAllowed "Right body controller: a202 park pending allowed";
CM_ SG_ 2011 VCRIGHT_a202_wenchPendingAllowed "Right body controller: a202 wench pending allowed";
CM_ SG_ 2011 VCRIGHT_a202_desyncCount "Right body controller: a202 desync count";
CM_ SG_ 2011 VCRIGHT_a202_current "Right body controller: a202 current";
CM_ SG_ 2011 VCRIGHT_a202_epbConfig "Right body controller: a202 epb config";
CM_ SG_ 2011 VCRIGHT_a203_unknownAllowed "Right body controller: a203 unknown allowed";
CM_ SG_ 2011 VCRIGHT_a203_openAllowed "Right body controller: a203 open allowed";
CM_ SG_ 2011 VCRIGHT_a203_dynamicAllowed "Right body controller: a203 dynamic allowed";
CM_ SG_ 2011 VCRIGHT_a203_parkAllowed "Right body controller: a203 park allowed";
CM_ SG_ 2011 VCRIGHT_a203_startAllowed "Right body controller: a203 start allowed";
CM_ SG_ 2011 VCRIGHT_a203_serviceAllowed "Right body controller: a203 service allowed";
CM_ SG_ 2011 VCRIGHT_a203_winchAllowed "Right body controller: a203 winch allowed";
CM_ SG_ 2011 VCRIGHT_a203_winchReleaseAllowed "Right body controller: a203 winch release allowed";
CM_ SG_ 2011 VCRIGHT_a203_parkingAllowed "Right body controller: a203 parking allowed";
CM_ SG_ 2011 VCRIGHT_a203_dynApplyAllowed "Right body controller: a203 dyn apply allowed";
CM_ SG_ 2011 VCRIGHT_a203_releaseAllowed "Right body controller: a203 release allowed";
CM_ SG_ 2011 VCRIGHT_a203_parkPendingAllowed "Right body controller: a203 park pending allowed";
CM_ SG_ 2011 VCRIGHT_a203_wenchPendingAllowed "Right body controller: a203 wench pending allowed";
CM_ SG_ 2011 VCRIGHT_a203_desyncCount "Right body controller: a203 desync count";
CM_ SG_ 2011 VCRIGHT_a203_current "Right body controller: a203 current";
CM_ SG_ 2011 VCRIGHT_a203_epbConfig "Right body controller: a203 epb config";
CM_ SG_ 2011 VCRIGHT_a204_unknownAllowed "Right body controller: a204 unknown allowed";
CM_ SG_ 2011 VCRIGHT_a204_openAllowed "Right body controller: a204 open allowed";
CM_ SG_ 2011 VCRIGHT_a204_dynamicAllowed "Right body controller: a204 dynamic allowed";
CM_ SG_ 2011 VCRIGHT_a204_parkAllowed "Right body controller: a204 park allowed";
CM_ SG_ 2011 VCRIGHT_a204_startAllowed "Right body controller: a204 start allowed";
CM_ SG_ 2011 VCRIGHT_a204_serviceAllowed "Right body controller: a204 service allowed";
CM_ SG_ 2011 VCRIGHT_a204_winchAllowed "Right body controller: a204 winch allowed";
CM_ SG_ 2011 VCRIGHT_a204_winchReleaseAllowed "Right body controller: a204 winch release allowed";
CM_ SG_ 2011 VCRIGHT_a204_parkingAllowed "Right body controller: a204 parking allowed";
CM_ SG_ 2011 VCRIGHT_a204_dynApplyAllowed "Right body controller: a204 dyn apply allowed";
CM_ SG_ 2011 VCRIGHT_a204_releaseAllowed "Right body controller: a204 release allowed";
CM_ SG_ 2011 VCRIGHT_a204_parkPendingAllowed "Right body controller: a204 park pending allowed";
CM_ SG_ 2011 VCRIGHT_a204_wenchPendingAllowed "Right body controller: a204 wench pending allowed";
CM_ SG_ 2011 VCRIGHT_a204_desyncCount "Right body controller: a204 desync count";
CM_ SG_ 2011 VCRIGHT_a204_current "Right body controller: a204 current";
CM_ SG_ 2011 VCRIGHT_a204_epbConfig "Right body controller: a204 epb config";
CM_ SG_ 2011 VCRIGHT_a205_unknownAllowed "Right body controller: a205 unknown allowed";
CM_ SG_ 2011 VCRIGHT_a205_openAllowed "Right body controller: a205 open allowed";
CM_ SG_ 2011 VCRIGHT_a205_dynamicAllowed "Right body controller: a205 dynamic allowed";
CM_ SG_ 2011 VCRIGHT_a205_parkAllowed "Right body controller: a205 park allowed";
CM_ SG_ 2011 VCRIGHT_a205_startAllowed "Right body controller: a205 start allowed";
CM_ SG_ 2011 VCRIGHT_a205_serviceAllowed "Right body controller: a205 service allowed";
CM_ SG_ 2011 VCRIGHT_a205_winchAllowed "Right body controller: a205 winch allowed";
CM_ SG_ 2011 VCRIGHT_a205_winchReleaseAllowed "Right body controller: a205 winch release allowed";
CM_ SG_ 2011 VCRIGHT_a205_parkingAllowed "Right body controller: a205 parking allowed";
CM_ SG_ 2011 VCRIGHT_a205_dynApplyAllowed "Right body controller: a205 dyn apply allowed";
CM_ SG_ 2011 VCRIGHT_a205_releaseAllowed "Right body controller: a205 release allowed";
CM_ SG_ 2011 VCRIGHT_a205_parkPendingAllowed "Right body controller: a205 park pending allowed";
CM_ SG_ 2011 VCRIGHT_a205_wenchPendingAllowed "Right body controller: a205 wench pending allowed";
CM_ SG_ 2011 VCRIGHT_a205_desyncCount "Right body controller: a205 desync count";
CM_ SG_ 2011 VCRIGHT_a205_current "Right body controller: a205 current";
CM_ SG_ 2011 VCRIGHT_a205_epbConfig "Right body controller: a205 epb config";
CM_ SG_ 2011 VCRIGHT_a206_unknownAllowed "Right body controller: a206 unknown allowed";
CM_ SG_ 2011 VCRIGHT_a206_openAllowed "Right body controller: a206 open allowed";
CM_ SG_ 2011 VCRIGHT_a206_dynamicAllowed "Right body controller: a206 dynamic allowed";
CM_ SG_ 2011 VCRIGHT_a206_parkAllowed "Right body controller: a206 park allowed";
CM_ SG_ 2011 VCRIGHT_a206_startAllowed "Right body controller: a206 start allowed";
CM_ SG_ 2011 VCRIGHT_a206_serviceAllowed "Right body controller: a206 service allowed";
CM_ SG_ 2011 VCRIGHT_a206_winchAllowed "Right body controller: a206 winch allowed";
CM_ SG_ 2011 VCRIGHT_a206_winchReleaseAllowed "Right body controller: a206 winch release allowed";
CM_ SG_ 2011 VCRIGHT_a206_parkingAllowed "Right body controller: a206 parking allowed";
CM_ SG_ 2011 VCRIGHT_a206_dynApplyAllowed "Right body controller: a206 dyn apply allowed";
CM_ SG_ 2011 VCRIGHT_a206_releaseAllowed "Right body controller: a206 release allowed";
CM_ SG_ 2011 VCRIGHT_a206_parkPendingAllowed "Right body controller: a206 park pending allowed";
CM_ SG_ 2011 VCRIGHT_a206_wenchPendingAllowed "Right body controller: a206 wench pending allowed";
CM_ SG_ 2011 VCRIGHT_a206_unitStatusEPB "Right body controller: a206 unit status EPB";
CM_ SG_ 2011 VCRIGHT_a206_unitStatusEPBM "Right body controller: a206 unit status EPBM";
CM_ SG_ 2011 VCRIGHT_a207_unknownAllowed "Right body controller: a207 unknown allowed";
CM_ SG_ 2011 VCRIGHT_a207_openAllowed "Right body controller: a207 open allowed";
CM_ SG_ 2011 VCRIGHT_a207_dynamicAllowed "Right body controller: a207 dynamic allowed";
CM_ SG_ 2011 VCRIGHT_a207_parkAllowed "Right body controller: a207 park allowed";
CM_ SG_ 2011 VCRIGHT_a207_startAllowed "Right body controller: a207 start allowed";
CM_ SG_ 2011 VCRIGHT_a207_serviceAllowed "Right body controller: a207 service allowed";
CM_ SG_ 2011 VCRIGHT_a207_winchAllowed "Right body controller: a207 winch allowed";
CM_ SG_ 2011 VCRIGHT_a207_winchReleaseAllowed "Right body controller: a207 winch release allowed";
CM_ SG_ 2011 VCRIGHT_a207_parkingAllowed "Right body controller: a207 parking allowed";
CM_ SG_ 2011 VCRIGHT_a207_dynApplyAllowed "Right body controller: a207 dyn apply allowed";
CM_ SG_ 2011 VCRIGHT_a207_releaseAllowed "Right body controller: a207 release allowed";
BA_DEF_ BO_ "GenMsgCycleTime" INT 0 3600000;
BA_DEF_ BO_ "GenMsgSendType" ENUM "Cyclic","NotUsed","NotUsed","NotUsed","NotUsed","NotUsed","NotUsed","IfActive","NoMsgSendType","NotUsed";
BA_DEF_ BO_ "VFrameFormat" ENUM "StandardCAN","ExtendedCAN","reserved","J1939PG","reserved","reserved","reserved","reserved","reserved","reserved","reserved","reserved","reserved","reserved","StandardCAN_FD","ExtendedCAN_FD";
BA_DEF_ BO_ "CANFD_BRS" ENUM "0","1";
BA_DEF_ SG_ "SystemSignalLongSymbol" STRING;
BA_DEF_ SG_ "Confidence" ENUM "layout-only","plausible","validated";
BA_DEF_DEF_ "GenMsgCycleTime" 0;
BA_DEF_DEF_ "GenMsgSendType" "NoMsgSendType";
BA_DEF_DEF_ "VFrameFormat" "StandardCAN";
BA_DEF_DEF_ "CANFD_BRS" "1";
BA_DEF_DEF_ "SystemSignalLongSymbol" "";
BA_DEF_DEF_ "Confidence" "layout-only";
BA_ "Confidence" SG_ 738 VCLEFT_frontSeatHeatCurrent 1;
BA_ "Confidence" SG_ 738 VCLEFT_frontSeatHeatDuty 1;
BA_ "Confidence" SG_ 738 VCLEFT_frontSeatHeatTmp 1;
BA_ "Confidence" SG_ 738 VCLEFT_frontSeatHeatTmpTarget 1;
BA_ "Confidence" SG_ 738 VCLEFT_2RowSeatFoldLeftSwitch 1;
BA_ "Confidence" SG_ 738 VCLEFT_2RowSeatUnfoldLeftSwitch 1;
BA_ "Confidence" SG_ 738 VCLEFT_2RowSeatFoldRightSwitch 1;
BA_ "Confidence" SG_ 738 VCLEFT_2RowSeatUnfoldRightSwitch 1;
BA_ "Confidence" SG_ 738 VCLEFT_3RowSeatFoldLeftSwitch 1;
BA_ "Confidence" SG_ 738 VCLEFT_3RowSeatUnfoldLeftSwitch 1;
BA_ "Confidence" SG_ 738 VCLEFT_3RowSeatFoldRightSwitch 1;
BA_ "Confidence" SG_ 738 VCLEFT_3RowSeatUnfoldRightSwitch 1;
BA_ "Confidence" SG_ 738 VC_AH_1RowLeftSeatHeatVentHealth 1;
BA_ "Confidence" SG_ 738 VCLEFT_2RowSeatReclineState 1;
BA_ "Confidence" SG_ 738 VCLEFT_2RowSeatReclineDuty 1;
BA_ "Confidence" SG_ 738 VCLEFT_2RowSeatReclineCurrent 1;
BA_ "Confidence" SG_ 738 VCLEFT_2RowSeatReclineCalibrated 1;
BA_ "Confidence" SG_ 738 VCLEFT_2RowSeatReclinePositionRa 1;
BA_ "SystemSignalLongSymbol" SG_ 738 VCLEFT_2RowSeatReclinePositionRa "VCLEFT_2RowSeatReclinePositionRaw";
BA_ "Confidence" SG_ 738 VCLEFT_2RowSeatReclineAngle 1;
BA_ "Confidence" SG_ 738 VCLEFT_2RowSeatReclineAbsPosSwit 1;
BA_ "SystemSignalLongSymbol" SG_ 738 VCLEFT_2RowSeatReclineAbsPosSwit "VCLEFT_2RowSeatReclineAbsPosSwitchState";
BA_ "Confidence" SG_ 738 VCLEFT_2RowSeatReclinePositionSt 1;
BA_ "SystemSignalLongSymbol" SG_ 738 VCLEFT_2RowSeatReclinePositionSt "VCLEFT_2RowSeatReclinePositionState";
BA_ "Confidence" SG_ 738 VCLEFT_2RowSeatReclineAdjustment 1;
BA_ "SystemSignalLongSymbol" SG_ 738 VCLEFT_2RowSeatReclineAdjustment "VCLEFT_2RowSeatReclineAdjustmentAllowed";
BA_ "Confidence" SG_ 738 VCLEFT_2RowSeatReclineFoldAllowe 1;
BA_ "SystemSignalLongSymbol" SG_ 738 VCLEFT_2RowSeatReclineFoldAllowe "VCLEFT_2RowSeatReclineFoldAllowed";
BA_ "Confidence" SG_ 738 VCLEFT_2RowSeatReclineUnfoldAllo 1;
BA_ "SystemSignalLongSymbol" SG_ 738 VCLEFT_2RowSeatReclineUnfoldAllo "VCLEFT_2RowSeatReclineUnfoldAllowed";
BA_ "Confidence" SG_ 738 VCLEFT_2RowSeatReclineNextToggle 1;
BA_ "SystemSignalLongSymbol" SG_ 738 VCLEFT_2RowSeatReclineNextToggle "VCLEFT_2RowSeatReclineNextToggleDirection";
BA_ "SystemSignalLongSymbol" SG_ 738 VCLEFT_2RowSeatReclineChoreoBloc "VCLEFT_2RowSeatReclineChoreoBlockedByOccupancy";
BA_ "Confidence" SG_ 738 VCLEFT_2RowSeat1RClashAvoidanceB 1;
BA_ "SystemSignalLongSymbol" SG_ 738 VCLEFT_2RowSeat1RClashAvoidanceB "VCLEFT_2RowSeat1RClashAvoidanceBlockedReason";
BA_ "Confidence" SG_ 738 VCLEFT_2RowSeat1RClashAvoidanceS 1;
BA_ "SystemSignalLongSymbol" SG_ 738 VCLEFT_2RowSeat1RClashAvoidanceS "VCLEFT_2RowSeat1RClashAvoidanceState";
BA_ "Confidence" SG_ 738 VCLEFT_2RowSeatReclineAbsPo_0001 1;
BA_ "SystemSignalLongSymbol" SG_ 738 VCLEFT_2RowSeatReclineAbsPo_0001 "VCLEFT_2RowSeatReclineAbsPosSwitchTransPoint";
BA_ "Confidence" SG_ 738 VC_AH_2RowLeftSeatMovementHealth 1;
BA_ "Confidence" SG_ 738 VCLEFT_3RowSeatReclineState 1;
BA_ "Confidence" SG_ 738 VCLEFT_3RowSeatReclineDuty 1;
BA_ "Confidence" SG_ 738 VCLEFT_3RowSeatReclineCurrent 1;
BA_ "Confidence" SG_ 738 VCLEFT_3RowSeatReclineCalibrated 1;
BA_ "Confidence" SG_ 738 VCLEFT_3RowSeatReclinePositionRa 1;
BA_ "SystemSignalLongSymbol" SG_ 738 VCLEFT_3RowSeatReclinePositionRa "VCLEFT_3RowSeatReclinePositionRaw";
BA_ "Confidence" SG_ 738 VCLEFT_3RowSeatReclineAngle 1;
BA_ "Confidence" SG_ 738 VCLEFT_3RowSeatReclineNextToggle 1;
BA_ "SystemSignalLongSymbol" SG_ 738 VCLEFT_3RowSeatReclineNextToggle "VCLEFT_3RowSeatReclineNextToggleDirection";
BA_ "Confidence" SG_ 738 VCLEFT_3RRightCushionHeatCurrent 1;
BA_ "Confidence" SG_ 738 VCLEFT_3RRightCushionHeatDuty 1;
BA_ "Confidence" SG_ 738 VCLEFT_3RRightCushionHeatTmp 1;
BA_ "Confidence" SG_ 738 VCLEFT_3RRightCushionHeatTmpTarg 1;
BA_ "SystemSignalLongSymbol" SG_ 738 VCLEFT_3RRightCushionHeatTmpTarg "VCLEFT_3RRightCushionHeatTmpTarget";
BA_ "Confidence" SG_ 738 VCLEFT_3RRightCushionHeatInhibit 1;
BA_ "SystemSignalLongSymbol" SG_ 738 VCLEFT_3RRightCushionHeatInhibit "VCLEFT_3RRightCushionHeatInhibited";
BA_ "Confidence" SG_ 738 VCLEFT_3RowSeatReclinePositionSt 1;
BA_ "SystemSignalLongSymbol" SG_ 738 VCLEFT_3RowSeatReclinePositionSt "VCLEFT_3RowSeatReclinePositionState";
BA_ "Confidence" SG_ 738 VCLEFT_3RowSeatReclineAdjustment 1;
BA_ "SystemSignalLongSymbol" SG_ 738 VCLEFT_3RowSeatReclineAdjustment "VCLEFT_3RowSeatReclineAdjustmentAllowed";
BA_ "Confidence" SG_ 738 VCLEFT_3RowSeatReclineFoldAllowe 1;
BA_ "SystemSignalLongSymbol" SG_ 738 VCLEFT_3RowSeatReclineFoldAllowe "VCLEFT_3RowSeatReclineFoldAllowed";
BA_ "Confidence" SG_ 738 VCLEFT_3RowSeatReclineUnfoldAllo 1;
BA_ "SystemSignalLongSymbol" SG_ 738 VCLEFT_3RowSeatReclineUnfoldAllo "VCLEFT_3RowSeatReclineUnfoldAllowed";
BA_ "SystemSignalLongSymbol" SG_ 738 VCLEFT_3RowSeatReclineChoreoBloc "VCLEFT_3RowSeatReclineChoreoBlockedByOccupancy";
BA_ "Confidence" SG_ 738 VCLEFT_3RowSeatReclineAbsPosSwit 1;
BA_ "SystemSignalLongSymbol" SG_ 738 VCLEFT_3RowSeatReclineAbsPosSwit "VCLEFT_3RowSeatReclineAbsPosSwitchState";
BA_ "Confidence" SG_ 930 VCLEFT_securityControllerVoltage 1;
BA_ "Confidence" SG_ 930 VCLEFT_5AVoltage 1;
BA_ "Confidence" SG_ 930 VCLEFT_vbatProt 1;
BA_ "Confidence" SG_ 930 VCLEFT_footwellLightCurrent 1;
BA_ "Confidence" SG_ 930 VCLEFT_swcInputVoltage 1;
BA_ "Confidence" SG_ 930 VCLEFT_swcPCBATemperature 1;
BA_ "Confidence" SG_ 930 VCLEFT_rationalityAggregateCurre 1;
BA_ "SystemSignalLongSymbol" SG_ 930 VCLEFT_rationalityAggregateCurre "VCLEFT_rationalityAggregateCurrent";
BA_ "Confidence" SG_ 930 VCLEFT_LVBatteryTypeDBG 1;
BA_ "Confidence" SG_ 930 VCLEFT_eFuseMgmtVoltageMonitor 1;
BA_ "Confidence" SG_ 930 VCLEFT_trailerAuxCurrent 1;
BA_ "Confidence" SG_ 930 VCLEFT_swcHeatTmp 1;
BA_ "Confidence" SG_ 930 VCLEFT_swcHeatStatus 1;
BA_ "Confidence" SG_ 930 VCLEFT_swcHeatInhibited 1;
BA_ "Confidence" SG_ 930 VCLEFT_obdDeviceDetected 1;
BA_ "Confidence" SG_ 930 VCLEFT_pcbaTemperature 1;
BA_ "Confidence" SG_ 930 VCLEFT_swcHeatPwr 1;
BA_ "Confidence" SG_ 930 VCLEFT_swcHeatDutyCycle 1;
BA_ "Confidence" SG_ 930 VCLEFT_DIeFuseCurrent 1;
BA_ "Confidence" SG_ 930 VCLEFT_trailerBrakeControllerCur 1;
BA_ "SystemSignalLongSymbol" SG_ 930 VCLEFT_trailerBrakeControllerCur "VCLEFT_trailerBrakeControllerCurrent";
BA_ "Confidence" SG_ 930 VCLEFT_autonomyBehaviorStatus 1;
BA_ "Confidence" SG_ 930 VCLEFT_thirdRowLeftMapLightStatu 1;
BA_ "SystemSignalLongSymbol" SG_ 930 VCLEFT_thirdRowLeftMapLightStatu "VCLEFT_thirdRowLeftMapLightStatus";
BA_ "Confidence" SG_ 930 VCLEFT_thirdRowRightMapLightStat 1;
BA_ "SystemSignalLongSymbol" SG_ 930 VCLEFT_thirdRowRightMapLightStat "VCLEFT_thirdRowRightMapLightStatus";
BA_ "Confidence" SG_ 610 VCLEFT_steeringColumnSMState 1;
BA_ "Confidence" SG_ 610 VCLEFT_steeringColumnLastRequest 1;
BA_ "Confidence" SG_ 610 VCLEFT_steeringColumnUpDownDuty 1;
BA_ "Confidence" SG_ 610 VCLEFT_steeringColumnInOutDuty 1;
BA_ "Confidence" SG_ 610 VCLEFT_steeringColumnUpDownPos 1;
BA_ "Confidence" SG_ 610 VCLEFT_steeringColumnInOutPos 1;
BA_ "Confidence" SG_ 610 VCLEFT_steeringColumnUpDownAmps 1;
BA_ "Confidence" SG_ 610 VCLEFT_steeringColumnInOutAmps 1;
BA_ "Confidence" SG_ 610 VCLEFT_steeringColumnUpDownTC 1;
BA_ "Confidence" SG_ 610 VCLEFT_steeringColumnInOutTC 1;
BA_ "Confidence" SG_ 962 VCLEFT_brakeSwitchPressed 1;
BA_ "Confidence" SG_ 962 VCLEFT_rightMirrorTilt 1;
BA_ "Confidence" SG_ 962 VCLEFT_frontSeatTrackBack 1;
BA_ "Confidence" SG_ 962 VCLEFT_frontSeatTrackForward 1;
BA_ "Confidence" SG_ 962 VCLEFT_frontSeatTiltDown 1;
BA_ "Confidence" SG_ 962 VCLEFT_frontSeatTiltUp 1;
BA_ "Confidence" SG_ 962 VCLEFT_frontSeatLiftDown 1;
BA_ "Confidence" SG_ 962 VCLEFT_frontSeatLiftUp 1;
BA_ "Confidence" SG_ 962 VCLEFT_frontSeatBackrestBack 1;
BA_ "Confidence" SG_ 962 VCLEFT_frontSeatBackrestForward 1;
BA_ "Confidence" SG_ 962 VCLEFT_frontSeatLumbarDown 1;
BA_ "Confidence" SG_ 962 VCLEFT_frontSeatLumbarUp 1;
BA_ "Confidence" SG_ 962 VCLEFT_frontSeatLumbarIn 1;
BA_ "Confidence" SG_ 962 VCLEFT_frontSeatLumbarOut 1;
BA_ "Confidence" SG_ 962 VCLEFT_frontBuckleSwitch 1;
BA_ "Confidence" SG_ 962 VCLEFT_frontOccupancySwitch 1;
BA_ "Confidence" SG_ 962 VCLEFT_rearLeftBuckleSwitch 1;
BA_ "Confidence" SG_ 962 VCLEFT_rearCenterOccupancySwitch 1;
BA_ "Confidence" SG_ 962 VCLEFT_rearLeftOccupancySwitch 1;
BA_ "Confidence" SG_ 962 VCLEFT_rearRightOccupancySwitch 1;
BA_ "Confidence" SG_ 962 VCLEFT_brakePressed 1;
BA_ "Confidence" SG_ 962 VCLEFT_rearCenterBuckleSwitch 1;
BA_ "Confidence" SG_ 962 VCLEFT_isAlcoholInterlockSet 1;
BA_ "Confidence" SG_ 962 VCLEFT_swcLeftTiltRight 1;
BA_ "Confidence" SG_ 962 VCLEFT_swcLeftPressed 1;
BA_ "Confidence" SG_ 962 VCLEFT_swcRightTiltLeft 1;
BA_ "Confidence" SG_ 962 VCLEFT_swcRightTiltRight 1;
BA_ "Confidence" SG_ 962 VCLEFT_swcRightPressed 1;
BA_ "Confidence" SG_ 962 VCLEFT_swcLeftTiltLeft 1;
BA_ "Confidence" SG_ 962 VCLEFT_swcWiperButtonState 1;
BA_ "Confidence" SG_ 962 VCLEFT_swcRightScrollTicks 1;
BA_ "Confidence" SG_ 962 VCLEFT_swcTurnSignalLeftButtonSt 1;
BA_ "SystemSignalLongSymbol" SG_ 962 VCLEFT_swcTurnSignalLeftButtonSt "VCLEFT_swcTurnSignalLeftButtonState";
BA_ "Confidence" SG_ 962 VCLEFT_2RowSeatReclineSwitch 1;
BA_ "Confidence" SG_ 962 VCLEFT_2RowSeatCenterSwitch 1;
BA_ "Confidence" SG_ 962 VCLEFT_2RowSeatLeftFoldFlatSwitc 1;
BA_ "SystemSignalLongSymbol" SG_ 962 VCLEFT_2RowSeatLeftFoldFlatSwitc "VCLEFT_2RowSeatLeftFoldFlatSwitch";
BA_ "Confidence" SG_ 962 VCLEFT_2RowSeatRightFoldFlatSwit 1;
BA_ "SystemSignalLongSymbol" SG_ 962 VCLEFT_2RowSeatRightFoldFlatSwit "VCLEFT_2RowSeatRightFoldFlatSwitch";
BA_ "Confidence" SG_ 962 VCLEFT_2RowSeatBothFoldFlatSwitc 1;
BA_ "SystemSignalLongSymbol" SG_ 962 VCLEFT_2RowSeatBothFoldFlatSwitc "VCLEFT_2RowSeatBothFoldFlatSwitch";
BA_ "Confidence" SG_ 962 VCLEFT_2RowSeatBackrestFoldSwitc 1;
BA_ "SystemSignalLongSymbol" SG_ 962 VCLEFT_2RowSeatBackrestFoldSwitc "VCLEFT_2RowSeatBackrestFoldSwitch";
BA_ "Confidence" SG_ 962 VCLEFT_swcTurnSignalRightButtonS 1;
BA_ "SystemSignalLongSymbol" SG_ 962 VCLEFT_swcTurnSignalRightButtonS "VCLEFT_swcTurnSignalRightButtonState";
BA_ "Confidence" SG_ 962 VCLEFT_swcHighBeamButtonState 1;
BA_ "Confidence" SG_ 962 VCLEFT_swcVoiceControlPress 1;
BA_ "Confidence" SG_ 962 VCLEFT_swcCameraButtonState 1;
BA_ "Confidence" SG_ 962 VCLEFT_swcRightPressedQF 1;
BA_ "Confidence" SG_ 962 VCLEFT_2RowSeatReclineSwitchpack 1;
BA_ "SystemSignalLongSymbol" SG_ 962 VCLEFT_2RowSeatReclineSwitchpack "VCLEFT_2RowSeatReclineSwitchpackState";
BA_ "Confidence" SG_ 962 VCLEFT_3RowLeftBuckleSwitch 1;
BA_ "Confidence" SG_ 962 VCLEFT_frontSeatThighSupportExte 1;
BA_ "SystemSignalLongSymbol" SG_ 962 VCLEFT_frontSeatThighSupportExte "VCLEFT_frontSeatThighSupportExtendSwitch";
BA_ "Confidence" SG_ 962 VCLEFT_frontSeatThighSupportRetr 1;
BA_ "SystemSignalLongSymbol" SG_ 962 VCLEFT_frontSeatThighSupportRetr "VCLEFT_frontSeatThighSupportRetractSwitch";
BA_ "Confidence" SG_ 962 VCLEFT_frontSeatResistiveOccupan 1;
BA_ "SystemSignalLongSymbol" SG_ 962 VCLEFT_frontSeatResistiveOccupan "VCLEFT_frontSeatResistiveOccupancy";
BA_ "Confidence" SG_ 656 VCLEFT_hvac2RLeftLateralVoltage 1;
BA_ "Confidence" SG_ 656 VCLEFT_hvac2RLeftVerticalVoltage 1;
BA_ "Confidence" SG_ 656 VCLEFT_hvac2RRightLateralVoltage 1;
BA_ "Confidence" SG_ 656 VCLEFT_hvac2RRightVerticalVoltag 1;
BA_ "SystemSignalLongSymbol" SG_ 656 VCLEFT_hvac2RRightVerticalVoltag "VCLEFT_hvac2RRightVerticalVoltage";
BA_ "Confidence" SG_ 656 VCLEFT_hvac2RLeftLateralCalibrat 1;
BA_ "SystemSignalLongSymbol" SG_ 656 VCLEFT_hvac2RLeftLateralCalibrat "VCLEFT_hvac2RLeftLateralCalibrated";
BA_ "Confidence" SG_ 656 VCLEFT_hvac2RLeftVerticalCalibra 1;
BA_ "SystemSignalLongSymbol" SG_ 656 VCLEFT_hvac2RLeftVerticalCalibra "VCLEFT_hvac2RLeftVerticalCalibrated";
BA_ "Confidence" SG_ 656 VCLEFT_hvac2RRightLateralCalibra 1;
BA_ "SystemSignalLongSymbol" SG_ 656 VCLEFT_hvac2RRightLateralCalibra "VCLEFT_hvac2RRightLateralCalibrated";
BA_ "Confidence" SG_ 656 VCLEFT_hvac2RRightVerticalCalibr 1;
BA_ "SystemSignalLongSymbol" SG_ 656 VCLEFT_hvac2RRightVerticalCalibr "VCLEFT_hvac2RRightVerticalCalibrated";
BA_ "Confidence" SG_ 656 VCLEFT_hvac2RLeftLateralState 1;
BA_ "Confidence" SG_ 656 VCLEFT_hvac2RLeftVerticalState 1;
BA_ "Confidence" SG_ 656 VCLEFT_hvac2RRightLateralState 1;
BA_ "Confidence" SG_ 656 VCLEFT_hvac2RRightVerticalState 1;
BA_ "Confidence" SG_ 656 VCLEFT_hvacBlowerWindmillElecRpm 1;
BA_ "Confidence" SG_ 656 VCLEFT_hvac2RRightVerticalVeloci 1;
BA_ "SystemSignalLongSymbol" SG_ 656 VCLEFT_hvac2RRightVerticalVeloci "VCLEFT_hvac2RRightVerticalVelocity";
BA_ "Confidence" SG_ 656 VCLEFT_hvacBlowerWindmillBemf 1;
BA_ "Confidence" SG_ 656 VCLEFT_hvac2RLeftVerticalVelocit 1;
BA_ "SystemSignalLongSymbol" SG_ 656 VCLEFT_hvac2RLeftVerticalVelocit "VCLEFT_hvac2RLeftVerticalVelocity";
BA_ "Confidence" SG_ 656 VCLEFT_hvac2RLeftLateralVelocity 1;
BA_ "Confidence" SG_ 656 VCLEFT_vcusbLinSchedule 1;
BA_ "Confidence" SG_ 656 VCLEFT_hvacBlowerArbState 1;
BA_ "Confidence" SG_ 656 VCLEFT_hvacBlowerArbResult 1;
BA_ "Confidence" SG_ 656 VCLEFT_hvac2RLeftLateralDuty 1;
BA_ "Confidence" SG_ 656 VCLEFT_hvac2RLeftVerticalDuty 1;
BA_ "Confidence" SG_ 656 VCLEFT_hvac2RRightLateralDuty 1;
BA_ "Confidence" SG_ 656 VCLEFT_hvac2RRightVerticalDuty 1;
BA_ "Confidence" SG_ 656 VCLEFT_hvac2RRightLateralVelocit 1;
BA_ "SystemSignalLongSymbol" SG_ 656 VCLEFT_hvac2RRightLateralVelocit "VCLEFT_hvac2RRightLateralVelocity";
BA_ "SystemSignalLongSymbol" SG_ 656 VCLEFT_hvacBlower1msOverrunFrequ "VCLEFT_hvacBlower1msOverrunFrequency";
BA_ "SystemSignalLongSymbol" SG_ 656 VCLEFT_hvacBlower10msOverrunFreq "VCLEFT_hvacBlower10msOverrunFrequency";
BA_ "Confidence" SG_ 657 VCLEFT_hvac2RLeftLateralZeroStop 1;
BA_ "SystemSignalLongSymbol" SG_ 657 VCLEFT_hvac2RLeftLateralZeroStop "VCLEFT_hvac2RLeftLateralZeroStopVoltage";
BA_ "Confidence" SG_ 657 VCLEFT_hvac2RLeftVerticalZeroSto 1;
BA_ "SystemSignalLongSymbol" SG_ 657 VCLEFT_hvac2RLeftVerticalZeroSto "VCLEFT_hvac2RLeftVerticalZeroStopVoltage";
BA_ "Confidence" SG_ 657 VCLEFT_hvac2RRightLateralZeroSto 1;
BA_ "SystemSignalLongSymbol" SG_ 657 VCLEFT_hvac2RRightLateralZeroSto "VCLEFT_hvac2RRightLateralZeroStopVoltage";
BA_ "Confidence" SG_ 657 VCLEFT_hvac2RRightVerticalZeroSt 1;
BA_ "SystemSignalLongSymbol" SG_ 657 VCLEFT_hvac2RRightVerticalZeroSt "VCLEFT_hvac2RRightVerticalZeroStopVoltage";
BA_ "Confidence" SG_ 657 VCLEFT_hvac2RLeftLateralEndStopV 1;
BA_ "SystemSignalLongSymbol" SG_ 657 VCLEFT_hvac2RLeftLateralEndStopV "VCLEFT_hvac2RLeftLateralEndStopVoltage";
BA_ "Confidence" SG_ 657 VCLEFT_hvac2RLeftVerticalEndStop 1;
BA_ "SystemSignalLongSymbol" SG_ 657 VCLEFT_hvac2RLeftVerticalEndStop "VCLEFT_hvac2RLeftVerticalEndStopVoltage";
BA_ "Confidence" SG_ 657 VCLEFT_hvac2RRightLateralEndStop 1;
BA_ "SystemSignalLongSymbol" SG_ 657 VCLEFT_hvac2RRightLateralEndStop "VCLEFT_hvac2RRightLateralEndStopVoltage";
BA_ "Confidence" SG_ 657 VCLEFT_hvac2RRightVerticalEndSto 1;
BA_ "SystemSignalLongSymbol" SG_ 657 VCLEFT_hvac2RRightVerticalEndSto "VCLEFT_hvac2RRightVerticalEndStopVoltage";
BA_ "Confidence" SG_ 657 VCLEFT_hvacBlowerArbCurrent 1;
BA_ "Confidence" SG_ 657 VCLEFT_hvacBlowerTorqueIndexFilt 1;
BA_ "SystemSignalLongSymbol" SG_ 657 VCLEFT_hvacBlowerTorqueIndexFilt "VCLEFT_hvacBlowerTorqueIndexFiltered";
BA_ "Confidence" SG_ 386 VCLEFT_hvac2RLeftLateralPosition 1;
BA_ "Confidence" SG_ 386 VCLEFT_hvac2RLeftVerticalPositio 1;
BA_ "SystemSignalLongSymbol" SG_ 386 VCLEFT_hvac2RLeftVerticalPositio "VCLEFT_hvac2RLeftVerticalPosition";
BA_ "Confidence" SG_ 386 VCLEFT_hvac2RRightLateralPositio 1;
BA_ "SystemSignalLongSymbol" SG_ 386 VCLEFT_hvac2RRightLateralPositio "VCLEFT_hvac2RRightLateralPosition";
BA_ "Confidence" SG_ 386 VCLEFT_hvac2RRightVerticalPositi 1;
BA_ "SystemSignalLongSymbol" SG_ 386 VCLEFT_hvac2RRightVerticalPositi "VCLEFT_hvac2RRightVerticalPosition";
BA_ "Confidence" SG_ 706 VCLEFT_windowStateLF 1;
BA_ "Confidence" SG_ 706 VCLEFT_windowTrimClearMoveReques 1;
BA_ "SystemSignalLongSymbol" SG_ 706 VCLEFT_windowTrimClearMoveReques "VCLEFT_windowTrimClearMoveRequest";
BA_ "Confidence" SG_ 706 VCLEFT_windowDutyLF 1;
BA_ "Confidence" SG_ 706 VCLEFT_windowTrimClearActiveRequ 1;
BA_ "SystemSignalLongSymbol" SG_ 706 VCLEFT_windowTrimClearActiveRequ "VCLEFT_windowTrimClearActiveRequest";
BA_ "Confidence" SG_ 706 VCLEFT_windowCurrentLF 1;
BA_ "Confidence" SG_ 706 VCLEFT_windowPositionLF 1;
BA_ "Confidence" SG_ 706 VCLEFT_windowCalibratedLF 1;
BA_ "Confidence" SG_ 706 VCLEFT_windowStateLR 1;
BA_ "Confidence" SG_ 706 VCLEFT_windowDutyLR 1;
BA_ "Confidence" SG_ 706 VCLEFT_windowCurrentLR 1;
BA_ "Confidence" SG_ 706 VCLEFT_windowPositionLR 1;
BA_ "Confidence" SG_ 706 VCLEFT_windowCalibratedLR 1;
BA_ "Confidence" SG_ 706 VCLEFT_windowThermalTCLF 1;
BA_ "Confidence" SG_ 706 VCLEFT_windowThermalModeLF 1;
BA_ "Confidence" SG_ 706 VCLEFT_windowStopReasonLF 1;
BA_ "Confidence" SG_ 706 VCLEFT_windowStopReqReasonLF 1;
BA_ "Confidence" SG_ 706 VCLEFT_windowThermalTCLR 1;
BA_ "Confidence" SG_ 706 VCLEFT_windowThermalModeLR 1;
BA_ "Confidence" SG_ 706 VCLEFT_windowStopReasonLR 1;
BA_ "Confidence" SG_ 706 VCLEFT_windowStopReqReasonLR 1;
BA_ "Confidence" SG_ 706 VCLEFT_windowControlStateLF 1;
BA_ "Confidence" SG_ 706 VCLEFT_windowCtrlUnavailableLF 1;
BA_ "Confidence" SG_ 706 VCLEFT_windowControlStateLR 1;
BA_ "Confidence" SG_ 706 VCLEFT_windowCtrlUnavailableLR 1;
BA_ "Confidence" SG_ 706 VCLEFT_windowPositionStateLF 1;
BA_ "Confidence" SG_ 706 VCLEFT_windowPositionStateLR 1;
BA_ "Confidence" SG_ 706 VCLEFT_windowVehGearStateLF 1;
BA_ "Confidence" SG_ 706 VCLEFT_windowVehGearStateLR 1;
BA_ "Confidence" SG_ 706 VCLEFT_windowSpeedTableStatusLF 1;
BA_ "Confidence" SG_ 706 VCLEFT_windowSpeedTableStatusLR 1;
BA_ "SystemSignalLongSymbol" SG_ 1114 VCRIGHT_AP_hvacFlashFoggingDetec "VCRIGHT_AP_hvacFlashFoggingDetected";
BA_ "Confidence" SG_ 1114 VCRIGHT_AP_hvacModelInitStatus 1;
BA_ "Confidence" SG_ 1114 VCRIGHT_AP_cabinTempWindshield 1;
BA_ "Confidence" SG_ 1114 VCRIGHT_AP_cabinTempSideGlassRig 1;
BA_ "SystemSignalLongSymbol" SG_ 1114 VCRIGHT_AP_cabinTempSideGlassRig "VCRIGHT_AP_cabinTempSideGlassRight";
BA_ "Confidence" SG_ 1114 VCRIGHT_AP_cabinTempSideGlassLef 1;
BA_ "SystemSignalLongSymbol" SG_ 1114 VCRIGHT_AP_cabinTempSideGlassLef "VCRIGHT_AP_cabinTempSideGlassLeft";
BA_ "Confidence" SG_ 1114 VCRIGHT_AP_hvacRecircDoorPercent 1;
BA_ "Confidence" SG_ 1114 VCRIGHT_AP_hvacAirDistributionMo 1;
BA_ "SystemSignalLongSymbol" SG_ 1114 VCRIGHT_AP_hvacAirDistributionMo "VCRIGHT_AP_hvacAirDistributionMode";
BA_ "Confidence" SG_ 1114 VCRIGHT_AP_hvacEstimateWindshiel 1;
BA_ "SystemSignalLongSymbol" SG_ 1114 VCRIGHT_AP_hvacEstimateWindshiel "VCRIGHT_AP_hvacEstimateWindshieldRH";
BA_ "Confidence" SG_ 1114 VCRIGHT_AP_hvacMassflowTarget 1;
BA_ "Confidence" SG_ 1114 VCRIGHT_AP_tempDuctDefrost 1;
BA_ "Confidence" SG_ 1114 VCRIGHT_AP_cameraTurnOnTime 1;
BA_ "Confidence" SG_ 1114 VCRIGHT_AP_cameraDefogType 1;
BA_ "Confidence" SG_ 1114 VCRIGHT_ah_hvacFaultSurvivabilit 1;
BA_ "SystemSignalLongSymbol" SG_ 1114 VCRIGHT_ah_hvacFaultSurvivabilit "VCRIGHT_ah_hvacFaultSurvivabilityTime";
BA_ "Confidence" SG_ 1114 VCRIGHT_ah_defoggingTimeNeeded 1;
BA_ "Confidence" SG_ 1114 VCRIGHT_AP_cameraFanDutyRequest 1;
BA_ "Confidence" SG_ 1114 VCRIGHT_ah_defogSystemState 1;
BA_ "Confidence" SG_ 1114 VCRIGHT_AP_turnForwardCameraHeat 1;
BA_ "SystemSignalLongSymbol" SG_ 1114 VCRIGHT_AP_turnForwardCameraHeat "VCRIGHT_AP_turnForwardCameraHeaterOnReason";
BA_ "Confidence" SG_ 1114 VCRIGHT_AP_turnCameraFanOffReaso 1;
BA_ "SystemSignalLongSymbol" SG_ 1114 VCRIGHT_AP_turnCameraFanOffReaso "VCRIGHT_AP_turnCameraFanOffReason";
BA_ "Confidence" SG_ 1114 VCRIGHT_AP_forwardCameraIntegrat 1;
BA_ "SystemSignalLongSymbol" SG_ 1114 VCRIGHT_AP_forwardCameraIntegrat "VCRIGHT_AP_forwardCameraIntegratedHeaterRequest";
BA_ "Confidence" SG_ 1114 VCRIGHT_AP_solarFluxOnRightWindo 1;
BA_ "SystemSignalLongSymbol" SG_ 1114 VCRIGHT_AP_solarFluxOnRightWindo "VCRIGHT_AP_solarFluxOnRightWindow";
BA_ "Confidence" SG_ 1114 VCRIGHT_AP_solarFluxOnLeftWindow 1;
BA_ "Confidence" SG_ 1124 VCRIGHT_AP_tempCameraModele_0001 1;
BA_ "SystemSignalLongSymbol" SG_ 1124 VCRIGHT_AP_tempCameraModele_0001 "VCRIGHT_AP_tempCameraModeledWindshieldOut";
BA_ "Confidence" SG_ 1124 VCRIGHT_AP_tempCameraModeledWind 1;
BA_ "SystemSignalLongSymbol" SG_ 1124 VCRIGHT_AP_tempCameraModeledWind "VCRIGHT_AP_tempCameraModeledWindshieldIn";
BA_ "Confidence" SG_ 1124 VCRIGHT_AP_cameraModeledWin_0001 1;
BA_ "SystemSignalLongSymbol" SG_ 1124 VCRIGHT_AP_cameraModeledWin_0001 "VCRIGHT_AP_cameraModeledWindshieldOutRh";
BA_ "Confidence" SG_ 1124 VCRIGHT_AP_cameraModeledWindshie 1;
BA_ "SystemSignalLongSymbol" SG_ 1124 VCRIGHT_AP_cameraModeledWindshie "VCRIGHT_AP_cameraModeledWindshieldInRh";
BA_ "Confidence" SG_ 1124 VCRIGHT_AP_maxAchievableASideTem 1;
BA_ "SystemSignalLongSymbol" SG_ 1124 VCRIGHT_AP_maxAchievableASideTem "VCRIGHT_AP_maxAchievableASideTempCameraPocket";
BA_ "Confidence" SG_ 1124 VCRIGHT_AP_cameraModeledPocketWa 1;
BA_ "SystemSignalLongSymbol" SG_ 1124 VCRIGHT_AP_cameraModeledPocketWa "VCRIGHT_AP_cameraModeledPocketWaterMass";
BA_ "Confidence" SG_ 1124 VCRIGHT_AP_humidityModelInitStat 1;
BA_ "SystemSignalLongSymbol" SG_ 1124 VCRIGHT_AP_humidityModelInitStat "VCRIGHT_AP_humidityModelInitStatus";
BA_ "Confidence" SG_ 1124 VCRIGHT_AP_humidityModelStatus 1;
BA_ "Confidence" SG_ 549 VCRIGHT_ptcLVState 1;
BA_ "Confidence" SG_ 549 VCRIGHT_ocsLVState 1;
BA_ "Confidence" SG_ 549 VCRIGHT_premAudioLVState 1;
BA_ "Confidence" SG_ 549 VCRIGHT_rearOilPumpLVState 1;
BA_ "Confidence" SG_ 549 VCRIGHT_tunerLVState 1;
BA_ "Confidence" SG_ 549 VCRIGHT_hvcLVState 1;
BA_ "Confidence" SG_ 549 VCRIGHT_rcmLVState 1;
BA_ "Confidence" SG_ 549 VCRIGHT_lumbarLVState 1;
BA_ "Confidence" SG_ 549 VCRIGHT_3RUSBPowered 1;
BA_ "Confidence" SG_ 549 VCRIGHT_eFuseLockoutStatus 1;
BA_ "Confidence" SG_ 549 VCRIGHT_swEnStatus 1;
BA_ "Confidence" SG_ 549 VCRIGHT_vehiclePowerStateDBG 1;
BA_ "Confidence" SG_ 549 VCRIGHT_parkLVState 1;
BA_ "Confidence" SG_ 549 VCRIGHT_icrLVState 1;
BA_ "Confidence" SG_ 549 VCRIGHT_interiorCameraLedLVState 1;
BA_ "Confidence" SG_ 549 VCRIGHT_diLVState 1;
BA_ "Confidence" SG_ 549 VCRIGHT_accDevicesDetected 1;
BA_ "Confidence" SG_ 643 VCRIGHT_PTCLeftTargetPowerHV 1;
BA_ "Confidence" SG_ 643 VCRIGHT_PTCRightTargetPowerHV 1;
BA_ "Confidence" SG_ 643 VCRIGHT_PTCLeftTargetDuty 1;
BA_ "Confidence" SG_ 643 VCRIGHT_PTCRightTargetDuty 1;
BA_ "Confidence" SG_ 643 VCRIGHT_PTCRequestMode 1;
BA_ "SystemSignalLongSymbol" SG_ 2011 VCRIGHT_a010_UnderVoltageDetecte "VCRIGHT_a010_UnderVoltageDetected";
BA_ "SystemSignalLongSymbol" SG_ 2011 VCRIGHT_a082_RIPC_epbPrivateStat "VCRIGHT_a082_RIPC_epbPrivateState";
BA_ "SystemSignalLongSymbol" SG_ 2011 VCRIGHT_a083_LIPC_epbPrivateStat "VCRIGHT_a083_LIPC_epbPrivateState";
BA_ "SystemSignalLongSymbol" SG_ 2011 VCRIGHT_a086_VEH_LVBMS_statusHig "VCRIGHT_a086_VEH_LVBMS_statusHigh";
BA_ "SystemSignalLongSymbol" SG_ 2011 VCRIGHT_a086_VEH_12VBatteryStatu "VCRIGHT_a086_VEH_12VBatteryStatus";
BA_ "SystemSignalLongSymbol" SG_ 2011 VCRIGHT_a086_BDY_12VBatteryStatu "VCRIGHT_a086_BDY_12VBatteryStatus";
BA_ "SystemSignalLongSymbol" SG_ 2011 VCRIGHT_a087_PARTY_thermalContro "VCRIGHT_a087_PARTY_thermalControl";
BA_ "SystemSignalLongSymbol" SG_ 2011 VCRIGHT_a088_PARTY_thermalContro "VCRIGHT_a088_PARTY_thermalControl";
BA_ "SystemSignalLongSymbol" SG_ 2011 VCRIGHT_a098_PARTY_thermalContro "VCRIGHT_a098_PARTY_thermalControl";
BA_ "SystemSignalLongSymbol" SG_ 2011 VCRIGHT_a101_LIPC_externalWatchd "VCRIGHT_a101_LIPC_externalWatchdogHeartBeat";
BA_ "SystemSignalLongSymbol" SG_ 2011 VCRIGHT_a108_PARTY_thermalContro "VCRIGHT_a108_PARTY_thermalControl";
BA_ "SystemSignalLongSymbol" SG_ 2011 VCRIGHT_a110_VEH_canLogAvailabil "VCRIGHT_a110_VEH_canLogAvailability";
BA_ "SystemSignalLongSymbol" SG_ 2011 VCRIGHT_a110_CH_airbagCutoffStat "VCRIGHT_a110_CH_airbagCutoffStatus";
BA_ "SystemSignalLongSymbol" SG_ 2011 VCRIGHT_a111_RIPC_epbPrivateStat "VCRIGHT_a111_RIPC_epbPrivateState";
BA_ "SystemSignalLongSymbol" SG_ 2011 VCRIGHT_a112_LIPC_epbPrivateStat "VCRIGHT_a112_LIPC_epbPrivateState";
BA_ "SystemSignalLongSymbol" SG_ 2011 VCRIGHT_a115_UI_corianderVehicle "VCRIGHT_a115_UI_corianderVehicleControl";
BA_ "SystemSignalLongSymbol" SG_ 2011 VCRIGHT_a115_VEH_authenticationW "VCRIGHT_a115_VEH_authenticationWithMac";
BA_ "SystemSignalLongSymbol" SG_ 2011 VCRIGHT_a115_BDY_authenticationW "VCRIGHT_a115_BDY_authenticationWithMac";
BA_ "SystemSignalLongSymbol" SG_ 2011 VCRIGHT_a116_PARTY_restraintStat "VCRIGHT_a116_PARTY_restraintStatus";
BA_ "SystemSignalLongSymbol" SG_ 2011 VCRIGHT_a117_BDY_falconSwitchSta "VCRIGHT_a117_BDY_falconSwitchStatus";
BA_ "SystemSignalLongSymbol" SG_ 2011 VCRIGHT_a117_VEH_intrusionSensor "VCRIGHT_a117_VEH_intrusionSensorStatus";
BA_ "SystemSignalLongSymbol" SG_ 2011 VCRIGHT_a117_PARTY_restraintStat "VCRIGHT_a117_PARTY_restraintStatus";
BA_ "SystemSignalLongSymbol" SG_ 2011 VCRIGHT_a117_PARTY_lightingSecon "VCRIGHT_a117_PARTY_lightingSecondary";
BA_ "SystemSignalLongSymbol" SG_ 2011 VCRIGHT_a117_BDY_lightingSeconda "VCRIGHT_a117_BDY_lightingSecondary";
BA_ "SystemSignalLongSymbol" SG_ 2011 VCRIGHT_a117_VEH_liftgateLeaderR "VCRIGHT_a117_VEH_liftgateLeaderRequest";
BA_ "SystemSignalLongSymbol" SG_ 2011 VCRIGHT_a118_VEH_12VBatteryStatu "VCRIGHT_a118_VEH_12VBatteryStatus";
BA_ "SystemSignalLongSymbol" SG_ 2011 VCRIGHT_a118_PARTY_outputPowerSt "VCRIGHT_a118_PARTY_outputPowerStatus";
BA_ "SystemSignalLongSymbol" SG_ 2011 VCRIGHT_a118_VEH_interNodeResist "VCRIGHT_a118_VEH_interNodeResistance";
BA_ "SystemSignalLongSymbol" SG_ 2011 VCRIGHT_a118_BDY_outputPowerStat "VCRIGHT_a118_BDY_outputPowerStatus";
BA_ "SystemSignalLongSymbol" SG_ 2011 VCRIGHT_a118_PARTY_AP_vehicleSta "VCRIGHT_a118_PARTY_AP_vehicleState1HzMuxed";
BA_ "SystemSignalLongSymbol" SG_ 2011 VCRIGHT_a118_BDY_AP_vehicleState "VCRIGHT_a118_BDY_AP_vehicleState1HzMuxed";
BA_ "SystemSignalLongSymbol" SG_ 2011 VCRIGHT_a118_PARTY_VCFRONT_camer "VCRIGHT_a118_PARTY_VCFRONT_cameraCleaningStatus";
BA_ "SystemSignalLongSymbol" SG_ 2011 VCRIGHT_a120_PARTY_vehicleEstima "VCRIGHT_a120_PARTY_vehicleEstimates";
BA_ "SystemSignalLongSymbol" SG_ 2011 VCRIGHT_a120_VEH_aggregatedAxleS "VCRIGHT_a120_VEH_aggregatedAxleSpeed";
BA_ "SystemSignalLongSymbol" SG_ 2011 VCRIGHT_a120_PARTY_aggregatedAxl "VCRIGHT_a120_PARTY_aggregatedAxleSpeed";
BA_ "SystemSignalLongSymbol" SG_ 2011 VCRIGHT_a120_PARTY_autonomyHealt "VCRIGHT_a120_PARTY_autonomyHealth";
BA_ "SystemSignalLongSymbol" SG_ 2011 VCRIGHT_a120_PARTY_stalklessInte "VCRIGHT_a120_PARTY_stalklessInterfaces";
BA_ "SystemSignalLongSymbol" SG_ 2011 VCRIGHT_a120_VEH_estimatedBrakeT "VCRIGHT_a120_VEH_estimatedBrakeTemp";
BA_ "SystemSignalLongSymbol" SG_ 2011 VCRIGHT_a120_VEH_vehicleEstimate "VCRIGHT_a120_VEH_vehicleEstimates";
VAL_ 738 VCLEFT_2RowSeatFoldLeftSwitch 3 "SWITCH_FAULT" 2 "SWITCH_ON" 1 "SWITCH_OFF" 0 "SWITCH_SNA" ;
VAL_ 738 VCLEFT_2RowSeatUnfoldLeftSwitch 3 "SWITCH_FAULT" 2 "SWITCH_ON" 1 "SWITCH_OFF" 0 "SWITCH_SNA" ;
VAL_ 738 VCLEFT_2RowSeatFoldRightSwitch 3 "SWITCH_FAULT" 2 "SWITCH_ON" 1 "SWITCH_OFF" 0 "SWITCH_SNA" ;
VAL_ 738 VCLEFT_2RowSeatUnfoldRightSwitch 3 "SWITCH_FAULT" 2 "SWITCH_ON" 1 "SWITCH_OFF" 0 "SWITCH_SNA" ;
VAL_ 738 VCLEFT_3RowSeatFoldLeftSwitch 3 "SWITCH_FAULT" 2 "SWITCH_ON" 1 "SWITCH_OFF" 0 "SWITCH_SNA" ;
VAL_ 738 VCLEFT_3RowSeatUnfoldLeftSwitch 3 "SWITCH_FAULT" 2 "SWITCH_ON" 1 "SWITCH_OFF" 0 "SWITCH_SNA" ;
VAL_ 738 VCLEFT_3RowSeatFoldRightSwitch 3 "SWITCH_FAULT" 2 "SWITCH_ON" 1 "SWITCH_OFF" 0 "SWITCH_SNA" ;
VAL_ 738 VCLEFT_3RowSeatUnfoldRightSwitch 3 "SWITCH_FAULT" 2 "SWITCH_ON" 1 "SWITCH_OFF" 0 "SWITCH_SNA" ;
VAL_ 738 VC_AH_1RowLeftSeatHeatVentHealth 2 "SEAT_HEAT_VENT_UNAVAILABLE" 1 "SEAT_HEAT_VENT_HEALTHY" 0 "SEAT_HEAT_VENT_HEALTH_UNKNOWN" ;
VAL_ 738 VCLEFT_2RowSeatReclineState 15 "SEAT_ADJUSTABLE_FOLD_FLAT_STATE_SNA" 12 "SEAT_ADJUSTABLE_FOLD_FLAT_STATE_CALIBRATING_ABSOLUTE_SENSOR" 11 "SEAT_ADJUSTABLE_FOLD_FLAT_STATE_CALIBRATING_ZERO_POSITION" 10 "SEAT_ADJUSTABLE_FOLD_FLAT_STATE_WAITING_TO_CLEAR_FOR_UNFOLD" 9 "SEAT_ADJUSTABLE_FOLD_FLAT_STATE_WAITING_TO_CLEAR_FOR_FOLD" 8 "SEAT_ADJUSTABLE_FOLD_FLAT_STATE_MOVING_REARWARD_TO_POSITION" 7 "SEAT_ADJUSTABLE_FOLD_FLAT_STATE_MOVING_FORWARD_TO_POSITION" 6 "SEAT_ADJUSTABLE_FOLD_FLAT_STATE_UNFOLDING" 5 "SEAT_ADJUSTABLE_FOLD_FLAT_STATE_FOLDING" 4 "SEAT_ADJUSTABLE_FOLD_FLAT_STATE_ADJUSTING_REARWARD_FAST" 3 "SEAT_ADJUSTABLE_FOLD_FLAT_STATE_ADJUSTING_FORWARD_FAST" 2 "SEAT_ADJUSTABLE_FOLD_FLAT_STATE_ADJUSTING_REARWARD_COMFORT" 1 "SEAT_ADJUSTABLE_FOLD_FLAT_STATE_ADJUSTING_FORWARD_COMFORT" 0 "SEAT_ADJUSTABLE_FOLD_FLAT_STATE_STOPPED" ;
VAL_ 738 VCLEFT_2RowSeatReclineAbsPosSwit 3 "SWITCH_FAULT" 2 "SWITCH_ON" 1 "SWITCH_OFF" 0 "SWITCH_SNA" ;
VAL_ 738 VCLEFT_2RowSeatReclinePositionSt 4 "SEAT_ADJUSTABLE_FOLD_FLAT_POSITION_STATE_SNA" 3 "SEAT_ADJUSTABLE_FOLD_FLAT_POSITION_STATE_UNKNOWN" 2 "SEAT_ADJUSTABLE_FOLD_FLAT_POSITION_STATE_UNSAFE_INTERMEDIATE" 1 "SEAT_ADJUSTABLE_FOLD_FLAT_POSITION_STATE_UNFOLDED" 0 "SEAT_ADJUSTABLE_FOLD_FLAT_POSITION_STATE_FOLDED" ;
VAL_ 738 VCLEFT_2RowSeatReclineNextToggle 2 "SEAT_ADJUSTABLE_FOLD_FLAT_NEXT_TOGGLE_DIRECTION_SNA" 1 "SEAT_ADJUSTABLE_FOLD_FLAT_NEXT_TOGGLE_DIRECTION_UNFOLD" 0 "SEAT_ADJUSTABLE_FOLD_FLAT_NEXT_TOGGLE_DIRECTION_FOLD" ;
VAL_ 738 VCLEFT_2RowSeat1RClashAvoidanceB 6 "SEAT_FOLD_FLAT_CLASH_AVOIDANCE_REASON_FRONT_SEAT_OCCUPANCY" 5 "SEAT_FOLD_FLAT_CLASH_AVOIDANCE_REASON_FRONT_SEAT_MOVING" 4 "SEAT_FOLD_FLAT_CLASH_AVOIDANCE_REASON_FRONT_SEAT_PROFILE_RECALL" 3 "SEAT_FOLD_FLAT_CLASH_AVOIDANCE_REASON_REAR_SEAT_UNCALIBRATED" 2 "SEAT_FOLD_FLAT_CLASH_AVOIDANCE_REASON_FRONT_SEAT_UNCALIBRATED" 1 "SEAT_FOLD_FLAT_CLASH_AVOIDANCE_REASON_VEHICLE_IN_MOTION" 0 "SEAT_FOLD_FLAT_CLASH_AVOIDANCE_REASON_NONE" ;
VAL_ 738 VCLEFT_2RowSeat1RClashAvoidanceS 3 "SEAT_FOLD_FLAT_CLASH_AVOIDANCE_STATE_RESTORING_FRONT_SEAT" 2 "SEAT_FOLD_FLAT_CLASH_AVOIDANCE_STATE_WAITING_TO_RESTORE_FRONT_SEAT" 1 "SEAT_FOLD_FLAT_CLASH_AVOIDANCE_STATE_FRONT_SEAT_CLEARING" 0 "SEAT_FOLD_FLAT_CLASH_AVOIDANCE_STATE_IDLE" ;
VAL_ 738 VC_AH_2RowLeftSeatMovementHealth 4 "SEAT_CALIBRATION_REQUIRED" 3 "SEAT_IN_NON_USE_POSITION" 2 "SEAT_CANNOT_MOVE" 1 "SEAT_MOVEMENT_HEALTHY" 0 "SEAT_MOVEMENT_HEALTH_UNKNOWN" ;
VAL_ 738 VCLEFT_3RowSeatReclineState 15 "SEAT_ADJUSTABLE_FOLD_FLAT_STATE_SNA" 12 "SEAT_ADJUSTABLE_FOLD_FLAT_STATE_CALIBRATING_ABSOLUTE_SENSOR" 11 "SEAT_ADJUSTABLE_FOLD_FLAT_STATE_CALIBRATING_ZERO_POSITION" 10 "SEAT_ADJUSTABLE_FOLD_FLAT_STATE_WAITING_TO_CLEAR_FOR_UNFOLD" 9 "SEAT_ADJUSTABLE_FOLD_FLAT_STATE_WAITING_TO_CLEAR_FOR_FOLD" 8 "SEAT_ADJUSTABLE_FOLD_FLAT_STATE_MOVING_REARWARD_TO_POSITION" 7 "SEAT_ADJUSTABLE_FOLD_FLAT_STATE_MOVING_FORWARD_TO_POSITION" 6 "SEAT_ADJUSTABLE_FOLD_FLAT_STATE_UNFOLDING" 5 "SEAT_ADJUSTABLE_FOLD_FLAT_STATE_FOLDING" 4 "SEAT_ADJUSTABLE_FOLD_FLAT_STATE_ADJUSTING_REARWARD_FAST" 3 "SEAT_ADJUSTABLE_FOLD_FLAT_STATE_ADJUSTING_FORWARD_FAST" 2 "SEAT_ADJUSTABLE_FOLD_FLAT_STATE_ADJUSTING_REARWARD_COMFORT" 1 "SEAT_ADJUSTABLE_FOLD_FLAT_STATE_ADJUSTING_FORWARD_COMFORT" 0 "SEAT_ADJUSTABLE_FOLD_FLAT_STATE_STOPPED" ;
VAL_ 738 VCLEFT_3RowSeatReclineNextToggle 2 "SEAT_ADJUSTABLE_FOLD_FLAT_NEXT_TOGGLE_DIRECTION_SNA" 1 "SEAT_ADJUSTABLE_FOLD_FLAT_NEXT_TOGGLE_DIRECTION_UNFOLD" 0 "SEAT_ADJUSTABLE_FOLD_FLAT_NEXT_TOGGLE_DIRECTION_FOLD" ;
VAL_ 738 VCLEFT_3RowSeatReclinePositionSt 4 "SEAT_ADJUSTABLE_FOLD_FLAT_POSITION_STATE_SNA" 3 "SEAT_ADJUSTABLE_FOLD_FLAT_POSITION_STATE_UNKNOWN" 2 "SEAT_ADJUSTABLE_FOLD_FLAT_POSITION_STATE_UNSAFE_INTERMEDIATE" 1 "SEAT_ADJUSTABLE_FOLD_FLAT_POSITION_STATE_UNFOLDED" 0 "SEAT_ADJUSTABLE_FOLD_FLAT_POSITION_STATE_FOLDED" ;
VAL_ 738 VCLEFT_3RowSeatReclineAbsPosSwit 3 "SWITCH_FAULT" 2 "SWITCH_ON" 1 "SWITCH_OFF" 0 "SWITCH_SNA" ;
VAL_ 930 VCLEFT_LVBatteryTypeDBG 5 "LV_BATTERY_TYPE_TESLA_48V_LI_ION" 4 "LV_BATTERY_TYPE_TESLA_16V_LI_ION" 3 "LV_BATTERY_TYPE_CATL_LI_ION" 2 "LV_BATTERY_TYPE_CLARIOS_B24_FLOODED" 1 "LV_BATTERY_TYPE_ATLASBX_B24_FLOODED" 0 "LV_BATTERY_TYPE_UNKNOWN" ;
VAL_ 930 VCLEFT_swcHeatStatus 4 "HEATER_STATE_FAULT" 3 "HEATER_STATE_OFF_UNAVAILABLE" 2 "HEATER_STATE_OFF" 1 "HEATER_STATE_ON" 0 "HEATER_STATE_SNA" ;
VAL_ 930 VCLEFT_autonomyBehaviorStatus 2 "DRIVERLESS_NO_TAKEOVER" 1 "DRIVERLESS_TAKEOVER" 0 "DRIVER" ;
VAL_ 930 VCLEFT_thirdRowLeftMapLightStatu 3 "LIGHT_SNA" 2 "LIGHT_FAULT" 1 "LIGHT_ON" 0 "LIGHT_OFF" ;
VAL_ 930 VCLEFT_thirdRowRightMapLightStat 3 "LIGHT_SNA" 2 "LIGHT_FAULT" 1 "LIGHT_ON" 0 "LIGHT_OFF" ;
VAL_ 610 VCLEFT_steeringColumnSMState 3 "STEERING_COLUMN_STATE_MANUAL_CONTROL" 2 "STEERING_COLUMN_STATE_CALIBRATE" 1 "STEERING_COLUMN_STATE_RECALL" 0 "STEERING_COLUMN_STATE_SNA" ;
VAL_ 610 VCLEFT_steeringColumnLastRequest 5 "STEERING_COLUMN_REQUEST_OUT" 4 "STEERING_COLUMN_REQUEST_IN" 3 "STEERING_COLUMN_REQUEST_DOWN" 2 "STEERING_COLUMN_REQUEST_UP" 1 "STEERING_COLUMN_REQUEST_NONE" 0 "STEERING_COLUMN_REQUEST_SNA" ;
VAL_ 962 VCLEFT_rightMirrorTilt 4 "MIRROR_TILT_LEFT" 3 "MIRROR_TILT_RIGHT" 2 "MIRROR_TILT_UP" 1 "MIRROR_TILT_DOWN" 0 "MIRROR_TILT_STOP" ;
VAL_ 962 VCLEFT_frontSeatTrackBack 3 "SWITCH_FAULT" 2 "SWITCH_ON" 1 "SWITCH_OFF" 0 "SWITCH_SNA" ;
VAL_ 962 VCLEFT_frontSeatTrackForward 3 "SWITCH_FAULT" 2 "SWITCH_ON" 1 "SWITCH_OFF" 0 "SWITCH_SNA" ;
VAL_ 962 VCLEFT_frontSeatTiltDown 3 "SWITCH_FAULT" 2 "SWITCH_ON" 1 "SWITCH_OFF" 0 "SWITCH_SNA" ;
VAL_ 962 VCLEFT_frontSeatTiltUp 3 "SWITCH_FAULT" 2 "SWITCH_ON" 1 "SWITCH_OFF" 0 "SWITCH_SNA" ;
VAL_ 962 VCLEFT_frontSeatLiftDown 3 "SWITCH_FAULT" 2 "SWITCH_ON" 1 "SWITCH_OFF" 0 "SWITCH_SNA" ;
VAL_ 962 VCLEFT_frontSeatLiftUp 3 "SWITCH_FAULT" 2 "SWITCH_ON" 1 "SWITCH_OFF" 0 "SWITCH_SNA" ;
VAL_ 962 VCLEFT_frontSeatBackrestBack 3 "SWITCH_FAULT" 2 "SWITCH_ON" 1 "SWITCH_OFF" 0 "SWITCH_SNA" ;
VAL_ 962 VCLEFT_frontSeatBackrestForward 3 "SWITCH_FAULT" 2 "SWITCH_ON" 1 "SWITCH_OFF" 0 "SWITCH_SNA" ;
VAL_ 962 VCLEFT_frontSeatLumbarDown 3 "SWITCH_FAULT" 2 "SWITCH_ON" 1 "SWITCH_OFF" 0 "SWITCH_SNA" ;
VAL_ 962 VCLEFT_frontSeatLumbarUp 3 "SWITCH_FAULT" 2 "SWITCH_ON" 1 "SWITCH_OFF" 0 "SWITCH_SNA" ;
VAL_ 962 VCLEFT_frontSeatLumbarIn 3 "SWITCH_FAULT" 2 "SWITCH_ON" 1 "SWITCH_OFF" 0 "SWITCH_SNA" ;
VAL_ 962 VCLEFT_frontSeatLumbarOut 3 "SWITCH_FAULT" 2 "SWITCH_ON" 1 "SWITCH_OFF" 0 "SWITCH_SNA" ;
VAL_ 962 VCLEFT_frontBuckleSwitch 3 "SWITCH_FAULT" 2 "SWITCH_ON" 1 "SWITCH_OFF" 0 "SWITCH_SNA" ;
VAL_ 962 VCLEFT_frontOccupancySwitch 3 "SWITCH_FAULT" 2 "SWITCH_ON" 1 "SWITCH_OFF" 0 "SWITCH_SNA" ;
VAL_ 962 VCLEFT_rearLeftBuckleSwitch 3 "SWITCH_FAULT" 2 "SWITCH_ON" 1 "SWITCH_OFF" 0 "SWITCH_SNA" ;
VAL_ 962 VCLEFT_rearCenterOccupancySwitch 3 "SWITCH_FAULT" 2 "SWITCH_ON" 1 "SWITCH_OFF" 0 "SWITCH_SNA" ;
VAL_ 962 VCLEFT_rearLeftOccupancySwitch 3 "SWITCH_FAULT" 2 "SWITCH_ON" 1 "SWITCH_OFF" 0 "SWITCH_SNA" ;
VAL_ 962 VCLEFT_rearRightOccupancySwitch 3 "SWITCH_FAULT" 2 "SWITCH_ON" 1 "SWITCH_OFF" 0 "SWITCH_SNA" ;
VAL_ 962 VCLEFT_rearCenterBuckleSwitch 3 "SWITCH_FAULT" 2 "SWITCH_ON" 1 "SWITCH_OFF" 0 "SWITCH_SNA" ;
VAL_ 962 VCLEFT_swcLeftTiltRight 3 "SWITCH_FAULT" 2 "SWITCH_ON" 1 "SWITCH_OFF" 0 "SWITCH_SNA" ;
VAL_ 962 VCLEFT_swcLeftPressed 3 "SWITCH_FAULT" 2 "SWITCH_ON" 1 "SWITCH_OFF" 0 "SWITCH_SNA" ;
VAL_ 962 VCLEFT_swcRightTiltLeft 3 "SWITCH_FAULT" 2 "SWITCH_ON" 1 "SWITCH_OFF" 0 "SWITCH_SNA" ;
VAL_ 962 VCLEFT_swcRightTiltRight 3 "SWITCH_FAULT" 2 "SWITCH_ON" 1 "SWITCH_OFF" 0 "SWITCH_SNA" ;
VAL_ 962 VCLEFT_swcRightPressed 3 "SWITCH_FAULT" 2 "SWITCH_ON" 1 "SWITCH_OFF" 0 "SWITCH_SNA" ;
VAL_ 962 VCLEFT_swcLeftTiltLeft 3 "SWITCH_FAULT" 2 "SWITCH_ON" 1 "SWITCH_OFF" 0 "SWITCH_SNA" ;
VAL_ 962 VCLEFT_swcWiperButtonState 3 "FAULT" 2 "HARD_PRESS" 1 "SOFT_PRESS" 0 "INACTIVE" ;
VAL_ 962 VCLEFT_swcTurnSignalLeftButtonSt 3 "FAULT" 2 "HARD_PRESS" 1 "SOFT_PRESS" 0 "INACTIVE" ;
VAL_ 962 VCLEFT_swcTurnSignalRightButtonS 3 "FAULT" 2 "HARD_PRESS" 1 "SOFT_PRESS" 0 "INACTIVE" ;
VAL_ 962 VCLEFT_swcHighBeamButtonState 3 "FAULT" 2 "HARD_PRESS" 1 "SOFT_PRESS" 0 "INACTIVE" ;
VAL_ 962 VCLEFT_swcVoiceControlPress 3 "SWITCH_FAULT" 2 "SWITCH_ON" 1 "SWITCH_OFF" 0 "SWITCH_SNA" ;
VAL_ 962 VCLEFT_swcCameraButtonState 3 "FAULT" 2 "HARD_PRESS" 1 "SOFT_PRESS" 0 "INACTIVE" ;
VAL_ 962 VCLEFT_swcRightPressedQF 1 "VALID" 0 "INVALID" ;
VAL_ 962 VCLEFT_2RowSeatReclineSwitchpack 6 "FAULT" 5 "REARWARD_FAST" 4 "REARWARD_SLOW" 3 "FORWARD_FAST" 2 "FORWARD_SLOW" 1 "INACTIVE" 0 "DISCONNECTED" ;
VAL_ 962 VCLEFT_3RowLeftBuckleSwitch 3 "SWITCH_FAULT" 2 "SWITCH_ON" 1 "SWITCH_OFF" 0 "SWITCH_SNA" ;
VAL_ 962 VCLEFT_frontSeatThighSupportExte 3 "SWITCH_FAULT" 2 "SWITCH_ON" 1 "SWITCH_OFF" 0 "SWITCH_SNA" ;
VAL_ 962 VCLEFT_frontSeatThighSupportRetr 3 "SWITCH_FAULT" 2 "SWITCH_ON" 1 "SWITCH_OFF" 0 "SWITCH_SNA" ;
VAL_ 962 VCLEFT_frontSeatResistiveOccupan 3 "SWITCH_FAULT" 2 "SWITCH_ON" 1 "SWITCH_OFF" 0 "SWITCH_SNA" ;
VAL_ 656 VCLEFT_hvac2RLeftLateralCalibrat 1 "CALIBRATED" 0 "NOT_CALIBRATED" ;
VAL_ 656 VCLEFT_hvac2RLeftVerticalCalibra 1 "CALIBRATED" 0 "NOT_CALIBRATED" ;
VAL_ 656 VCLEFT_hvac2RRightLateralCalibra 1 "CALIBRATED" 0 "NOT_CALIBRATED" ;
VAL_ 656 VCLEFT_hvac2RRightVerticalCalibr 1 "CALIBRATED" 0 "NOT_CALIBRATED" ;
VAL_ 656 VCLEFT_hvac2RLeftLateralState 11 "HVAC_ACTUATOR_BRUSHED_STATE_RUNNING_OVERSHOOT" 10 "HVAC_ACTUATOR_BRUSHED_STATE_NEGATIVE_BACKOFF" 9 "HVAC_ACTUATOR_BRUSHED_STATE_POSITIVE_BACKOFF" 8 "HVAC_ACTUATOR_BRUSHED_STATE_CONTROL_DISABLED" 7 "HVAC_ACTUATOR_BRUSHED_STATE_FAULT" 6 "HVAC_ACTUATOR_BRUSHED_STATE_BRAKING" 5 "HVAC_ACTUATOR_BRUSHED_STATE_RUNNING" 4 "HVAC_ACTUATOR_BRUSHED_STATE_NEGATIVE_STALL" 3 "HVAC_ACTUATOR_BRUSHED_STATE_NEGATIVE_RUN" 2 "HVAC_ACTUATOR_BRUSHED_STATE_POSITIVE_STALL" 1 "HVAC_ACTUATOR_BRUSHED_STATE_POSITIVE_RUN" 0 "HVAC_ACTUATOR_BRUSHED_STATE_INIT" ;
VAL_ 656 VCLEFT_hvac2RLeftVerticalState 11 "HVAC_ACTUATOR_BRUSHED_STATE_RUNNING_OVERSHOOT" 10 "HVAC_ACTUATOR_BRUSHED_STATE_NEGATIVE_BACKOFF" 9 "HVAC_ACTUATOR_BRUSHED_STATE_POSITIVE_BACKOFF" 8 "HVAC_ACTUATOR_BRUSHED_STATE_CONTROL_DISABLED" 7 "HVAC_ACTUATOR_BRUSHED_STATE_FAULT" 6 "HVAC_ACTUATOR_BRUSHED_STATE_BRAKING" 5 "HVAC_ACTUATOR_BRUSHED_STATE_RUNNING" 4 "HVAC_ACTUATOR_BRUSHED_STATE_NEGATIVE_STALL" 3 "HVAC_ACTUATOR_BRUSHED_STATE_NEGATIVE_RUN" 2 "HVAC_ACTUATOR_BRUSHED_STATE_POSITIVE_STALL" 1 "HVAC_ACTUATOR_BRUSHED_STATE_POSITIVE_RUN" 0 "HVAC_ACTUATOR_BRUSHED_STATE_INIT" ;
VAL_ 656 VCLEFT_hvac2RRightLateralState 11 "HVAC_ACTUATOR_BRUSHED_STATE_RUNNING_OVERSHOOT" 10 "HVAC_ACTUATOR_BRUSHED_STATE_NEGATIVE_BACKOFF" 9 "HVAC_ACTUATOR_BRUSHED_STATE_POSITIVE_BACKOFF" 8 "HVAC_ACTUATOR_BRUSHED_STATE_CONTROL_DISABLED" 7 "HVAC_ACTUATOR_BRUSHED_STATE_FAULT" 6 "HVAC_ACTUATOR_BRUSHED_STATE_BRAKING" 5 "HVAC_ACTUATOR_BRUSHED_STATE_RUNNING" 4 "HVAC_ACTUATOR_BRUSHED_STATE_NEGATIVE_STALL" 3 "HVAC_ACTUATOR_BRUSHED_STATE_NEGATIVE_RUN" 2 "HVAC_ACTUATOR_BRUSHED_STATE_POSITIVE_STALL" 1 "HVAC_ACTUATOR_BRUSHED_STATE_POSITIVE_RUN" 0 "HVAC_ACTUATOR_BRUSHED_STATE_INIT" ;
VAL_ 656 VCLEFT_hvac2RRightVerticalState 11 "HVAC_ACTUATOR_BRUSHED_STATE_RUNNING_OVERSHOOT" 10 "HVAC_ACTUATOR_BRUSHED_STATE_NEGATIVE_BACKOFF" 9 "HVAC_ACTUATOR_BRUSHED_STATE_POSITIVE_BACKOFF" 8 "HVAC_ACTUATOR_BRUSHED_STATE_CONTROL_DISABLED" 7 "HVAC_ACTUATOR_BRUSHED_STATE_FAULT" 6 "HVAC_ACTUATOR_BRUSHED_STATE_BRAKING" 5 "HVAC_ACTUATOR_BRUSHED_STATE_RUNNING" 4 "HVAC_ACTUATOR_BRUSHED_STATE_NEGATIVE_STALL" 3 "HVAC_ACTUATOR_BRUSHED_STATE_NEGATIVE_RUN" 2 "HVAC_ACTUATOR_BRUSHED_STATE_POSITIVE_STALL" 1 "HVAC_ACTUATOR_BRUSHED_STATE_POSITIVE_RUN" 0 "HVAC_ACTUATOR_BRUSHED_STATE_INIT" ;
VAL_ 656 VCLEFT_vcusbLinSchedule 3 "VCUSB_LIN_SCHEDULE_COUNT" 2 "VCUSB_LIN_SCHEDULE_DIAGNOSTIC" 1 "VCUSB_LIN_SCHEDULE_COMMAND_AND_RESPONSE" 0 "VCUSB_LIN_SCHEDULE_OFF" ;
VAL_ 656 VCLEFT_hvacBlowerArbState 6 "ARBITRATOR_FAULTED" 5 "ARBITRATOR_COMPLETED" 4 "ARBITRATOR_REQUEST_CURRENT" 3 "ARBITRATOR_WAIT_BEFORE_REQUEST" 2 "ARBITRATOR_HIGH_FREQ_VOLT_INJECTION" 1 "ARBITRATOR_READY" 0 "ARBITRATOR_NOT_READY" ;
VAL_ 656 VCLEFT_hvacBlowerArbResult 2 "VC_MOTOR_ID_BOSCH" 1 "VC_MOTOR_ID_DELTA" 0 "VC_MOTOR_ID_UNKNOWN" ;
VAL_ 706 VCLEFT_windowStateLF 10 "WINDOW_STATE_SHORT_RISE_REVERSE" 9 "WINDOW_STATE_SHORT_RISE" 8 "WINDOW_STATE_BACKDRIVE" 7 "WINDOW_STATE_MOVING_AUTO_DOWN" 6 "WINDOW_STATE_MOVING_AUTO_UP" 5 "WINDOW_STATE_SHORT_DROP_REVERSE" 4 "WINDOW_STATE_SHORT_DROP" 3 "WINDOW_STATE_BACKOFF" 2 "WINDOW_STATE_MOVING_DOWN" 1 "WINDOW_STATE_MOVING_UP" 0 "WINDOW_STATE_STOPPED" ;
VAL_ 706 VCLEFT_windowTrimClearMoveReques 3 "WINDOW_TRIM_CLEAR_MOVE_REQUEST_BACKDRIVE" 2 "WINDOW_TRIM_CLEAR_MOVE_REQUEST_RESEAL" 1 "WINDOW_TRIM_CLEAR_MOVE_REQUEST_IDLE" 0 "WINDOW_TRIM_CLEAR_MOVE_REQUEST_SNA" ;
VAL_ 706 VCLEFT_windowTrimClearActiveRequ 2 "WINDOW_TRIM_CLEAR_ACTIVE_REQUEST_ACTIVE" 1 "WINDOW_TRIM_CLEAR_ACTIVE_REQUEST_INACTIVE" 0 "WINDOW_TRIM_CLEAR_ACTIVE_REQUEST_SNA" ;
VAL_ 706 VCLEFT_windowStateLR 10 "WINDOW_STATE_SHORT_RISE_REVERSE" 9 "WINDOW_STATE_SHORT_RISE" 8 "WINDOW_STATE_BACKDRIVE" 7 "WINDOW_STATE_MOVING_AUTO_DOWN" 6 "WINDOW_STATE_MOVING_AUTO_UP" 5 "WINDOW_STATE_SHORT_DROP_REVERSE" 4 "WINDOW_STATE_SHORT_DROP" 3 "WINDOW_STATE_BACKOFF" 2 "WINDOW_STATE_MOVING_DOWN" 1 "WINDOW_STATE_MOVING_UP" 0 "WINDOW_STATE_STOPPED" ;
VAL_ 706 VCLEFT_windowThermalModeLF 3 "WINDOW_THERMAL_MODE_CRITICAL" 2 "WINDOW_THERMAL_MODE_ALERT" 1 "WINDOW_THERMAL_MODE_NORMAL" 0 "WINDOW_THERMAL_MODE_SNA" ;
VAL_ 706 VCLEFT_windowStopReasonLF 6 "WINDOW_STOP_REASON_STATE_TIMEOUT" 5 "WINDOW_STOP_REASON_FULL_OPEN_SOFT_STOP" 4 "WINDOW_STOP_REASON_STOP_REQUEST" 3 "WINDOW_STOP_REASON_TARGET_REACHED" 2 "WINDOW_STOP_REASON_NEW_REQUEST" 1 "WINDOW_STOP_REASON_DOOR_OPEN_TRIM_PROTECT" 0 "WINDOW_STOP_REASON_NONE" ;
VAL_ 706 VCLEFT_windowStopReqReasonLF 8 "WINDOW_STOP_REQUEST_REASON_EXTERNAL_REQUEST" 7 "WINDOW_STOP_REQUEST_REASON_FULL_OPEN_SOFT_STOP" 6 "WINDOW_STOP_REQUEST_REASON_STATE_TIMEOUT" 5 "WINDOW_STOP_REQUEST_REASON_STALL" 4 "WINDOW_STOP_REQUEST_REASON_THERMAL" 3 "WINDOW_STOP_REQUEST_REASON_REAR_LOCKOUT" 2 "WINDOW_STOP_REQUEST_REASON_SWITCH_RELEASED" 1 "WINDOW_STOP_REQUEST_REASON_SWITCH_CANCEL_AUTO_MOVEMENT" 0 "WINDOW_STOP_REQUEST_REASON_NONE" ;
VAL_ 706 VCLEFT_windowThermalModeLR 3 "WINDOW_THERMAL_MODE_CRITICAL" 2 "WINDOW_THERMAL_MODE_ALERT" 1 "WINDOW_THERMAL_MODE_NORMAL" 0 "WINDOW_THERMAL_MODE_SNA" ;
VAL_ 706 VCLEFT_windowStopReasonLR 6 "WINDOW_STOP_REASON_STATE_TIMEOUT" 5 "WINDOW_STOP_REASON_FULL_OPEN_SOFT_STOP" 4 "WINDOW_STOP_REASON_STOP_REQUEST" 3 "WINDOW_STOP_REASON_TARGET_REACHED" 2 "WINDOW_STOP_REASON_NEW_REQUEST" 1 "WINDOW_STOP_REASON_DOOR_OPEN_TRIM_PROTECT" 0 "WINDOW_STOP_REASON_NONE" ;
VAL_ 706 VCLEFT_windowStopReqReasonLR 8 "WINDOW_STOP_REQUEST_REASON_EXTERNAL_REQUEST" 7 "WINDOW_STOP_REQUEST_REASON_FULL_OPEN_SOFT_STOP" 6 "WINDOW_STOP_REQUEST_REASON_STATE_TIMEOUT" 5 "WINDOW_STOP_REQUEST_REASON_STALL" 4 "WINDOW_STOP_REQUEST_REASON_THERMAL" 3 "WINDOW_STOP_REQUEST_REASON_REAR_LOCKOUT" 2 "WINDOW_STOP_REQUEST_REASON_SWITCH_RELEASED" 1 "WINDOW_STOP_REQUEST_REASON_SWITCH_CANCEL_AUTO_MOVEMENT" 0 "WINDOW_STOP_REQUEST_REASON_NONE" ;
VAL_ 706 VCLEFT_windowControlStateLF 2 "WINDOW_CONTROL_STATE_GOING_TO_POSITION" 1 "WINDOW_CONTROL_STATE_CLOSING" 0 "WINDOW_CONTROL_STATE_IDLE" ;
VAL_ 706 VCLEFT_windowCtrlUnavailableLF 7 "WINDOW_CONTROL_UNAVAILABLE_REASON_WINDOW_MOVING" 6 "WINDOW_CONTROL_UNAVAILABLE_REASON_VEHICLE_IN_DRIVE" 5 "WINDOW_CONTROL_UNAVAILABLE_REASON_UNCALIBRATED" 4 "WINDOW_CONTROL_UNAVAILABLE_REASON_THERMAL_LIMIT" 3 "WINDOW_CONTROL_UNAVAILABLE_REASON_PINCH" 2 "WINDOW_CONTROL_UNAVAILABLE_REASON_SWITCH_PRESSED" 1 "WINDOW_CONTROL_UNAVAILABLE_REASON_UNEXPECTED" 0 "WINDOW_CONTROL_UNAVAILABLE_REASON_NONE" ;
VAL_ 706 VCLEFT_windowControlStateLR 2 "WINDOW_CONTROL_STATE_GOING_TO_POSITION" 1 "WINDOW_CONTROL_STATE_CLOSING" 0 "WINDOW_CONTROL_STATE_IDLE" ;
VAL_ 706 VCLEFT_windowCtrlUnavailableLR 7 "WINDOW_CONTROL_UNAVAILABLE_REASON_WINDOW_MOVING" 6 "WINDOW_CONTROL_UNAVAILABLE_REASON_VEHICLE_IN_DRIVE" 5 "WINDOW_CONTROL_UNAVAILABLE_REASON_UNCALIBRATED" 4 "WINDOW_CONTROL_UNAVAILABLE_REASON_THERMAL_LIMIT" 3 "WINDOW_CONTROL_UNAVAILABLE_REASON_PINCH" 2 "WINDOW_CONTROL_UNAVAILABLE_REASON_SWITCH_PRESSED" 1 "WINDOW_CONTROL_UNAVAILABLE_REASON_UNEXPECTED" 0 "WINDOW_CONTROL_UNAVAILABLE_REASON_NONE" ;
VAL_ 706 VCLEFT_windowPositionStateLF 7 "WINDOW_POSITION_CLOSED_TRIM_CLEAR" 6 "WINDOW_POSITION_FULL_OPEN" 5 "WINDOW_POSITION_PARTIAL_OPEN" 4 "WINDOW_POSITION_DAS_LIMITED" 3 "WINDOW_POSITION_VENT" 2 "WINDOW_POSITION_CRACKED" 1 "WINDOW_POSITION_CLOSED" 0 "WINDOW_POSITION_UNKNOWN" ;
VAL_ 706 VCLEFT_windowPositionStateLR 7 "WINDOW_POSITION_CLOSED_TRIM_CLEAR" 6 "WINDOW_POSITION_FULL_OPEN" 5 "WINDOW_POSITION_PARTIAL_OPEN" 4 "WINDOW_POSITION_DAS_LIMITED" 3 "WINDOW_POSITION_VENT" 2 "WINDOW_POSITION_CRACKED" 1 "WINDOW_POSITION_CLOSED" 0 "WINDOW_POSITION_UNKNOWN" ;
VAL_ 706 VCLEFT_windowVehGearStateLF 2 "WINDOW_VEHICLE_GEAR_STATE_IN_GEAR" 1 "WINDOW_VEHICLE_GEAR_STATE_PARK" 0 "WINDOW_VEHICLE_GEAR_STATE_UNKNOWN_SNA" ;
VAL_ 706 VCLEFT_windowVehGearStateLR 2 "WINDOW_VEHICLE_GEAR_STATE_IN_GEAR" 1 "WINDOW_VEHICLE_GEAR_STATE_PARK" 0 "WINDOW_VEHICLE_GEAR_STATE_UNKNOWN_SNA" ;
VAL_ 706 VCLEFT_windowSpeedTableStatusLF 2 "WINDOW_SPEED_TABLE_STATUS_FULLY_BUILT" 1 "WINDOW_SPEED_TABLE_STATUS_SENSITIVE_BUILT" 0 "WINDOW_SPEED_TABLE_STATUS_EMPTY_SNA" ;
VAL_ 706 VCLEFT_windowSpeedTableStatusLR 2 "WINDOW_SPEED_TABLE_STATUS_FULLY_BUILT" 1 "WINDOW_SPEED_TABLE_STATUS_SENSITIVE_BUILT" 0 "WINDOW_SPEED_TABLE_STATUS_EMPTY_SNA" ;
VAL_ 1114 VCRIGHT_AP_hvacModelInitStatus 5 "INIT_WAITING_FOR_SENSORS" 4 "INIT_FORWARD_CALC" 3 "INIT_FROM_SENSORS_PREDICTION_ERROR" 2 "INIT_FROM_SENSORS" 1 "NOT_INIT_WAIT_FOR_GTW" 0 "NOT_INIT_WAIT_FOR_SENSORS" ;
VAL_ 1114 VCRIGHT_AP_hvacAirDistributionMo 7 "DEFROST_PANEL_FLOOR" 6 "DEFROST_PANEL" 5 "DEFROST_FLOOR" 4 "DEFROST" 3 "PANEL_FLOOR" 2 "PANEL" 1 "FLOOR" 0 "NONE" ;
VAL_ 1114 VCRIGHT_AP_cameraDefogType 4 "TWO_CAMERA_PLUS_FAN" 3 "GLARESHIELD_HEATER_PLUS_FAN" 2 "CMD" 1 "CAMERA" 0 "NONE" ;
VAL_ 1114 VCRIGHT_ah_defogSystemState 7 "DEFOG_SYS_SNA" 6 "DEFOG_SYS_UNHEALTHY" 5 "DEFOG_SYS_HEALTHY_DEGRADED" 4 "DEFOG_SYS_HEALTHY" 3 "DEFOG_SYS_HEALTHY_REEVALUATING" 2 "DEFOG_SYS_EVALUATING_PRECONDITIONING" 1 "DEFOG_SYS_EVALUATING_HARDWARE" 0 "DEFOG_SYS_INIT" ;
VAL_ 1114 VCRIGHT_AP_turnForwardCameraHeat 15 "TURN_ON_REASON_MANUAL_FOGGING_HAMMER" 14 "TURN_ON_REASON_MANUAL_DEFOG_DEFROST" 13 "TURN_ON_REASON_MANUAL_HVAC_CONTROL" 12 "TURN_ON_REASON_HVAC_SYSTEM_NOT_NOMINAL" 11 "TURN_ON_REASON_WET_EVAP_STARTUP" 10 "TURN_ON_REASON_GLARESHIELD_PRECONDITIONING" 9 "TURN_ON_REASON_ROBOTAXI_PRECONDITIONING" 8 "TURN_ON_REASON_LOSS_OF_DEHUMIDIFICATION" 7 "TURN_ON_REASON_EXTERNAL_DEW_LIKELY" 6 "TURN_ON_REASON_FLASH_FOGGING" 5 "TURN_ON_REASON_COMPRESSOR_OFF" 4 "TURN_ON_REASON_START_OF_COLD_DRIVE" 3 "TURN_ON_REASON_RADIATOR_STEAMING" 2 "TURN_ON_REASON_EVAP_UNAVAILABLE" 1 "TURN_ON_REASON_EVAP_JUST_TURNED_OFF" 0 "TURN_ON_REASON_NONE" ;
VAL_ 1114 VCRIGHT_AP_turnCameraFanOffReaso 7 "TURN_OFF_REASON_CABIN_HUMIDITY" 6 "TURN_OFF_REASON_EVAP_CONTROLS_COMPROMISED" 5 "TURN_OFF_REASON_FLASH_FOGGING" 4 "TURN_OFF_REASON_VOC_CONCENTRATION_HIGH" 3 "TURN_OFF_REASON_START_OF_COLD_DRIVE" 2 "TURN_OFF_REASON_RADIATOR_STEAMING" 1 "TURN_OFF_REASON_EVAP_JUST_TURNED_OFF" 0 "TURN_OFF_REASON_NONE" ;
VAL_ 1124 VCRIGHT_AP_humidityModelInitStat 21 "INIT_STATUS_LIMP_FORWARD_CALC_AMBIENT_PROBE_AND_THS" 20 "INIT_STATUS_LIMP_FORWARD_CALC_WEATHER_PROBE_AND_THS" 19 "INIT_STATUS_LIMP_FORWARD_CALC_PROBE_AND_THS" 18 "INIT_STATUS_LIMP_FORWARD_CALC_AMBIENT_AND_THS" 17 "INIT_STATUS_LIMP_FORWARD_CALC_WEATHER_AND_THS" 16 "INIT_STATUS_LIMP_FORWARD_CALC_THS_ONLY" 15 "INIT_STATUS_LIMP_FORWARD_CALC_AMBIENT_AND_PROBE" 14 "INIT_STATUS_LIMP_FORWARD_CALC_WEATHER_AND_PROBE" 13 "INIT_STATUS_LIMP_FORWARD_CALC_PROBE_ONLY" 12 "INIT_STATUS_LIMP_FORWARD_CALC_AMBIENT_ONLY" 11 "INIT_STATUS_LIMP_FORWARD_CALC_WEATHER_ONLY" 10 "INIT_STATUS_LIMP_FROM_SENSORS_PROBE_ONLY" 9 "INIT_STATUS_FROM_FORWARD_CALC" 8 "INIT_STATUS_FROM_SENSORS" 7 "INIT_STATUS_FAULTED_MULTI_CYCLE_SENSOR_INVALID" 6 "INIT_STATUS_FAULTED_ALL_INVALID" 5 "INIT_STATUS_FAULTED_FORWARD_CALC_WEATHER_AND_AMBIENT_INVALID" 4 "INIT_STATUS_FAULTED_FROM_SENSORS_THS_INVALID" 3 "INIT_STATUS_WAITING_FOR_SENSORS_API" 2 "INIT_STATUS_WAITING_FOR_CABIN_MODEL_INIT" 1 "INIT_STATUS_WAITING_FOR_GTW" 0 "INIT_STATUS_UNKNOWN" ;
VAL_ 1124 VCRIGHT_AP_humidityModelStatus 19 "STATUS_RUNNING_FAULTED_WEATHER_AND_AMBIENT_INVALID" 18 "STATUS_RUNNING_LIMP_THS_DIRECTLY_NO_PROBE_LIMIT" 17 "STATUS_RUNNING_LIMP_THS_DIRECTLY_WITH_PROBE_LIMIT" 16 "STATUS_RUNNING_LIMP_THS_ONLY_SUBSTITUTED" 15 "STATUS_RUNNING_LIMP_AMBIENT_AND_PROBE_SUBSTITUTED_NO_THS_FEEDBACK" 14 "STATUS_RUNNING_LIMP_WEATHER_AND_PROBE_SUBSTITUTED_NO_THS_FEEDBACK" 13 "STATUS_RUNNING_LIMP_AMBIENT_AND_PROBE_SUBSTITUTED_WITH_THS_FEEDBACK" 12 "STATUS_RUNNING_LIMP_WEATHER_AND_PROBE_SUBSTITUTED_WITH_THS_FEEDBACK" 11 "STATUS_RUNNING_LIMP_EVAP_SUBSTITUTED_NO_THS_FEEDBACK" 10 "STATUS_RUNNING_LIMP_PROBE_SUBSTITUTED_NO_THS_FEEDBACK" 9 "STATUS_RUNNING_LIMP_AMBIENT_SUBSTITUTED_NO_THS_FEEDBACK" 8 "STATUS_RUNNING_LIMP_WEATHER_SUBSTITUTED_NO_THS_FEEDBACK" 7 "STATUS_RUNNING_LIMP_EVAP_SUBSTITUTED_WITH_THS_FEEDBACK" 6 "STATUS_RUNNING_LIMP_PROBE_SUBSTITUTED_WITH_THS_FEEDBACK" 5 "STATUS_RUNNING_LIMP_AMBIENT_SUBSTITUTED_WITH_THS_FEEDBACK" 4 "STATUS_RUNNING_LIMP_WEATHER_SUBSTITUTED_WITH_THS_FEEDBACK" 3 "STATUS_RUNNING_RECOVERED_CATCHUP" 2 "STATUS_RUNNING_PAUSED_AWAITING_RECOVERY" 1 "STATUS_RUNNING_NOMINAL" 0 "STATUS_UNKNOWN" ;
VAL_ 549 VCRIGHT_ptcLVState 3 "LV_FAULT" 2 "LV_GOING_DOWN" 1 "LV_ON" 0 "LV_OFF" ;
VAL_ 549 VCRIGHT_ocsLVState 3 "LV_FAULT" 2 "LV_GOING_DOWN" 1 "LV_ON" 0 "LV_OFF" ;
VAL_ 549 VCRIGHT_premAudioLVState 3 "LV_FAULT" 2 "LV_GOING_DOWN" 1 "LV_ON" 0 "LV_OFF" ;
VAL_ 549 VCRIGHT_rearOilPumpLVState 3 "LV_FAULT" 2 "LV_GOING_DOWN" 1 "LV_ON" 0 "LV_OFF" ;
VAL_ 549 VCRIGHT_tunerLVState 3 "LV_FAULT" 2 "LV_GOING_DOWN" 1 "LV_ON" 0 "LV_OFF" ;
VAL_ 549 VCRIGHT_hvcLVState 3 "LV_FAULT" 2 "LV_GOING_DOWN" 1 "LV_ON" 0 "LV_OFF" ;
VAL_ 549 VCRIGHT_rcmLVState 3 "LV_FAULT" 2 "LV_GOING_DOWN" 1 "LV_ON" 0 "LV_OFF" ;
VAL_ 549 VCRIGHT_lumbarLVState 3 "LV_FAULT" 2 "LV_GOING_DOWN" 1 "LV_ON" 0 "LV_OFF" ;
VAL_ 549 VCRIGHT_eFuseLockoutStatus 2 "EFUSE_LOCKOUT_STATUS_ACTIVE" 1 "EFUSE_LOCKOUT_STATUS_PENDING" 0 "EFUSE_LOCKOUT_STATUS_IDLE" ;
VAL_ 549 VCRIGHT_vehiclePowerStateDBG 3 "VEHICLE_POWER_STATE_DRIVE" 2 "VEHICLE_POWER_STATE_ACCESSORY" 1 "VEHICLE_POWER_STATE_CONDITIONING" 0 "VEHICLE_POWER_STATE_OFF" ;
VAL_ 549 VCRIGHT_parkLVState 3 "LV_FAULT" 2 "LV_GOING_DOWN" 1 "LV_ON" 0 "LV_OFF" ;
VAL_ 549 VCRIGHT_icrLVState 3 "LV_FAULT" 2 "LV_GOING_DOWN" 1 "LV_ON" 0 "LV_OFF" ;
VAL_ 549 VCRIGHT_interiorCameraLedLVState 3 "LV_FAULT" 2 "LV_GOING_DOWN" 1 "LV_ON" 0 "LV_OFF" ;
VAL_ 549 VCRIGHT_diLVState 3 "LV_FAULT" 2 "LV_GOING_DOWN" 1 "LV_ON" 0 "LV_OFF" ;
VAL_ 643 VCRIGHT_PTCRequestMode 4 "SEQ_ROD_CIO" 3 "SEQ_ROD_COI" 2 "DIRECT" 1 "DUTY" 0 "POWER" ;
